// *************************************************************************** *
// *                                                                           *
// *                      Mentor Graphics Corporation                          *
// *                          All rights reserved                              *
// *                                                                           *
// *************************************************************************** *
// *                                                                           *
// * Description:         Partial CANDB File (for ADD Node)                    *
// * Generated at:        2024-09-06 15:47                                     *
// * Node                 ADD                                                  *
// *                                                                           *
// *************************************************************************** *
// *                                                                           *
// *             THIS CONFIGURATION MIGHT CONTAIN SOME ERRORS                  *
// *              IF THE INPUT MODEL WAS NOT PROPERLY FORMED!                  *
// *                    Do Not Use this File directly!                         *
// *                                                                           *
// *************************************************************************** *
VERSION "ADD"

NS_ :

BS_ :

BU_ : ADD

BO_ 1327 ADDAdasCanfdNMFrb : 8 ADD
 SG_ ADDCANActiveWakeup1 : 12|1@0+ (1,0) [0|1] "" Vector__XXX
 SG_ ADDCANNodeAddress1 : 7|8@0+ (1.0,0.0) [0.0|255.0] "" Vector__XXX
 SG_ ADDCANRepeatMsgReq1 : 8|1@0+ (1,0) [0|1] "" Vector__XXX
 SG_ ADDCANRepeatMsgSt1 : 16|1@0+ (1,0) [0|1] "" Vector__XXX
 SG_ NMKeepAwkRsnADD : 48|9@0+ (1.0,0.0) [0.0|511.0] "" Vector__XXX
 SG_ UDB17ADD : 17|1@0+ (1.0,0.0) [0.0|1.0] "" Vector__XXX
 SG_ UDB18ADD : 18|1@0+ (1,0) [0|1] "" Vector__XXX
 SG_ UDB19ADD : 19|1@0+ (1,0) [0|1] "" Vector__XXX
 SG_ UDB20ADD : 20|1@0+ (1,0) [0|1] "" Vector__XXX
 SG_ UDB21ADD : 21|1@0+ (1,0) [0|1] "" Vector__XXX
 SG_ UDB22ADD : 22|1@0+ (1,0) [0|1] "" Vector__XXX
 SG_ UDB23ADD : 23|1@0+ (1,0) [0|1] "" Vector__XXX
 SG_ UDB24ADD : 24|1@0+ (1,0) [0|1] "" Vector__XXX
 SG_ UDB25ADD : 25|1@0+ (1,0) [0|1] "" Vector__XXX
 SG_ UDB26ADD : 26|1@0+ (1,0) [0|1] "" Vector__XXX
 SG_ UDB27ADD : 27|1@0+ (1,0) [0|1] "" Vector__XXX
 SG_ UDB28ADD : 28|1@0+ (1,0) [0|1] "" Vector__XXX
 SG_ UDB29ADD : 29|1@0+ (1,0) [0|1] "" Vector__XXX
 SG_ UDB30ADD : 30|1@0+ (1,0) [0|1] "" Vector__XXX
 SG_ UDB31ADD : 31|1@0+ (1,0) [0|1] "" Vector__XXX
 SG_ UDB32ADD : 32|1@0+ (1,0) [0|1] "" Vector__XXX
 SG_ UDB33ADD : 33|1@0+ (1,0) [0|1] "" Vector__XXX
 SG_ UDB34ADD : 34|1@0+ (1,0) [0|1] "" Vector__XXX
 SG_ UDB35ADD : 35|1@0+ (1,0) [0|1] "" Vector__XXX
 SG_ UDB36ADD : 36|1@0+ (1.0,0.0) [0.0|1.0] "" Vector__XXX
 SG_ UDB37ADD : 37|1@0+ (1,0) [0|1] "" Vector__XXX
 SG_ UDB38ADD : 38|1@0+ (1,0) [0|1] "" Vector__XXX
 SG_ UDB39ADD : 39|1@0+ (1,0) [0|1] "" Vector__XXX
 SG_ UDB40ADD : 40|1@0+ (1,0) [0|1] "" Vector__XXX
 SG_ UDB41ADD : 41|1@0+ (1,0) [0|1] "" Vector__XXX
 SG_ UDB42ADD : 42|1@0+ (1.0,0.0) [0.0|1.0] "" Vector__XXX
 SG_ UDB43ADD : 43|1@0+ (1,0) [0|1] "" Vector__XXX
 SG_ UDB44ADD : 44|1@0+ (1,0) [0|1] "" Vector__XXX
 SG_ UDB45ADD : 45|1@0+ (1,0) [0|1] "" Vector__XXX
 SG_ UDB46ADD : 46|1@0+ (1,0) [0|1] "" Vector__XXX
 SG_ UDB47ADD : 47|1@0+ (1,0) [0|1] "" Vector__XXX

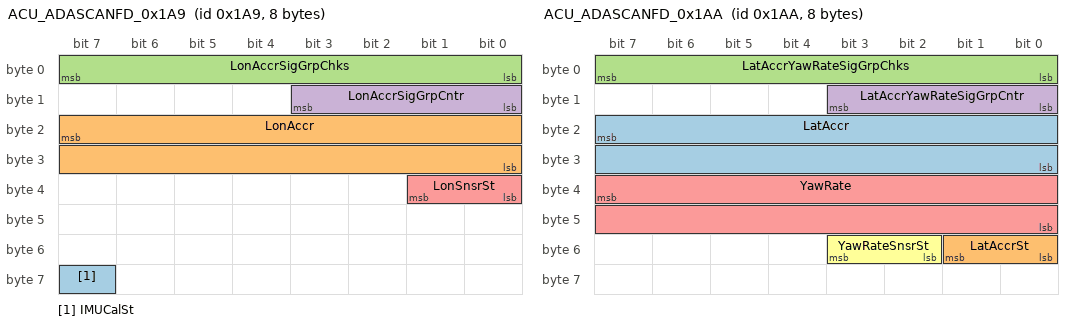
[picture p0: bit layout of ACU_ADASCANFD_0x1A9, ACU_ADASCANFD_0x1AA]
BO_ 425 ACU_ADASCANFD_0x1A9 : 8 Vector__XXX
 SG_ IMUCalSt : 63|1@0+ (1,0) [0|1] "" ADD
 SG_ LonAccr : 23|16@0+ (0.0002,-5.0) [-5.0|5.0] "g" ADD
 SG_ LonAccrSigGrpChks : 7|8@0+ (1,0) [0|255] "" ADD
 SG_ LonAccrSigGrpCntr : 11|4@0+ (1,0) [0|15] "" ADD
 SG_ LonSnsrSt : 33|2@0+ (1,0) [0|3] "" ADD

BO_ 426 ACU_ADASCANFD_0x1AA : 8 Vector__XXX
 SG_ LatAccr : 23|16@0+ (0.0002,-5.0) [-5.0|5.0] "g" ADD
 SG_ LatAccrSt : 49|2@0+ (1,0) [0|3] "" ADD
 SG_ LatAccrYawRateSigGrpChks : 7|8@0+ (1,0) [0|255] "" ADD
 SG_ LatAccrYawRateSigGrpCntr : 11|4@0+ (1,0) [0|15] "" ADD
 SG_ YawRate : 39|16@0+ (0.01,-300.0) [-300.0|300.0] "deg/s" ADD
 SG_ YawRateSnsrSt : 51|2@0+ (1,0) [0|3] "" ADD

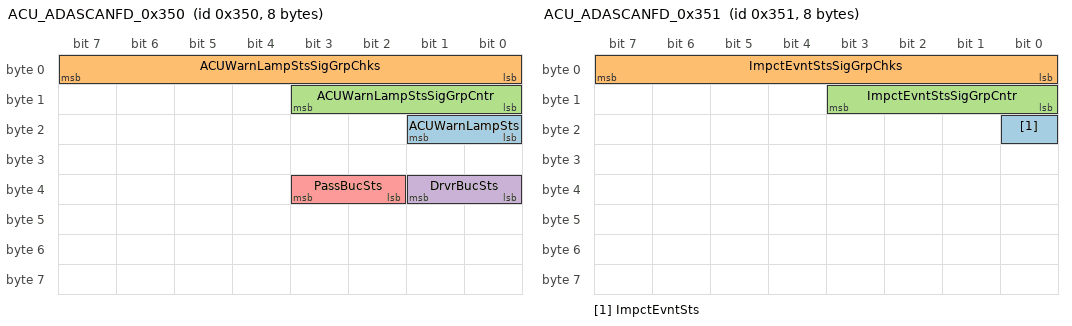
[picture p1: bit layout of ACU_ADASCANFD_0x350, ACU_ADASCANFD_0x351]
BO_ 848 ACU_ADASCANFD_0x350 : 8 Vector__XXX
 SG_ ACUWarnLampSts : 17|2@0+ (1,0) [0|3] "" ADD
 SG_ ACUWarnLampStsSigGrpChks : 7|8@0+ (1.0,0.0) [0.0|255.0] "" ADD
 SG_ ACUWarnLampStsSigGrpCntr : 11|4@0+ (1.0,0.0) [0.0|15.0] "" ADD
 SG_ DrvrBucSts : 33|2@0+ (1,0) [0|3] "" ADD
 SG_ PassBucSts : 35|2@0+ (1,0) [0|3] "" ADD

BO_ 849 ACU_ADASCANFD_0x351 : 8 Vector__XXX
 SG_ ImpctEvntSts : 16|1@0+ (1,0) [0|1] "" ADD
 SG_ ImpctEvntStsSigGrpChks : 7|8@0+ (1,0) [0|255] "" ADD
 SG_ ImpctEvntStsSigGrpCntr : 11|4@0+ (1,0) [0|15] "" ADD

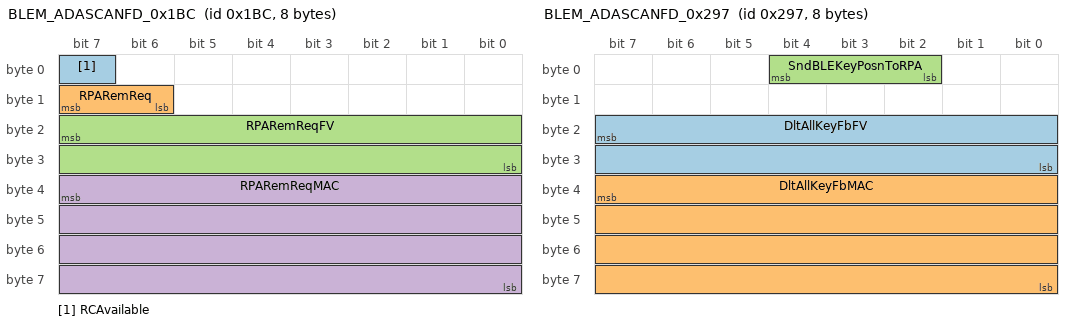
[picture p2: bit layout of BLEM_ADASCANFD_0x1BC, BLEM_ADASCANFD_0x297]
BO_ 444 BLEM_ADASCANFD_0x1BC : 8 Vector__XXX
 SG_ RCAvailable : 7|1@0+ (1,0) [0|1] "" ADD
 SG_ RPARemReq : 15|2@0+ (1,0) [0|3] "" ADD
 SG_ RPARemReqFV : 23|16@0+ (1.0,0.0) [0.0|65535.0] "" ADD
 SG_ RPARemReqMAC : 39|32@0+ (1.0,0.0) [0.0|0.0] "" ADD

BO_ 657 BLEM_ADASCANFD_0x291 : 64 Vector__XXX
 SG_ BLEM2VCCDForLocn10 : 7|32@0+ (1.0,0.0) [0.0|4294967295.0] "" ADD
 SG_ BLEM2VCCDForLocn11 : 39|32@0+ (1.0,0.0) [0.0|4294967295.0] "" ADD
 SG_ BLEM2VCCDForLocn12 : 71|32@0+ (1.0,0.0) [0.0|4294967295.0] "" ADD
 SG_ BLEM2VCCDForLocn13 : 103|32@0+ (1.0,0.0) [0.0|4294967295.0] "" ADD
 SG_ BLEM2VCCDForLocn14 : 135|32@0+ (1.0,0.0) [0.0|4294967295.0] "" ADD
 SG_ BLEM2VCCDForLocn15 : 167|32@0+ (1.0,0.0) [0.0|4294967295.0] "" ADD
 SG_ BLEM2VCCDForLocn16 : 199|32@0+ (1.0,0.0) [0.0|4294967295.0] "" ADD
 SG_ BLEM2VCCDForLocn17 : 231|32@0+ (1.0,0.0) [0.0|4294967295.0] "" ADD
 SG_ BLEM2VCCDForLocn18 : 263|32@0+ (1.0,0.0) [0.0|4294967295.0] "" ADD
 SG_ BLEM2VCCDForLocn19 : 295|32@0+ (1.0,0.0) [0.0|4294967295.0] "" ADD
 SG_ BLEM2VCCDForLocn1A : 327|32@0+ (1.0,0.0) [0.0|4294967295.0] "" ADD
 SG_ BLEM2VCCDForLocn1B : 359|32@0+ (1.0,0.0) [0.0|4294967295.0] "" ADD
 SG_ BLEM2VCCDForLocn1C : 391|32@0+ (1.0,0.0) [0.0|4294967295.0] "" ADD
 SG_ BLEM2VCCDForLocn1D : 423|32@0+ (1.0,0.0) [0.0|4294967295.0] "" ADD
 SG_ BLEM2VCCDForLocn1F : 455|16@0+ (1.0,0.0) [0.0|65535.0] "" ADD

BO_ 663 BLEM_ADASCANFD_0x297 : 8 Vector__XXX
 SG_ DltAllKeyFbFV : 23|16@0+ (1.0,0.0) [0.0|65535.0] "" ADD
 SG_ DltAllKeyFbMAC : 39|32@0+ (1.0,0.0) [0.0|0.0] "" ADD
 SG_ SndBLEKeyPosnToRPA : 4|3@0+ (1,0) [0|7] "" ADD

BO_ 665 BLEM_ADASCANFD_0x299 : 64 Vector__XXX
 SG_ BLEM2VCCDForLocn20 : 7|32@0+ (1.0,0.0) [0.0|4294967295.0] "" ADD
 SG_ BLEM2VCCDForLocn21 : 39|32@0+ (1.0,0.0) [0.0|4294967295.0] "" ADD
 SG_ BLEM2VCCDForLocn22 : 71|32@0+ (1.0,0.0) [0.0|4294967295.0] "" ADD
 SG_ BLEM2VCCDForLocn23 : 103|32@0+ (1.0,0.0) [0.0|4294967295.0] "" ADD
 SG_ BLEM2VCCDForLocn24 : 135|32@0+ (1.0,0.0) [0.0|4294967295.0] "" ADD
 SG_ BLEM2VCCDForLocn25 : 167|32@0+ (1.0,0.0) [0.0|4294967295.0] "" ADD
 SG_ BLEM2VCCDForLocn26 : 199|32@0+ (1.0,0.0) [0.0|4294967295.0] "" ADD
 SG_ BLEM2VCCDForLocn27 : 231|32@0+ (1.0,0.0) [0.0|4294967295.0] "" ADD
 SG_ BLEM2VCCDForLocn28 : 263|32@0+ (1.0,0.0) [0.0|4294967295.0] "" ADD
 SG_ BLEM2VCCDForLocn29 : 295|32@0+ (1.0,0.0) [0.0|4294967295.0] "" ADD
 SG_ BLEM2VCCDForLocn2A : 327|32@0+ (1.0,0.0) [0.0|4294967295.0] "" ADD
 SG_ BLEM2VCCDForLocn2B : 359|32@0+ (1.0,0.0) [0.0|4294967295.0] "" ADD
 SG_ BLEM2VCCDForLocn2C : 391|32@0+ (1.0,0.0) [0.0|4294967295.0] "" ADD
 SG_ BLEM2VCCDForLocn2D : 423|32@0+ (1.0,0.0) [0.0|4294967295.0] "" ADD
 SG_ BLEM2VCCDForLocn2F : 455|16@0+ (1.0,0.0) [0.0|65535.0] "" ADD

BO_ 817 BLEM_ADASCANFD_0x331 : 64 Vector__XXX
 SG_ BLEM2VCCDForLocn40 : 135|32@0+ (1.0,0.0) [0.0|4294967295.0] "" ADD
 SG_ BLEM2VCCDForLocn41 : 167|32@0+ (1.0,0.0) [0.0|4294967295.0] "" ADD
 SG_ BLEM2VCCDForLocn42 : 199|32@0+ (1.0,0.0) [0.0|4294967295.0] "" ADD
 SG_ BLEM2VCCDForLocn43 : 231|32@0+ (1.0,0.0) [0.0|4294967295.0] "" ADD
 SG_ BLEM2VCCDForLocn44 : 7|32@0+ (1.0,0.0) [0.0|4294967295.0] "" ADD
 SG_ BLEM2VCCDForLocn45 : 39|32@0+ (1.0,0.0) [0.0|4294967295.0] "" ADD
 SG_ BLEM2VCCDForLocn46 : 71|32@0+ (1.0,0.0) [0.0|4294967295.0] "" ADD
 SG_ BLEM2VCCDForLocn47 : 103|32@0+ (1.0,0.0) [0.0|4294967295.0] "" ADD
 SG_ BLEM2VCCDForLocn48 : 263|32@0+ (1.0,0.0) [0.0|4294967295.0] "" ADD
 SG_ BLEM2VCCDForLocn49 : 295|32@0+ (1.0,0.0) [0.0|4294967295.0] "" ADD
 SG_ BLEM2VCCDForLocn4A : 327|32@0+ (1.0,0.0) [0.0|4294967295.0] "" ADD
 SG_ BLEM2VCCDForLocn4B : 359|32@0+ (1.0,0.0) [0.0|4294967295.0] "" ADD
 SG_ BLEM2VCCDForLocn4C : 391|32@0+ (1.0,0.0) [0.0|4294967295.0] "" ADD
 SG_ BLEM2VCCDForLocn4D : 423|32@0+ (1.0,0.0) [0.0|4294967295.0] "" ADD
 SG_ BLEM2VCCDForLocn4F : 455|16@0+ (1.0,0.0) [0.0|65535.0] "" ADD

BO_ 825 BLEM_ADASCANFD_0x339 : 32 Vector__XXX
 SG_ BLEM2ADDForRPA00 : 7|64@0+ (1,0) [0|18446744073709551615] "" ADD
 SG_ BLEM2ADDForRPA00FV : 215|16@0+ (1.0,0.0) [0.0|65535.0] "" ADD
 SG_ BLEM2ADDForRPA00MAC : 231|32@0+ (1.0,0.0) [0.0|0.0] "" ADD
 SG_ BLEM2ADDForRPA01 : 71|64@0+ (1,0) [0|18446744073709551615] "" ADD
 SG_ BLEM2ADDForRPA02 : 135|64@0+ (1,0) [0|18446744073709551615] "" ADD
 SG_ BLEM2ADDForRPA03 : 199|16@0+ (1.0,0.0) [0.0|65535.0] "" ADD

BO_ 826 BLEM_ADASCANFD_0x33A : 64 Vector__XXX
 SG_ BLEM2VCCDForLocn30 : 7|32@0+ (1.0,0.0) [0.0|4294967295.0] "" ADD
 SG_ BLEM2VCCDForLocn31 : 39|32@0+ (1.0,0.0) [0.0|4294967295.0] "" ADD
 SG_ BLEM2VCCDForLocn32 : 71|32@0+ (1.0,0.0) [0.0|4294967295.0] "" ADD
 SG_ BLEM2VCCDForLocn33 : 103|32@0+ (1.0,0.0) [0.0|4294967295.0] "" ADD
 SG_ BLEM2VCCDForLocn34 : 135|32@0+ (1.0,0.0) [0.0|4294967295.0] "" ADD
 SG_ BLEM2VCCDForLocn35 : 167|32@0+ (1.0,0.0) [0.0|4294967295.0] "" ADD
 SG_ BLEM2VCCDForLocn36 : 199|32@0+ (1.0,0.0) [0.0|4294967295.0] "" ADD
 SG_ BLEM2VCCDForLocn37 : 231|32@0+ (1.0,0.0) [0.0|4294967295.0] "" ADD
 SG_ BLEM2VCCDForLocn38 : 263|32@0+ (1.0,0.0) [0.0|4294967295.0] "" ADD
 SG_ BLEM2VCCDForLocn39 : 295|32@0+ (1.0,0.0) [0.0|4294967295.0] "" ADD
 SG_ BLEM2VCCDForLocn3A : 327|32@0+ (1.0,0.0) [0.0|4294967295.0] "" ADD
 SG_ BLEM2VCCDForLocn3B : 359|32@0+ (1.0,0.0) [0.0|4294967295.0] "" ADD
 SG_ BLEM2VCCDForLocn3C : 391|32@0+ (1.0,0.0) [0.0|4294967295.0] "" ADD
 SG_ BLEM2VCCDForLocn3D : 423|32@0+ (1.0,0.0) [0.0|4294967295.0] "" ADD
 SG_ BLEM2VCCDForLocn3F : 455|16@0+ (1.0,0.0) [0.0|65535.0] "" ADD

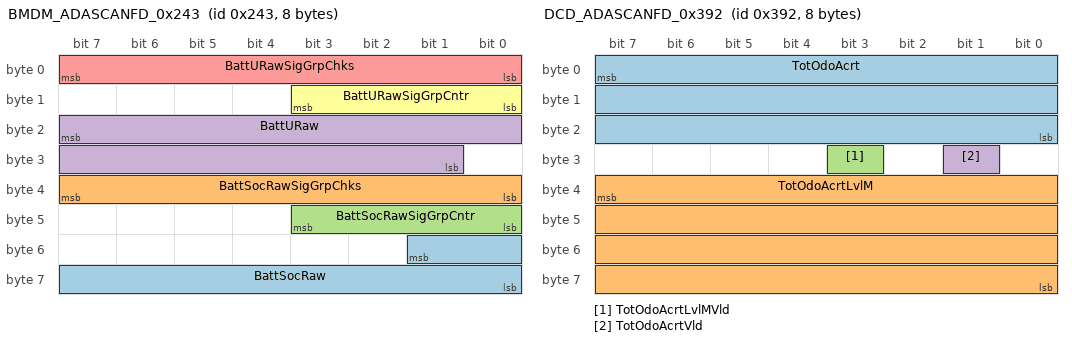
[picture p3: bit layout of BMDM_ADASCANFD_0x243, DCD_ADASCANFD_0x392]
BO_ 579 BMDM_ADASCANFD_0x243 : 8 Vector__XXX
 SG_ BattSocRaw : 49|10@0+ (0.1,0.0) [0.0|102.30000000000001] "%" ADD
 SG_ BattSocRawSigGrpChks : 39|8@0+ (1.0,0.0) [0.0|255.0] "" ADD
 SG_ BattSocRawSigGrpCntr : 43|4@0+ (1.0,0.0) [0.0|15.0] "" ADD
 SG_ BattURaw : 23|15@0+ (0.001,0.0) [0.0|18.0] "V" ADD
 SG_ BattURawSigGrpChks : 7|8@0+ (1,0) [0|255] "" ADD
 SG_ BattURawSigGrpCntr : 11|4@0+ (1,0) [0|15] "" ADD

BO_ 549 DCD_ADASCANFD_0x225 : 16 Vector__XXX
 SG_ ADSELKSwtSet : 46|2@0+ (1,0) [0|3] "" ADD
 SG_ ADSFltQuitReqFrmDCD : 44|2@0+ (1,0) [0|3] "" ADD
 SG_ DCDDisplayFailSts : 42|3@0+ (1,0) [0|7] "" ADD
 SG_ DCDDltAllKeyCmdFV : 87|16@0+ (1.0,0.0) [0.0|65535.0] "" ADD
 SG_ DCDDltAllKeyCmdMAC : 103|32@0+ (1.0,0.0) [0.0|0.0] "" ADD
 SG_ DCDSteerWhlExtrMirrHUDAdjFlg : 39|3@0+ (1,0) [0|7] "" ADD

BO_ 720 DCD_ADASCANFD_0x2D0 : 48 Vector__XXX
 SG_ DCDDMSCameraFltSts : 104|1@0+ (1,0) [0|1] "" ADD
 SG_ DCDDMSdstrctnDetnSts : 60|1@0+ (1,0) [0|1] "" ADD
 SG_ DCDDMSdstrctnSts : 106|2@0+ (1,0) [0|3] "" ADD
 SG_ DCDDMSFatgDetnSts : 61|1@0+ (1,0) [0|1] "" ADD
 SG_ DCDDMSfatgSts : 108|2@0+ (1,0) [0|3] "" ADD
 SG_ DCDDMSSigGrpChks : 95|8@0+ (1,0) [0|255] "" ADD
 SG_ DCDDMSSigGrpCntr : 99|4@0+ (1,0) [0|15] "" ADD
 SG_ DCDDMSSysFltSts : 109|1@0+ (1,0) [0|1] "" ADD
 SG_ DCDDVRSrvReq : 62|1@0+ (1,0) [0|1] "" ADD
 SG_ DCDGameModSts : 121|1@0+ (1,0) [0|1] "" ADD
 SG_ DCDPrivacyModeStatus : 57|2@0+ (1,0) [0|3] "" ADD
 SG_ DCDsentryModReq : 67|1@0+ (1,0) [0|1] "" ADD
 SG_ DCDsentryModSts : 71|3@0+ (1,0) [0|7] "" ADD
 SG_ DCDTSASLIFSwtSts : 135|2@0+ (1,0) [0|3] "" ADD
 SG_ SRMode : 116|2@0+ (1,0) [0|3] "" ADD

BO_ 833 DCD_ADASCANFD_0x341 : 32 Vector__XXX
 SG_ ALCLrnSts : 239|1@0+ (1,0) [0|1] "" ADD
 SG_ AVPLrnSts : 237|1@0+ (1,0) [0|1] "" ADD
 SG_ DCDAdCode : 147|20@0+ (1,0) [0|1048575] "" ADD
 SG_ DCDCameraSpdLim : 175|8@0+ (1,0) [0|255] "" ADD
 SG_ DCDNavSts : 177|2@0+ (1,0) [0|3] "" ADD
 SG_ DCDRoadClass : 181|4@0+ (1,0) [0|15] "" ADD
 SG_ DCDRoadFacSpdLim : 191|8@0+ (1,0) [0|255] "" ADD
 SG_ DCDRoadType : 197|6@0+ (1,0) [0|63] "" ADD
 SG_ DCDTrfcSts : 203|4@0+ (1,0) [0|15] "" ADD
 SG_ DCDTSASlifSpdDisp : 0|9@0+ (1,0) [0|511] "" ADD
 SG_ DstUnitDisp : 84|1@0+ (1,0) [0|1] "" ADD
 SG_ HPPLrnSts : 236|1@0+ (1,0) [0|1] "" ADD
 SG_ LrnStsSigGrpChks : 223|8@0+ (1.0,0.0) [0.0|255.0] "" ADD
 SG_ LrnStsSigGrpCntr : 227|4@0+ (1.0,0.0) [0.0|15.0] "" ADD
 SG_ NOACtyLrnSts : 235|1@0+ (1,0) [0|1] "" ADD
 SG_ NOAHWLrnSts : 234|1@0+ (1,0) [0|1] "" ADD
 SG_ PltLrnSts : 233|1@0+ (1,0) [0|1] "" ADD
 SG_ VehInsSpdDisp : 40|9@0+ (1.0,0.0) [0.0|504.0] "kph" ADD
 SG_ VehInsSpdDispIntnal : 63|16@0+ (0.05625,0.0) [0.0|504.0] "kph" ADD
 SG_ VehInsSpdDispVld : 4|1@0+ (1,0) [0|1] "" ADD

BO_ 837 DCD_ADASCANFD_0x345 : 32 Vector__XXX
 SG_ DCDAccountLogTyp : 55|4@0+ (1,0) [0|15] "" ADD
 SG_ DCDAcctMod : 48|1@0+ (1,0) [0|1] "" ADD
 SG_ DCDCloudSysnc : 51|1@0+ (1,0) [0|1] "" ADD
 SG_ DCDCurProID : 23|32@0+ (1.0,0.0) [0.0|4294967295.0] "" ADD
 SG_ DCDGstMod : 13|2@0+ (1,0) [0|3] "" ADD
 SG_ DCDICVehCustExperImprvProgSts : 11|2@0+ (1,0) [0|3] "" ADD
 SG_ DCDICVehSrvAuthntSts : 9|2@0+ (1,0) [0|3] "" ADD
 SG_ DCDUserIDBytePos0 : 183|8@0+ (1.0,0.0) [0.0|255.0] "" ADD
 SG_ DCDUserIDBytePos1 : 175|8@0+ (1.0,0.0) [0.0|255.0] "" ADD
 SG_ DCDUserIDBytePos10 : 103|8@0+ (1.0,0.0) [0.0|255.0] "" ADD
 SG_ DCDUserIDBytePos11 : 95|8@0+ (1.0,0.0) [0.0|255.0] "" ADD
 SG_ DCDUserIDBytePos12 : 87|8@0+ (1.0,0.0) [0.0|255.0] "" ADD
 SG_ DCDUserIDBytePos13 : 79|8@0+ (1.0,0.0) [0.0|255.0] "" ADD
 SG_ DCDUserIDBytePos14 : 71|8@0+ (1.0,0.0) [0.0|255.0] "" ADD
 SG_ DCDUserIDBytePos15 : 63|8@0+ (1.0,0.0) [0.0|255.0] "" ADD
 SG_ DCDUserIDBytePos2 : 167|8@0+ (1.0,0.0) [0.0|255.0] "" ADD
 SG_ DCDUserIDBytePos3 : 159|8@0+ (1.0,0.0) [0.0|255.0] "" ADD
 SG_ DCDUserIDBytePos4 : 151|8@0+ (1.0,0.0) [0.0|255.0] "" ADD
 SG_ DCDUserIDBytePos5 : 143|8@0+ (1.0,0.0) [0.0|255.0] "" ADD
 SG_ DCDUserIDBytePos6 : 135|8@0+ (1.0,0.0) [0.0|255.0] "" ADD
 SG_ DCDUserIDBytePos7 : 127|8@0+ (1.0,0.0) [0.0|255.0] "" ADD
 SG_ DCDUserIDBytePos8 : 119|8@0+ (1.0,0.0) [0.0|255.0] "" ADD
 SG_ DCDUserIDBytePos9 : 111|8@0+ (1.0,0.0) [0.0|255.0] "" ADD

BO_ 914 DCD_ADASCANFD_0x392 : 8 Vector__XXX
 SG_ TotOdoAcrt : 7|24@0+ (0.1,0.0) [0.0|1677721.5] "km" ADD
 SG_ TotOdoAcrtLvlM : 39|32@0+ (1.0,0.0) [0.0|4294967295.0] "m" ADD
 SG_ TotOdoAcrtLvlMVld : 27|1@0+ (1,0) [0|1] "" ADD
 SG_ TotOdoAcrtVld : 25|1@0+ (1,0) [0|1] "" ADD

BO_ 932 DCD_ADASCANFD_0x3A4 : 32 Vector__XXX
 SG_ ADSAEBFCWSwtSet : 114|3@0+ (1,0) [0|7] "" ADD
 SG_ ADSAESESSSwtSet : 33|2@0+ (1,0) [0|3] "" ADD
 SG_ ADSAPPOpenReq : 132|2@0+ (1,0) [0|3] "" ADD
 SG_ ADSBSDLCASwtSet : 39|3@0+ (1,0) [0|7] "" ADD
 SG_ ADSDOWSwtSet : 41|2@0+ (1,0) [0|3] "" ADD
 SG_ ADSPMAEBSwtSet : 35|2@0+ (1,0) [0|3] "" ADD
 SG_ ADSRCWSwtSet : 167|2@0+ (1,0) [0|3] "" ADD
 SG_ ADSTLASwtSet : 31|2@0+ (1,0) [0|3] "" ADD
 SG_ ADSVcCtrlSwtSet : 5|2@0+ (1,0) [0|3] "" ADD
 SG_ APASwtSet : 49|2@0+ (1,0) [0|3] "" ADD
 SG_ AVPSwtSet : 45|2@0+ (1,0) [0|3] "" ADD
 SG_ DCD2RDParkinChoseButton : 103|2@0+ (1,0) [0|3] "" ADD
 SG_ DCDACCInitSpdSwtSet : 51|2@0+ (1,0) [0|3] "" ADD
 SG_ DCDAdsAutoTurnLiSwtSet : 161|2@0+ (1.0,0.0) [0.0|3.0] "" ADD
 SG_ DCDAdsIntelgntSpdSwtSet : 165|2@0+ (1.0,0.0) [0.0|2.0] "" ADD
 SG_ DCDADSMAISwtSet : 57|2@0+ (1.0,0.0) [0.0|2.0] "" ADD
 SG_ DCDAdsModSwtSet : 159|2@0+ (1,0) [0|3] "" ADD
 SG_ DCDAdsNOAOddSwtSet : 157|2@0+ (1,0) [0|3] "" ADD
 SG_ DCDADSRCTABSwtSet : 15|2@0+ (1,0) [0|3] "" ADD
 SG_ DCDAdsTrfcLiCtrlSwtSet : 155|2@0+ (1,0) [0|3] "" ADD
 SG_ DCDADSVcCtrlDstSet : 77|2@0+ (1,0) [0|3] "" ADD
 SG_ DCDADSVcCtrlSpdSet : 75|2@0+ (1,0) [0|3] "" ADD
 SG_ DCDAdsVehDeturSwtSet : 153|2@0+ (1,0) [0|3] "" ADD
 SG_ DCDAPAButton : 101|2@0+ (1,0) [0|3] "" ADD
 SG_ DCDAPAParkOutButton : 163|2@0+ (1,0) [0|3] "" ADD
 SG_ DCDAPAParkOutDireSelect : 111|4@0+ (1,0) [0|15] "" ADD
 SG_ DCDAPAParkSlotSelect : 119|5@0+ (1,0) [0|31] "" ADD
 SG_ DCDAPAPIPOReq : 107|2@0+ (1,0) [0|3] "" ADD
 SG_ DCDAPAQuitReq : 105|1@0+ (1,0) [0|1] "" ADD
 SG_ DCDAPAVcCtl : 122|3@0+ (1,0) [0|7] "" ADD
 SG_ DCDAudModSwtSet : 55|3@0+ (1,0) [0|7] "" ADD
 SG_ DCDAutoVehCustExperImprvProgSwt : 23|2@0+ (1,0) [0|3] "" ADD
 SG_ DCDAutoVehSrvAuthntSwt : 21|2@0+ (1,0) [0|3] "" ADD
 SG_ DCDBackMapDfltParkSlotReq : 130|1@0+ (1,0) [0|1] "" ADD
 SG_ DCDFxdSpdModValSwtSet : 29|6@0+ (1,0) [0|63] "" ADD
 SG_ DCDHPPBckGrLearSwtSet : 59|2@0+ (1,0) [0|3] "" ADD
 SG_ DCDHPPBckGrPathAutDoLoSet : 61|2@0+ (1,0) [0|3] "" ADD
 SG_ DCDHPPChoseSaveRoute : 129|2@0+ (1,0) [0|3] "" ADD
 SG_ DCDHPPLnVcReq : 71|2@0+ (1,0) [0|3] "" ADD
 SG_ DCDHPPLrnReq : 135|3@0+ (1,0) [0|7] "" ADD
 SG_ DCDHPPParkAlTheWay : 140|2@0+ (1,0) [0|3] "" ADD
 SG_ DCDHPPParkingButton : 138|2@0+ (1,0) [0|3] "" ADD
 SG_ DCDHPPPrkReq : 143|3@0+ (1,0) [0|7] "" ADD
 SG_ DCDLdwLdpWarnTypSwtSet : 63|2@0+ (1,0) [0|3] "" ADD
 SG_ DCDLVPwrSwtSet : 65|2@0+ (1,0) [0|3] "" ADD
 SG_ DCDParkAudModSwtSet : 9|2@0+ (1,0) [0|3] "" ADD
 SG_ DCDParkSpdSwtSet : 83|3@0+ (1.0,0.0) [0.0|6.0] "" ADD
 SG_ DCDPcntgeSpdModValSwtSet : 127|5@0+ (1,0) [0|31] "" ADD
 SG_ DCDPntCldSwtSet : 85|2@0+ (1,0) [0|3] "" ADD
 SG_ DCDTouchdSpdTyp : 67|2@0+ (1,0) [0|3] "" ADD
 SG_ HPPSwtSet : 43|2@0+ (1,0) [0|3] "" ADD
 SG_ HwNOASwtSet : 13|2@0+ (1,0) [0|3] "" ADD
 SG_ LdwLdpSwtSet : 19|2@0+ (1,0) [0|3] "" ADD
 SG_ LidarCloudMode : 3|3@0+ (1,0) [0|7] "" ADD
 SG_ NoaLcSwtSet : 17|2@0+ (1.0,0.0) [0.0|2.0] "" ADD
 SG_ PltSwtALCSet : 11|2@0+ (1,0) [0|3] "" ADD
 SG_ PltSwtSet : 7|2@0+ (1,0) [0|3] "" ADD
 SG_ ScrnTouchdFuncChange : 95|2@0+ (1,0) [0|3] "" ADD
 SG_ ScrnTouchdLaneChange : 93|2@0+ (1,0) [0|3] "" ADD
 SG_ ScrnTouchdSpd : 136|9@0+ (1.0,0.0) [0.0|255.0] "kph" ADD
 SG_ ScrnTouchdSpdTyp : 91|2@0+ (1,0) [0|3] "" ADD
 SG_ VehSpdDvtionModSwtSet : 87|2@0+ (1,0) [0|3] "" ADD

BO_ 784 FZCU_ADASCANFD_0x310 : 24 Vector__XXX
 SG_ EdsCircCooltTSnsrU : 183|16@0+ (0.1,0.0) [0.0|5000.0] "mV" ADD
 SG_ FLRLLoPwrSplySts : 0|1@0+ (1,0) [0|1] "" ADD
 SG_ IMULoPwrSplySts : 1|1@0+ (1,0) [0|1] "" ADD
 SG_ LRRLoPwrSplySts : 4|1@0+ (1,0) [0|1] "" ADD
 SG_ LSLLoPwrSplySts : 3|1@0+ (1,0) [0|1] "" ADD
 SG_ RSLLoPwrSplySts : 2|1@0+ (1,0) [0|1] "" ADD

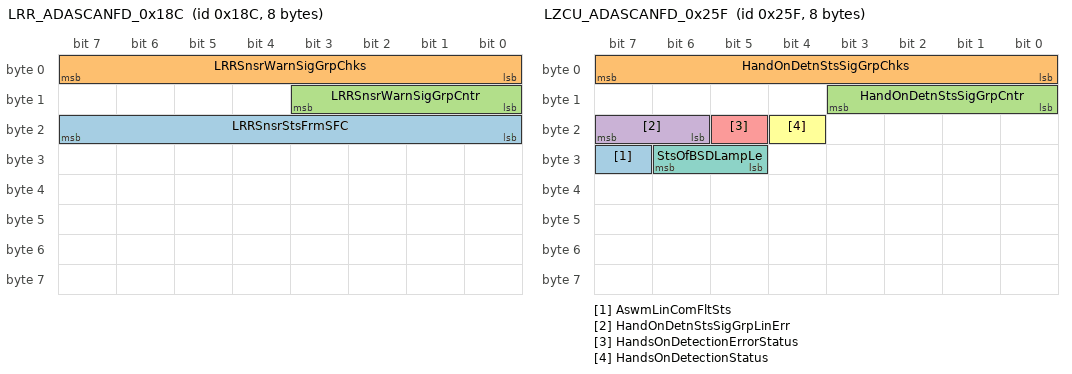
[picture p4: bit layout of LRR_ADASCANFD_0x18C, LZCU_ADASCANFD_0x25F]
BO_ 396 LRR_ADASCANFD_0x18C : 8 Vector__XXX
 SG_ LRRSnsrStsFrmSFC : 23|8@0+ (1.0,0.0) [0.0|255.0] "" ADD
 SG_ LRRSnsrWarnSigGrpChks : 7|8@0+ (1.0,0.0) [0.0|255.0] "" ADD
 SG_ LRRSnsrWarnSigGrpCntr : 11|4@0+ (1.0,0.0) [0.0|15.0] "" ADD

BO_ 434 LZCU_ADASCANFD_0x1B2 : 32 Vector__XXX
 SG_ DoorDrvrPwrRelsMotDrvSts : 255|3@0+ (1,0) [0|7] "" ADD
 SG_ PwrRelsMotDrvStsGrpChks : 247|8@0+ (1.0,0.0) [0.0|255.0] "" ADD
 SG_ PwrRelsMotDrvStsGrpCntr : 251|4@0+ (1.0,0.0) [0.0|15.0] "" ADD

BO_ 607 LZCU_ADASCANFD_0x25F : 8 Vector__XXX
 SG_ AswmLinComFltSts : 31|1@0+ (1,0) [0|1] "" ADD
 SG_ HandOnDetnStsSigGrpChks : 7|8@0+ (1.0,0.0) [0.0|255.0] "" ADD
 SG_ HandOnDetnStsSigGrpCntr : 11|4@0+ (1.0,0.0) [0.0|15.0] "" ADD
 SG_ HandOnDetnStsSigGrpLinErr : 23|2@0+ (1,0) [0|3] "" ADD
 SG_ HandsOnDetectionErrorStatus : 21|1@0+ (1,0) [0|1] "" ADD
 SG_ HandsOnDetectionStatus : 20|1@0+ (1,0) [0|1] "" ADD
 SG_ StsOfBSDLampLe : 30|2@0+ (1,0) [0|3] "" ADD

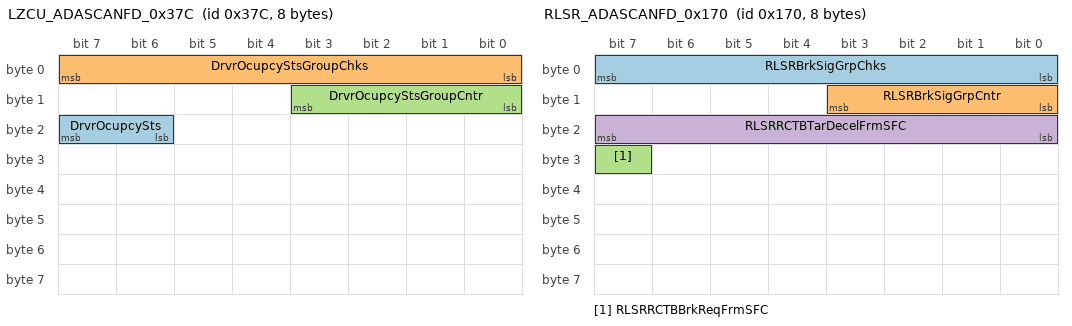
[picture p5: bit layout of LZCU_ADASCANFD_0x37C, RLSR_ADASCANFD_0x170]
BO_ 892 LZCU_ADASCANFD_0x37C : 8 Vector__XXX
 SG_ DrvrOcupcySts : 23|2@0+ (1,0) [0|3] "" ADD
 SG_ DrvrOcupcyStsGroupChks : 7|8@0+ (1,0) [0|255] "" ADD
 SG_ DrvrOcupcyStsGroupCntr : 11|4@0+ (1,0) [0|15] "" ADD

BO_ 368 RLSR_ADASCANFD_0x170 : 8 Vector__XXX
 SG_ RLSRBrkSigGrpChks : 7|8@0+ (1.0,0.0) [0.0|255.0] "" ADD
 SG_ RLSRBrkSigGrpCntr : 11|4@0+ (1.0,0.0) [0.0|15.0] "" ADD
 SG_ RLSRRCTBBrkReqFrmSFC : 31|1@0+ (1,0) [0|1] "" ADD
 SG_ RLSRRCTBTarDecelFrmSFC : 23|8@0+ (0.05,-10.0) [-10.0|2.75] "mps2" ADD

BO_ 391 RLSR_ADASCANFD_0x187 : 16 Vector__XXX
 SG_ RLSRBSDLCAStsFrmSFC : 21|2@0+ (1,0) [0|3] "" ADD
 SG_ RLSRBSDLCASwtFbFrmSFC : 34|3@0+ (1.0,0.0) [0.0|4.0] "" ADD
 SG_ RLSRBSDLCASwtUnavlRsnFrmSFC : 55|4@0+ (1.0,0.0) [0.0|11.0] "" ADD
 SG_ RLSRBSDLCAWarnReqFrmSFC : 23|2@0+ (1,0) [0|3] "" ADD
 SG_ RLSRDOWStsFrmSFC : 17|2@0+ (1,0) [0|3] "" ADD
 SG_ RLSRDOWSwtFbFrmSFC : 46|3@0+ (1.0,0.0) [0.0|4.0] "" ADD
 SG_ RLSRDOWSwtUnavlRsnFrmSFC : 51|4@0+ (1.0,0.0) [0.0|11.0] "" ADD
 SG_ RLSRDOWWarnReqFrFrmSFC : 19|2@0+ (1,0) [0|3] "" ADD
 SG_ RLSRDOWWarnReqReFrmSFC : 31|2@0+ (1,0) [0|3] "" ADD
 SG_ RLSRRCTABSwtFbFrmSFC : 37|3@0+ (1.0,0.0) [0.0|4.0] "" ADD
 SG_ RLSRRCTABSwtUnavlRsnFrmSFC : 63|4@0+ (1.0,0.0) [0.0|11.0] "" ADD
 SG_ RLSRRCTAStsFrmSFC : 13|2@0+ (1,0) [0|3] "" ADD
 SG_ RLSRRCTAWarnReqFrmSFC : 15|2@0+ (1,0) [0|3] "" ADD
 SG_ RLSRRCTBStsFrmSFC : 29|2@0+ (1,0) [0|3] "" ADD
 SG_ RLSRRCTBWarnReqFrmSFC : 43|2@0+ (1,0) [0|3] "" ADD
 SG_ RLSRRCWStsFrmSFC : 25|2@0+ (1,0) [0|3] "" ADD
 SG_ RLSRRCWSwtFbFrmSFC : 41|2@0+ (1,0) [0|3] "" ADD
 SG_ RLSRRCWSwtUnavlRsnFrmSFC : 59|4@0+ (1.0,0.0) [0.0|11.0] "" ADD
 SG_ RLSRRCWWarnReqFrmSFC : 27|2@0+ (1,0) [0|3] "" ADD
 SG_ RLSRWarnSigGrpChks : 7|8@0+ (1,0) [0|255] "" ADD
 SG_ RLSRWarnSigGrpCntr : 11|4@0+ (1,0) [0|15] "" ADD

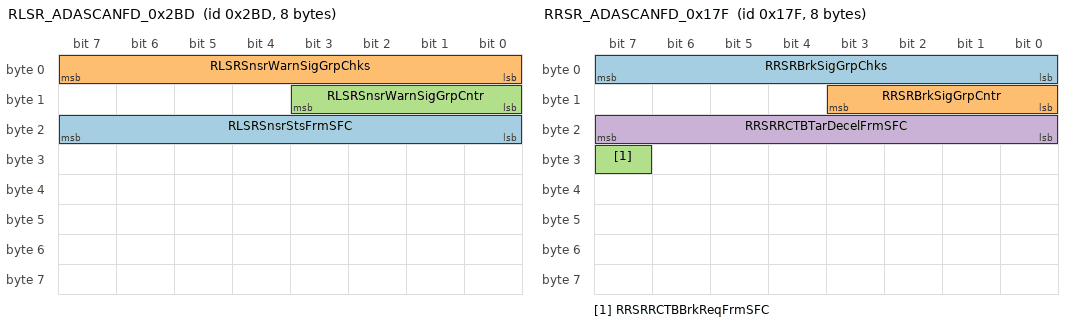
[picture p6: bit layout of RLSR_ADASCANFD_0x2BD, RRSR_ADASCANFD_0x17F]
BO_ 701 RLSR_ADASCANFD_0x2BD : 8 Vector__XXX
 SG_ RLSRSnsrStsFrmSFC : 23|8@0+ (1.0,0.0) [0.0|255.0] "" ADD
 SG_ RLSRSnsrWarnSigGrpChks : 7|8@0+ (1,0) [0|255] "" ADD
 SG_ RLSRSnsrWarnSigGrpCntr : 11|4@0+ (1,0) [0|15] "" ADD

BO_ 383 RRSR_ADASCANFD_0x17F : 8 Vector__XXX
 SG_ RRSRBrkSigGrpChks : 7|8@0+ (1.0,0.0) [0.0|255.0] "" ADD
 SG_ RRSRBrkSigGrpCntr : 11|4@0+ (1.0,0.0) [0.0|15.0] "" ADD
 SG_ RRSRRCTBBrkReqFrmSFC : 31|1@0+ (1,0) [0|1] "" ADD
 SG_ RRSRRCTBTarDecelFrmSFC : 23|8@0+ (0.05,-10.0) [-10.0|2.75] "mps2" ADD

BO_ 392 RRSR_ADASCANFD_0x188 : 16 Vector__XXX
 SG_ RRSRBSDLCAStsFrmSFC : 21|2@0+ (1,0) [0|3] "" ADD
 SG_ RRSRBSDLCASwtFbFrmSFC : 34|3@0+ (1.0,0.0) [0.0|4.0] "" ADD
 SG_ RRSRBSDLCASwtUnavlRsnFrmSFC : 55|4@0+ (1.0,0.0) [0.0|11.0] "" ADD
 SG_ RRSRBSDLCAWarnReqFrmSFC : 23|2@0+ (1,0) [0|3] "" ADD
 SG_ RRSRDOWStsFrmSFC : 17|2@0+ (1,0) [0|3] "" ADD
 SG_ RRSRDOWSwtFbFrmSFC : 46|3@0+ (1.0,0.0) [0.0|4.0] "" ADD
 SG_ RRSRDOWSwtUnavlRsnFrmSFC : 51|4@0+ (1.0,0.0) [0.0|11.0] "" ADD
 SG_ RRSRDOWWarnReqFrFrmSFC : 19|2@0+ (1,0) [0|3] "" ADD
 SG_ RRSRDOWWarnReqReFrmSFC : 31|2@0+ (1,0) [0|3] "" ADD
 SG_ RRSRRCTABSwtFbFrmSFC : 37|3@0+ (1.0,0.0) [0.0|4.0] "" ADD
 SG_ RRSRRCTABSwtUnavlRsnFrmSFC : 63|4@0+ (1.0,0.0) [0.0|11.0] "" ADD
 SG_ RRSRRCTAStsFrmSFC : 13|2@0+ (1,0) [0|3] "" ADD
 SG_ RRSRRCTAWarnReqFrmSFC : 15|2@0+ (1,0) [0|3] "" ADD
 SG_ RRSRRCTBStsFrmSFC : 29|2@0+ (1,0) [0|3] "" ADD
 SG_ RRSRRCTBWarnReqFrmSFC : 43|2@0+ (1,0) [0|3] "" ADD
 SG_ RRSRRCWStsFrmSFC : 25|2@0+ (1,0) [0|3] "" ADD
 SG_ RRSRRCWSwtFbFrmSFC : 41|2@0+ (1,0) [0|3] "" ADD
 SG_ RRSRRCWSwtUnavlRsnFrmSFC : 59|4@0+ (1.0,0.0) [0.0|11.0] "" ADD
 SG_ RRSRRCWWarnReqFrmSFC : 27|2@0+ (1,0) [0|3] "" ADD
 SG_ RRSRWarnSigGrpChks : 7|8@0+ (1,0) [0|255] "" ADD
 SG_ RRSRWarnSigGrpCntr : 11|4@0+ (1,0) [0|15] "" ADD

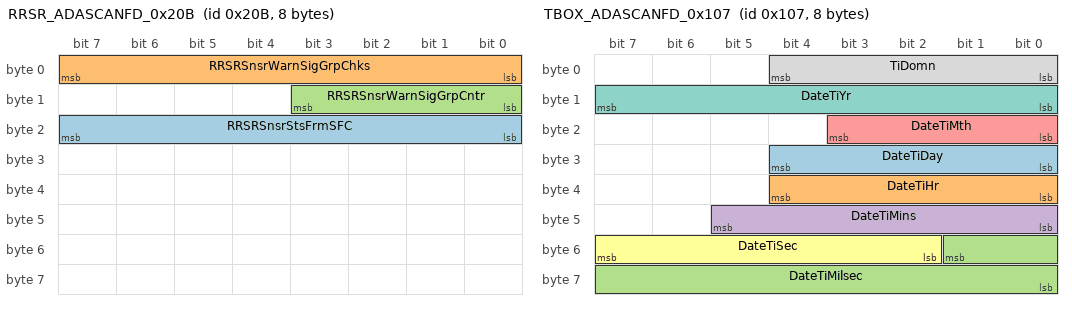
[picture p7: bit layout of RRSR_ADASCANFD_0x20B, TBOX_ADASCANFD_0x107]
BO_ 523 RRSR_ADASCANFD_0x20B : 8 Vector__XXX
 SG_ RRSRSnsrStsFrmSFC : 23|8@0+ (1.0,0.0) [0.0|255.0] "" ADD
 SG_ RRSRSnsrWarnSigGrpChks : 7|8@0+ (1,0) [0|255] "" ADD
 SG_ RRSRSnsrWarnSigGrpCntr : 11|4@0+ (1,0) [0|15] "" ADD

BO_ 602 RZCU_ADASCANFD_0x25A : 16 Vector__XXX
 SG_ RlsRainFallAmnt : 39|4@0+ (1,0) [0|15] "" ADD
 SG_ RlsRainFallSts : 35|4@0+ (1,0) [0|15] "" ADD
 SG_ RlsRainSnsrFlt : 11|1@0+ (1,0) [0|1] "" ADD

BO_ 616 RZCU_ADASCANFD_0x268 : 24 Vector__XXX
 SG_ RlsAutWinWipgSpdCmd : 23|3@0+ (1,0) [0|7] "" ADD
 SG_ RlsFwdLiSnsrVal : 47|15@0+ (6.0,0.0) [0.0|196602.0] "" ADD
 SG_ RlsFwdLiSnsrValUnit : 87|2@0+ (1,0) [0|3] "" ADD
 SG_ RlsHudSnsrVal : 63|15@0+ (6.0,0.0) [0.0|196602.0] "" ADD
 SG_ RlsHudSnsrValUnit : 85|2@0+ (1,0) [0|3] "" ADD
 SG_ RlsIRVal : 79|8@0+ (400.0,0.0) [0.0|101600.0] "" ADD
 SG_ RlsLiSig1GrpChks : 31|8@0+ (1.0,0.0) [0.0|255.0] "" ADD
 SG_ RlsLiSig1GrpCntr : 35|4@0+ (1.0,0.0) [0.0|15.0] "" ADD
 SG_ RlsLiSig2GrpChks : 95|8@0+ (1,0) [0|255] "" ADD
 SG_ RlsLiSig2GrpCntr : 99|4@0+ (1,0) [0|15] "" ADD
 SG_ RlsLiSigGrpLinErr : 111|2@0+ (1,0) [0|3] "" ADD
 SG_ RlsLiSnsrFwdFlt : 83|1@0+ (1,0) [0|1] "" ADD
 SG_ RlsLiSnsrIRFlt : 82|1@0+ (1,0) [0|1] "" ADD
 SG_ RlsLiSnsrTopFlt : 81|1@0+ (1,0) [0|1] "" ADD
 SG_ RlsLiSwtReq : 109|2@0+ (1,0) [0|3] "" ADD
 SG_ RlsOutdBriSts : 107|3@0+ (1,0) [0|7] "" ADD
 SG_ RlsSts : 135|3@0+ (1,0) [0|7] "" ADD
 SG_ RlsTopLiSnsrVal : 119|15@0+ (20.0,0.0) [0.0|655340.0] "" ADD
 SG_ RlsTopLiSnsrValUnit : 132|2@0+ (1,0) [0|3] "" ADD
 SG_ StsOfBSDLampRi : 149|2@0+ (1,0) [0|3] "" ADD

BO_ 768 RZCU_ADASCANFD_0x300 : 8 Vector__XXX
 SG_ RSRLoPwrSplySts : 6|1@0+ (1,0) [0|1] "" ADD

BO_ 893 RZCU_ADASCANFD_0x37D : 8 Vector__XXX
 SG_ PassOcupcySts : 1|2@0+ (1,0) [0|3] "" ADD

BO_ 342 SCU_ADASCANFD_0x156 : 32 Vector__XXX
 SG_ ASCFltSts : 207|2@0+ (1,0) [0|3] "" ADD
 SG_ CDCFltSts : 205|2@0+ (1,0) [0|3] "" ADD
 SG_ CurDampgCtrlMod : 124|2@0+ (1,0) [0|3] "" ADD
 SG_ ESPEnaReq : 203|1@0+ (1,0) [0|1] "" ADD
 SG_ JackModSts : 113|1@0+ (1,0) [0|1] "" ADD
 SG_ LvlAdjmtSts : 91|4@0+ (1,0) [0|15] "" ADD
 SG_ LvlModAct : 135|3@0+ (1,0) [0|7] "" ADD
 SG_ SCUExtmHeiSts : 202|2@0+ (1,0) [0|3] "" ADD
 SG_ SCULimSpdTqReq : 215|1@0+ (1,0) [0|1] "" ADD
 SG_ SCUWarnLampReq : 214|2@0+ (1,0) [0|3] "" ADD
 SG_ SCUWarnMsgASC : 212|3@0+ (1,0) [0|7] "" ADD
 SG_ SCUWarnMsgCDC : 209|2@0+ (1,0) [0|3] "" ADD
 SG_ SCUWarnSigGrpChks : 191|8@0+ (1.0,0.0) [0.0|255.0] "" ADD
 SG_ SCUWarnSigGrpCntr : 195|4@0+ (1.0,0.0) [0.0|15.0] "" ADD

BO_ 182 SCU_ADASCANFD_0xB6 : 32 Vector__XXX
 SG_ CurHeiSigGrpChks : 7|8@0+ (1,0) [0|255] "" ADD
 SG_ CurHeiSigGrpCntr : 11|4@0+ (1,0) [0|15] "" ADD
 SG_ FrntLeCurHei : 23|8@0+ (1.0,-127.0) [-127.0|128.0] "mm" ADD
 SG_ FrntLeCurHeiSts : 15|1@0+ (1,0) [0|1] "" ADD
 SG_ FrntRiCurHei : 39|8@0+ (1.0,-127.0) [-127.0|128.0] "mm" ADD
 SG_ FrntRiCurHeiSts : 13|1@0+ (1,0) [0|1] "" ADD
 SG_ ReLeCurHei : 31|8@0+ (1.0,-127.0) [-127.0|128.0] "mm" ADD
 SG_ ReLeCurHeiSts : 14|1@0+ (1,0) [0|1] "" ADD
 SG_ ReRiCurHei : 47|8@0+ (1.0,-127.0) [-127.0|128.0] "mm" ADD
 SG_ ReRiCurHeiSts : 12|1@0+ (1,0) [0|1] "" ADD

BO_ 419 SWM_ADASCANFD_0x1A3 : 16 Vector__XXX
 SG_ SwtIndcrRaw : 42|3@0+ (1,0) [0|7] "" ADD
 SG_ SwtIndcrRawSigGrpChks : 31|8@0+ (1,0) [0|255] "" ADD
 SG_ SwtIndcrRawSigGrpCntr : 35|4@0+ (1,0) [0|15] "" ADD

BO_ 263 TBOX_ADASCANFD_0x107 : 8 Vector__XXX
 SG_ DateTiDay : 28|5@0+ (1,0) [0|31] "" ADD
 SG_ DateTiHr : 36|5@0+ (1.0,0.0) [0.0|24.0] "hour" ADD
 SG_ DateTiMilsec : 49|10@0+ (1.0,0.0) [0.0|1000.0] "Msec" ADD
 SG_ DateTiMins : 45|6@0+ (1.0,0.0) [0.0|59.0] "minute" ADD
 SG_ DateTiMth : 19|4@0+ (1.0,0.0) [0.0|12.0] "" ADD
 SG_ DateTiSec : 55|6@0+ (1.0,0.0) [0.0|59.0] "second" ADD
 SG_ DateTiYr : 15|8@0+ (1.0,2000.0) [2000.0|2254.0] "year" ADD
 SG_ TiDomn : 4|5@0+ (1,0) [0|31] "" ADD

BO_ 742 TBOX_ADASCANFD_0x2E6 : 32 Vector__XXX
 SG_ FrntLeTyrePVal : 47|8@0+ (2.75,0.0) [0.0|698.5] "kpa" ADD
 SG_ FrntLeTyrePWarn : 135|2@0+ (1,0) [0|3] "" ADD
 SG_ FrntRiTyrePVal : 63|8@0+ (2.75,0.0) [0.0|698.5] "kpa" ADD
 SG_ FrntRiTyrePWarn : 121|2@0+ (1,0) [0|3] "" ADD
 SG_ ReLeTyrePVal : 79|8@0+ (2.75,0.0) [0.0|698.5] "kpa" ADD
 SG_ ReLeTyrePWarn : 27|2@0+ (1,0) [0|3] "" ADD
 SG_ ReRiTyrePVal : 95|8@0+ (2.75,0.0) [0.0|698.5] "kpa" ADD
 SG_ ReRiTyrePWarn : 125|2@0+ (1,0) [0|3] "" ADD
 SG_ TPMonitorSECOCFV : 215|16@0+ (1.0,0.0) [0.0|65535.0] "" ADD
 SG_ TPMonitorSECOCMAC : 231|32@0+ (1.0,0.0) [0.0|0.0] "" ADD

BO_ 388 VCCD_ADASCANFD_0x184 : 32 Vector__XXX
 SG_ DiagcExtActv : 5|1@0+ (1,0) [0|1] "" ADD
 SG_ DoorDrvrPwrRelsDlyActv : 23|2@0+ (1,0) [0|3] "" ADD
 SG_ DoorDrvrSts : 21|2@0+ (1,0) [0|3] "" ADD
 SG_ DoorLeRePwrRelsDlyActv : 19|2@0+ (1,0) [0|3] "" ADD
 SG_ DoorLeReSts : 17|2@0+ (1,0) [0|3] "" ADD
 SG_ DoorPassPwrRelsDlyActv : 31|2@0+ (1,0) [0|3] "" ADD
 SG_ DoorPassSts : 29|2@0+ (1,0) [0|3] "" ADD
 SG_ DoorRiRePwrRelsDlyActv : 39|2@0+ (1,0) [0|3] "" ADD
 SG_ DoorRiReSts : 47|2@0+ (1,0) [0|3] "" ADD
 SG_ ExtrMirrFoldEnaFailr : 45|4@0+ (1,0) [0|15] "" ADD
 SG_ ExtrMirrFoldSts : 26|3@0+ (1,0) [0|7] "" ADD
 SG_ HoodOpenClsSts : 33|2@0+ (1,0) [0|3] "" ADD
 SG_ LeMirrFoldCmd : 2|2@0+ (1,0) [0|3] "" ADD
 SG_ RiMirrFoldCmd : 4|2@0+ (1,0) [0|3] "" ADD
 SG_ SpclRoadSurfTypSigGrpChks : 175|8@0+ (1,0) [0|255] "" ADD
 SG_ SpclRoadSurfTypSigGrpCntr : 179|4@0+ (1,0) [0|15] "" ADD
 SG_ TrOpenClsSts : 36|2@0+ (1,0) [0|3] "" ADD
 SG_ VCUGearChgFailrSts : 0|1@0+ (1,0) [0|1] "" ADD
 SG_ VCULatSlopForDisp : 199|12@0+ (0.1,-45.0) [-45.0|45.0] "deg" ADD
 SG_ VCULgtSlopForDisp : 203|12@0+ (0.1,-45.0) [-45.0|45.0] "deg" ADD
 SG_ VCUSpclRoadSurfTypForDisp : 191|4@0+ (1,0) [0|15] "" ADD

BO_ 514 VCCD_ADASCANFD_0x202 : 32 Vector__XXX
 SG_ ExtrLtgStsHiBeam : 7|2@0+ (1,0) [0|3] "" ADD
 SG_ ExtrLtgStsLoBeam : 5|2@0+ (1,0) [0|3] "" ADD
 SG_ ExtrLtgStsStop : 3|2@0+ (1,0) [0|3] "" ADD
 SG_ ExtrLtgStsTurnIndrLe : 1|2@0+ (1,0) [0|3] "" ADD
 SG_ ExtrLtgStsTurnIndrRi : 15|2@0+ (1,0) [0|3] "" ADD
 SG_ LVPwrSplyBattErrSts : 151|1@0+ (1,0) [0|1] "" ADD
 SG_ LVPwrSplyBattErrStsSigGrpChks : 135|8@0+ (1.0,0.0) [0.0|255.0] "" ADD
 SG_ LVPwrSplyBattErrStsSigGrpCntr : 139|4@0+ (1.0,0.0) [0.0|15.0] "" ADD
 SG_ LVPwrSplyDCDCErrSts : 174|1@0+ (1,0) [0|1] "" ADD
 SG_ LVPwrSplyHiErrSts : 175|1@0+ (1,0) [0|1] "" ADD
 SG_ LVPwrSplyHiErrStsSigGrpChks : 159|8@0+ (1.0,0.0) [0.0|255.0] "" ADD
 SG_ LVPwrSplyHiErrStsSigGrpCntr : 163|4@0+ (1.0,0.0) [0.0|15.0] "" ADD
 SG_ LVPwrSplyLoErrSts : 199|1@0+ (1,0) [0|1] "" ADD
 SG_ LVPwrSplyLoErrStsSigGrpChks : 183|8@0+ (1.0,0.0) [0.0|255.0] "" ADD
 SG_ LVPwrSplyLoErrStsSigGrpCntr : 187|4@0+ (1.0,0.0) [0.0|15.0] "" ADD
 SG_ OTALowEgy : 37|1@0+ (1,0) [0|1] "" ADD
 SG_ OTAMode : 19|1@0+ (1,0) [0|1] "" ADD
 SG_ SBLDmValSetLe : 231|7@0+ (1.0,0.0) [0.0|127.0] "%" ADD
 SG_ SBLDmValSetRi : 239|7@0+ (1.0,0.0) [0.0|127.0] "%" ADD
 SG_ StsOfIndcr : 34|3@0+ (1,0) [0|7] "" ADD
 SG_ SwtIndcr : 13|3@0+ (1,0) [0|7] "" ADD
 SG_ SwtIndcrSts : 31|3@0+ (1.0,0.0) [0.0|7.0] "" ADD
 SG_ VCUAccrPrmSetAllwd : 40|1@0+ (1,0) [0|1] "" ADD
 SG_ VCUActDrvMod : 23|4@0+ (1,0) [0|15] "" ADD
 SG_ VCUBatModAllwd : 55|1@0+ (1,0) [0|1] "" ADD
 SG_ VCUBrkPedlFeelStAllwd : 54|1@0+ (1,0) [0|1] "" ADD
 SG_ VCUDriftModSetSts : 18|1@0+ (1,0) [0|1] "" ADD
 SG_ VCUDrvModRgnPrmSts : 47|7@0+ (1.0,1.0) [1.0|100.0] "" ADD
 SG_ VCUDrvModStSts : 38|1@0+ (1,0) [0|1] "" ADD
 SG_ VCUExtmECOModStReq : 52|1@0+ (1,0) [0|1] "" ADD
 SG_ VCUExtmPfmncMod : 17|1@0+ (1,0) [0|1] "" ADD
 SG_ VCULnchPlusSts : 9|2@0+ (1.0,0.0) [0.0|2.0] "" ADD
 SG_ VCUOnePedlModAllwd : 51|1@0+ (1,0) [0|1] "" ADD
 SG_ VCURgnPrmSetAllwd : 50|1@0+ (1,0) [0|1] "" ADD
 SG_ VCUSpdLimrSts : 222|1@0+ (1,0) [0|1] "" ADD
 SG_ VCUSpdLimrValSts : 215|9@0+ (1.0,0.0) [0.0|510.0] "km/h" ADD
 SG_ VCUSteerAsstPrmSetAllwd : 49|1@0+ (1,0) [0|1] "" ADD
 SG_ VCUSuspDampgPrmSetAllwd : 48|1@0+ (1,0) [0|1] "" ADD
 SG_ VCUSuspLvlgPrm1Allwd : 63|1@0+ (1,0) [0|1] "" ADD
 SG_ VCUSuspLvlgPrm2Allwd : 62|1@0+ (1,0) [0|1] "" ADD
 SG_ VCUSuspLvlgPrm3Allwd : 61|1@0+ (1,0) [0|1] "" ADD
 SG_ VCUSuspLvlgPrm4Allwd : 60|1@0+ (1,0) [0|1] "" ADD
 SG_ VCUSuspLvlgPrm5Allwd : 59|1@0+ (1,0) [0|1] "" ADD
 SG_ VCUTrlrModStSts : 67|1@0+ (1,0) [0|1] "" ADD
 SG_ VCUWashModEntryAllwd : 58|1@0+ (1,0) [0|1] "" ADD
 SG_ VCUWashModExtAllwd : 57|1@0+ (1,0) [0|1] "" ADD
 SG_ VCUWashModStSts : 16|1@0+ (1,0) [0|1] "" ADD

BO_ 529 VCCD_ADASCANFD_0x211 : 16 Vector__XXX
 SG_ SecOCMAC1 : 47|32@0+ (1.0,0.0) [0.0|4294967295.0] "" ADD
 SG_ SecOCMAC2 : 79|32@0+ (1.0,0.0) [0.0|4294967295.0] "" ADD
 SG_ SecOCMAC3 : 111|24@0+ (1.0,0.0) [0.0|16777215.0] "" ADD
 SG_ SecOCResetCnt : 31|16@0+ (1.0,0.0) [0.0|65535.0] "" ADD
 SG_ SecOCTripCnt : 7|24@0+ (1.0,0.0) [0.0|16777215.0] "" ADD

BO_ 689 VCCD_ADASCANFD_0x2B1 : 24 Vector__XXX
 SG_ ADDCooltCircFlowEstimd : 31|10@0+ (0.05,0.0) [0.0|51.150000000000006] "L/min" ADD
 SG_ AmbTEstimd : 7|16@0+ (0.01,-80.0) [-80.0|175.0] "degC" ADD
 SG_ AmbTEstimdVld : 23|1@0+ (1,0) [0|1] "" ADD
 SG_ EdsCircCooltT : 135|16@0+ (0.01,-80.0) [-80.0|175.0] "degC" ADD
 SG_ EdsCircCooltTVld : 151|1@0+ (1,0) [0|1] "" ADD
 SG_ InsEgyCnsSigGrpChks : 47|8@0+ (1,0) [0|255] "" ADD
 SG_ InsEgyCnsSigGrpCntr : 51|4@0+ (1,0) [0|15] "" ADD
 SG_ LockgCenLockSts : 33|2@0+ (1,0) [0|3] "" ADD
 SG_ OTALinkMgr : 37|1@0+ (1,0) [0|1] "" ADD
 SG_ SetMgrDrvrSeldDstLvl : 36|3@0+ (1,0) [0|7] "" ADD
 SG_ VCUEgyCnsInCurDrvCyc : 63|18@0+ (0.01,-200.0) [-200.0|200.0] "kwh" ADD
 SG_ VCUEstimdCrsRng : 111|11@0+ (1.0,0.0) [0.0|2046.0] "" ADD
 SG_ VCUEstimdCrsRngForCltc : 114|11@0+ (1.0,0.0) [0.0|2047.0] "" ADD
 SG_ VCUEstimdCrsRngVld : 116|1@0+ (1,0) [0|1] "" ADD
 SG_ VCUInsEgyCnsDurgDrvg : 95|11@0+ (0.1,-100.0) [-100.0|100.0] "" ADD
 SG_ VCUInsEgyCnsDurgStsl : 72|9@0+ (0.1,0.0) [0.0|50.0] "" ADD
 SG_ VCUInsEgyCnsFlg : 100|1@0+ (1,0) [0|1] "" ADD
 SG_ VCUPwrFlowForDisp : 99|2@0+ (1,0) [0|3] "" ADD

BO_ 868 VCCD_ADASCANFD_0x364 : 24 Vector__XXX
 SG_ SetMgrAdsACCInitSpdSwt : 127|3@0+ (1,0) [0|7] "" ADD
 SG_ SetMgrAdsAEBFCWSwt : 124|3@0+ (1,0) [0|7] "" ADD
 SG_ SetMgrAdsALCSwtSts : 135|3@0+ (1,0) [0|7] "" ADD
 SG_ SetMgrAdsAPA2SwtSts : 183|3@0+ (1,0) [0|7] "" ADD
 SG_ SetMgrAdsAudModSwt : 55|3@0+ (1,0) [0|7] "" ADD
 SG_ SetMgrAdsAutoTurnLiSwt : 175|3@0+ (1.0,0.0) [0.0|7.0] "" ADD
 SG_ SetMgrAdsAVPSwtSts : 52|3@0+ (1,0) [0|7] "" ADD
 SG_ SetMgrAdsBSDLCASwt : 63|3@0+ (1,0) [0|7] "" ADD
 SG_ SetMgrAdsCfgLoadReq : 132|3@0+ (1,0) [0|7] "" ADD
 SG_ SetMgrAdsDOWSwt : 60|3@0+ (1,0) [0|7] "" ADD
 SG_ SetMgrAdsELKSwSts : 140|3@0+ (1,0) [0|7] "" ADD
 SG_ SetMgrAdsFxdSpdModValSwt : 71|7@0+ (1.0,0.0) [0.0|64.0] "" ADD
 SG_ SetMgrAdsHPPBckGrLear : 79|3@0+ (1,0) [0|7] "" ADD
 SG_ SetMgrAdsHPPSwtSts : 76|3@0+ (1,0) [0|7] "" ADD
 SG_ SetMgrAdsIntelgntSpdSwt : 180|3@0+ (1.0,0.0) [0.0|7.0] "" ADD
 SG_ SetMgrAdsLaneChgCnfmSwt : 87|3@0+ (1,0) [0|7] "" ADD
 SG_ SetMgrAdsLDWPSwt : 84|3@0+ (1,0) [0|7] "" ADD
 SG_ SetMgrAdsLDWPWarnTypSwt : 95|3@0+ (1,0) [0|7] "" ADD
 SG_ SetMgrAdsMAISwtSts : 191|3@0+ (1.0,0.0) [0.0|7.0] "" ADD
 SG_ SetMgrAdsModSwt : 159|3@0+ (1,0) [0|7] "" ADD
 SG_ SetMgrAdsNOAHWSwtSts : 92|3@0+ (1,0) [0|7] "" ADD
 SG_ SetMgrAdsNOAOddSwt : 156|3@0+ (1,0) [0|7] "" ADD
 SG_ SetMgrAdsParkAudModSwt : 47|3@0+ (1,0) [0|7] "" ADD
 SG_ SetMgrAdsParkSpdSwtSts : 172|3@0+ (1.0,0.0) [0.0|7.0] "" ADD
 SG_ SetMgrAdsPcntgeSpdlvlSwt : 103|6@0+ (1.0,0.0) [0.0|34.0] "" ADD
 SG_ SetMgrAdsPltSwtSts : 111|3@0+ (1,0) [0|7] "" ADD
 SG_ SetMgrAdsPntCldSwt : 108|3@0+ (1,0) [0|7] "" ADD
 SG_ SetMgrAdsRCTABSwt : 119|3@0+ (1.0,0.0) [0.0|7.0] "" ADD
 SG_ SetMgrAdsRCWSwt : 116|3@0+ (1,0) [0|7] "" ADD
 SG_ SetMgrAdsTLASwt : 44|3@0+ (1,0) [0|7] "" ADD
 SG_ SetMgrAdsTrfcLiCtrlSwt : 167|3@0+ (1,0) [0|7] "" ADD
 SG_ SetMgrAdsVehDetourSwt : 164|3@0+ (1,0) [0|7] "" ADD
 SG_ SetMgrAdsVehSpdDvtnModSwt : 143|3@0+ (1,0) [0|7] "" ADD
 SG_ VCUBattOverHeatWarn : 15|1@0+ (1,0) [0|1] "" ADD
 SG_ VCUChrgnModSts : 151|4@0+ (1,0) [0|15] "" ADD
 SG_ VCUDrvMotFltWarn : 13|1@0+ (1,0) [0|1] "" ADD
 SG_ VCUDrvMotOverHeatWarn : 12|1@0+ (1,0) [0|1] "" ADD
 SG_ VCUDrvSysLimdWarn : 18|1@0+ (1,0) [0|1] "" ADD
 SG_ VCUGearChgFailInde : 23|4@0+ (1,0) [0|15] "" ADD
 SG_ VCUHvBattSysFltIndcr : 19|1@0+ (1,0) [0|1] "" ADD
 SG_ VCUHvBattSysFltWarn : 17|1@0+ (1,0) [0|1] "" ADD
 SG_ VCUHVExtPortConnectnTypInfo : 147|4@0+ (1,0) [0|15] "" ADD
 SG_ VCUHvPwrSysCutOff : 39|1@0+ (1,0) [0|1] "" ADD
 SG_ VCUHVSysFltWarnSts : 31|4@0+ (1,0) [0|15] "" ADD
 SG_ VCULoSocWarngMsg : 26|2@0+ (1.0,0.0) [0.0|2.0] "" ADD
 SG_ VCUPrpsnPwrDrt : 38|1@0+ (1,0) [0|1] "" ADD
 SG_ VCUThermRunawayErrAlrm : 37|1@0+ (1,0) [0|1] "" ADD
 SG_ VCUVehSysFltWarn : 36|1@0+ (1,0) [0|1] "" ADD
 SG_ VehSysFltWarnSigGrpChks : 7|8@0+ (1,0) [0|255] "" ADD
 SG_ VehSysFltWarnSigGrpCntr : 11|4@0+ (1,0) [0|15] "" ADD

BO_ 1023 VCCD_ADASCANFD_0x3FF : 16 Vector__XXX
 SG_ VidBlkId : 71|8@0+ (1,0) [0|255] "" ADD
 SG_ VidSignalPos1 : 79|8@0+ (1.0,0.0) [0.0|255.0] "" ADD
 SG_ VidSignalPos2 : 87|8@0+ (1.0,0.0) [0.0|255.0] "" ADD
 SG_ VidSignalPos3 : 95|8@0+ (1.0,0.0) [0.0|255.0] "" ADD
 SG_ VidSignalPos4 : 103|8@0+ (1.0,0.0) [0.0|255.0] "" ADD
 SG_ VidSignalPos5 : 111|8@0+ (1.0,0.0) [0.0|255.0] "" ADD
 SG_ VidSignalPos6 : 119|8@0+ (1.0,0.0) [0.0|255.0] "" ADD
 SG_ VidSignalPos7 : 127|8@0+ (1.0,0.0) [0.0|255.0] "" ADD
 SG_ VinVINBlkID : 7|8@0+ (1,0) [0|255] "" ADD
 SG_ VinVINSignalPos1 : 15|8@0+ (1.0,0.0) [0.0|255.0] "" ADD
 SG_ VinVINSignalPos2 : 23|8@0+ (1.0,0.0) [0.0|255.0] "" ADD
 SG_ VinVINSignalPos3 : 31|8@0+ (1.0,0.0) [0.0|255.0] "" ADD
 SG_ VinVINSignalPos4 : 39|8@0+ (1.0,0.0) [0.0|255.0] "" ADD
 SG_ VinVINSignalPos5 : 47|8@0+ (1.0,0.0) [0.0|255.0] "" ADD
 SG_ VinVINSignalPos6 : 55|8@0+ (1.0,0.0) [0.0|255.0] "" ADD
 SG_ VinVINSignalPos7 : 63|8@0+ (1.0,0.0) [0.0|255.0] "" ADD

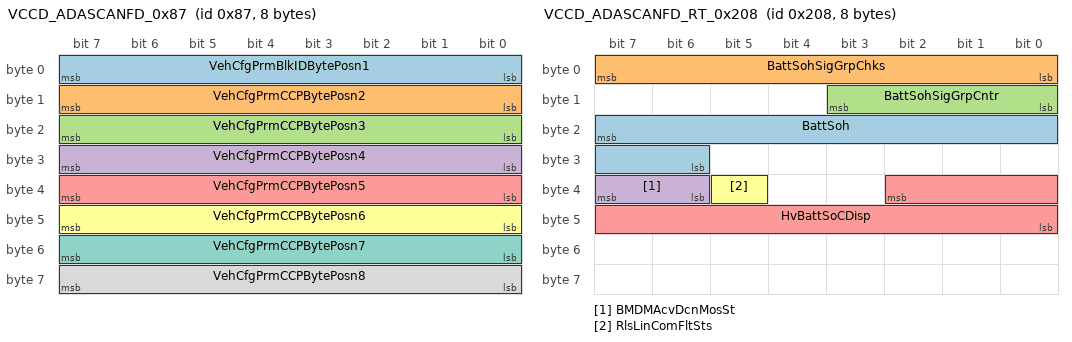
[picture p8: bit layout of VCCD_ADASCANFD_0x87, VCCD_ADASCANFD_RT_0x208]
BO_ 135 VCCD_ADASCANFD_0x87 : 8 Vector__XXX
 SG_ VehCfgPrmBlkIDBytePosn1 : 7|8@0+ (1.0,0.0) [0.0|150.0] "" ADD
 SG_ VehCfgPrmCCPBytePosn2 : 15|8@0+ (1.0,0.0) [0.0|255.0] "" ADD
 SG_ VehCfgPrmCCPBytePosn3 : 23|8@0+ (1.0,0.0) [0.0|255.0] "" ADD
 SG_ VehCfgPrmCCPBytePosn4 : 31|8@0+ (1.0,0.0) [0.0|255.0] "" ADD
 SG_ VehCfgPrmCCPBytePosn5 : 39|8@0+ (1.0,0.0) [0.0|255.0] "" ADD
 SG_ VehCfgPrmCCPBytePosn6 : 47|8@0+ (1.0,0.0) [0.0|255.0] "" ADD
 SG_ VehCfgPrmCCPBytePosn7 : 55|8@0+ (1.0,0.0) [0.0|255.0] "" ADD
 SG_ VehCfgPrmCCPBytePosn8 : 63|8@0+ (1.0,0.0) [0.0|255.0] "" ADD

BO_ 212 VCCD_ADASCANFD_0xD4 : 64 Vector__XXX
 SG_ CarModSts : 351|3@0+ (1,0) [0|7] "" ADD
 SG_ DrvActvSts : 344|1@0+ (1,0) [0|1] "" ADD
 SG_ FrntMotCtrlSigGrpChks : 7|8@0+ (1,0) [0|255] "" ADD
 SG_ FrntMotCtrlSigGrpCntr : 11|4@0+ (1,0) [0|15] "" ADD
 SG_ LockgCenLockTrigSrc : 484|5@0+ (1,0) [0|31] "" ADD
 SG_ LockgDrvrDoorLockCmd : 495|2@0+ (1,0) [0|3] "" ADD
 SG_ PwrModSigGrpChks : 327|8@0+ (1,0) [0|255] "" ADD
 SG_ PwrModSigGrpCntr : 331|4@0+ (1,0) [0|15] "" ADD
 SG_ PwrModSts : 335|3@0+ (1,0) [0|7] "" ADD
 SG_ PwrModVld : 332|1@0+ (1,0) [0|1] "" ADD
 SG_ ReMotCtrlSigGrpChks : 127|8@0+ (1,0) [0|255] "" ADD
 SG_ ReMotCtrlSigGrpCntr : 131|4@0+ (1,0) [0|15] "" ADD
 SG_ VCUAccrPedlFlg : 359|1@0+ (1,0) [0|1] "" ADD
 SG_ VCUAccrPedlRat : 455|15@0+ (0.004,0.0) [0.0|100.0] "pct" ADD
 SG_ VCUAccrPedlRatGrdt : 358|15@0- (0.0625,0.0) [-1000.0|1000.0] "" ADD
 SG_ VCUAccrPedlRatVld : 441|1@0+ (1,0) [0|1] "" ADD
 SG_ VCUActGearLvr : 407|3@0+ (1,0) [0|7] "" ADD
 SG_ VCUActGearLvrVld : 404|1@0+ (1,0) [0|1] "" ADD
 SG_ VCUActGearSigGrpChks : 399|8@0+ (1,0) [0|255] "" ADD
 SG_ VCUActGearSigGrpCntr : 403|4@0+ (1,0) [0|15] "" ADD
 SG_ VCUAlwParkRels : 337|1@0+ (1.0,0.0) [0.0|1.0] "" ADD
 SG_ VCUDrvOffFcnLim : 471|1@0+ (1,0) [0|1] "" ADD
 SG_ VCUFrntDesTqWoIntv : 23|15@0+ (1.0,-16383.0) [-16383.0|16384.0] "Nm" ADD
 SG_ VCUFrntDesTqWoIntvVld : 24|1@0+ (1,0) [0|1] "" ADD
 SG_ VCUFrntEmTqRdy : 440|1@0+ (1,0) [0|1] "" ADD
 SG_ VCUFrntMotActSpd : 39|16@0+ (1.0,-32767.0) [-32767.0|32768.0] "rpm" ADD
 SG_ VCUFrntMotActSpdVld : 56|1@0+ (1,0) [0|1] "" ADD
 SG_ VCUFrntMotActTq : 55|15@0+ (1.0,-16383.0) [-16383.0|16384.0] "Nm" ADD
 SG_ VCUFrntMotActTqVld : 72|1@0+ (1,0) [0|1] "" ADD
 SG_ VCUFrntMotWhlTqReq : 71|15@0+ (1.0,-16383.0) [-16383.0|16383.0] "Nm" ADD
 SG_ VCUFrntMotWhlTqReqVld : 88|1@0+ (1,0) [0|1] "" ADD
 SG_ VCUFrntWhlTqMaxAvl : 87|14@0+ (1.0,0.0) [0.0|16383.0] "Nm" ADD
 SG_ VCUFrntWhlTqMaxAvlVld : 89|1@0+ (1,0) [0|1] "" ADD
 SG_ VCUFrntWhlTqMinAvl : 103|14@0+ (1.0,-16383.0) [-16383.0|0.0] "Nm" ADD
 SG_ VCUFrntWhlTqMinAvlVld : 105|1@0+ (1,0) [0|1] "" ADD
 SG_ VCUGearLvrAvail : 336|1@0+ (1,0) [0|1] "" ADD
 SG_ VCUHVSt : 487|3@0+ (1,0) [0|7] "" ADD
 SG_ VcuInpSigGrpChks : 415|8@0+ (1,0) [0|255] "" ADD
 SG_ VcuInpSigGrpCntr : 419|4@0+ (1,0) [0|15] "" ADD
 SG_ VCULoSocLampReq : 347|1@0+ (1,0) [0|1] "" ADD
 SG_ VCUPedlTqOvrdAdsFlg : 346|1@0+ (1,0) [0|1] "" ADD
 SG_ VCUPrkgBtnPsd : 443|1@0+ (1,0) [0|1] "" ADD
 SG_ VCUPrkgBtnPsdVld : 345|1@0+ (1,0) [0|1] "" ADD
 SG_ VCUPtRdyFlg : 348|1@0+ (1,0) [0|1] "" ADD
 SG_ VCUReDesTqWoIntv : 143|15@0+ (1.0,-16383.0) [-16383.0|16384.0] "Nm" ADD
 SG_ VCUReDesTqWoIntvVld : 144|1@0+ (1,0) [0|1] "" ADD
 SG_ VCUReEmTqRdy : 442|1@0+ (1,0) [0|1] "" ADD
 SG_ VCUReMotActSpd : 159|16@0+ (1.0,-32767.0) [-32767.0|32768.0] "rpm" ADD
 SG_ VCUReMotActSpdVld : 176|1@0+ (1,0) [0|1] "" ADD
 SG_ VCUReMotActTq : 175|15@0+ (1.0,-16383.0) [-16383.0|16384.0] "Nm" ADD
 SG_ VCUReMotActTqVld : 208|1@0+ (1,0) [0|1] "" ADD
 SG_ VCUReMotWhlTqReq : 191|15@0+ (1.0,-16383.0) [-16383.0|16383.0] "Nm" ADD
 SG_ VCUReMotWhlTqReqVld : 192|1@0+ (1,0) [0|1] "" ADD
 SG_ VCUReWhlTqMaxAvl : 207|14@0+ (1.0,0.0) [0.0|16383.0] "Nm" ADD
 SG_ VCUReWhlTqMaxAvlVld : 209|1@0+ (1,0) [0|1] "" ADD
 SG_ VCUReWhlTqMinAvl : 223|14@0+ (1.0,-16383.0) [-16383.0|0.0] "Nm" ADD
 SG_ VCUReWhlTqMinAvlVld : 225|1@0+ (1,0) [0|1] "" ADD
 SG_ VCURgnTqCorrnFac : 423|4@0+ (0.1,0.0) [0.0|1.0] "" ADD
 SG_ VCURLMotActTq : 239|15@0+ (1.0,-16383.0) [-16383.0|16384.0] "Nm" ADD
 SG_ VCURLMotActTqVld : 240|1@0+ (1,0) [0|1] "" ADD
 SG_ VCURLMotWhlTqReq : 255|15@0+ (1.0,-16383.0) [-16383.0|16384.0] "Nm" ADD
 SG_ VCURLMotWhlTqReqVld : 256|1@0+ (1,0) [0|1] "" ADD
 SG_ VCURRMotActTq : 271|15@0+ (1.0,-16383.0) [-16383.0|16384.0] "Nm" ADD
 SG_ VCURRMotActTqVld : 272|1@0+ (1,0) [0|1] "" ADD
 SG_ VCURRMotWhlTqReq : 287|15@0+ (1.0,-16383.0) [-16383.0|16384.0] "Nm" ADD
 SG_ VCURRMotWhlTqReqVld : 288|1@0+ (1,0) [0|1] "" ADD
 SG_ VCUShifterMoveFlg : 456|1@0+ (1.0,0.0) [0.0|1.0] "" ADD
 SG_ VCUStsModCst : 431|8@0+ (1,0) [0|255] "" ADD
 SG_ VCUTarGearLvr : 447|3@0+ (1,0) [0|7] "" ADD
 SG_ VCUTarGearLvrVld : 444|1@0+ (1,0) [0|1] "" ADD
 SG_ VCUVehMaxFltLvl : 343|3@0+ (1,0) [0|7] "" ADD
 SG_ VCUVirtAccrPedl : 439|7@0+ (1.0,0.0) [0.0|100.0] "%" ADD
 SG_ VCUVirtAccrPedlVld : 432|1@0+ (1,0) [0|1] "" ADD
 SG_ VCUWhlTqMaxAvl : 303|15@0+ (1.0,0.0) [0.0|32767.0] "N.m" ADD
 SG_ VCUWhlTqMaxAvlVld : 304|1@0+ (1,0) [0|1] "" ADD
 SG_ WiprSpdModSts : 391|6@0+ (1,0) [0|63] "" ADD
 SG_ WipSpdReqHi : 383|1@0+ (1,0) [0|1] "" ADD
 SG_ WipSpdReqLo : 382|1@0+ (1,0) [0|1] "" ADD
 SG_ WipSpdReqSigGrpChks : 375|8@0+ (1.0,0.0) [0.0|255.0] "" ADD
 SG_ WipSpdReqSigGrpCntr : 379|4@0+ (1.0,0.0) [0.0|15.0] "" ADD

BO_ 228 VCCD_ADASCANFD_0xE4 : 16 Vector__XXX
 SG_ VDMLgtWhlSpdFL : 23|10@0+ (0.1,0.0) [0.0|100.0] "mps" ADD
 SG_ VDMLgtWhlSpdFR : 25|10@0+ (0.1,0.0) [0.0|100.0] "mps" ADD
 SG_ VDMLgtWhlSpdRL : 47|10@0+ (0.1,0.0) [0.0|100.0] "mps" ADD
 SG_ VDMLgtWhlSpdRR : 49|10@0+ (0.1,0.0) [0.0|100.0] "mps" ADD
 SG_ VDMVehSpdEstmGrpChks : 7|8@0+ (1.0,0.0) [0.0|255.0] "" ADD
 SG_ VDMVehSpdEstmGrpCntr : 11|4@0+ (1.0,0.0) [0.0|15.0] "" ADD
 SG_ VehBodySideSlipAng : 71|12@0+ (0.01,-6.0) [-6.0|6.0] "deg" ADD
 SG_ VehLatSpdEstd : 73|10@0+ (0.1,0.0) [0.0|100.0] "m/s" ADD
 SG_ VehLatSpdEstdVld : 101|1@0+ (1,0) [0|1] "" ADD
 SG_ VehLgtSpdEstd : 95|10@0+ (0.1,0.0) [0.0|100.0] "m/s" ADD
 SG_ VehLgtSpdEstdVld : 100|1@0+ (1,0) [0|1] "" ADD

BO_ 389 VCCD_ADASCANFD_RT_0x185 : 16 Vector__XXX
 SG_ AdasSwt : 23|2@0+ (1,0) [0|3] "" ADD
 SG_ AdasSwtSigGrpChks : 7|8@0+ (1,0) [0|255] "" ADD
 SG_ AdasSwtSigGrpCntr : 11|4@0+ (1,0) [0|15] "" ADD
 SG_ AdasSwtSigGrpLinErr : 21|2@0+ (1,0) [0|3] "" ADD
 SG_ LeKnobCounter : 39|8@0+ (1.0,0.0) [0.0|254.0] "" ADD
 SG_ LeKnobRotDir : 47|2@0+ (1.0,0.0) [0.0|3.0] "" ADD
 SG_ LeMFctActSgCe : 45|2@0+ (1,0) [0|3] "" ADD
 SG_ LeMFctActSgLe : 43|2@0+ (1,0) [0|3] "" ADD
 SG_ LeMFctActSgRi : 41|2@0+ (1,0) [0|3] "" ADD
 SG_ SwsLinComFltSts : 31|1@0+ (1,0) [0|1] "" ADD

BO_ 520 VCCD_ADASCANFD_RT_0x208 : 8 Vector__XXX
 SG_ BattSoh : 23|10@0+ (0.1,0.0) [0.0|102.30000000000001] "%" ADD
 SG_ BattSohSigGrpChks : 7|8@0+ (1.0,0.0) [0.0|255.0] "" ADD
 SG_ BattSohSigGrpCntr : 11|4@0+ (1.0,0.0) [0.0|15.0] "" ADD
 SG_ BMDMAcvDcnMosSt : 39|2@0+ (1,0) [0|3] "" ADD
 SG_ HvBattSoCDisp : 34|11@0+ (0.05,0.0) [0.0|100.0] "%" ADD
 SG_ RlsLinComFltSts : 37|1@0+ (1,0) [0|1] "" ADD

BO_ 1400 VCCDAdasCanfdNMFr : 8 Vector__XXX
 SG_ NMKeepAwkRsnVCCD : 48|9@0+ (1.0,0.0) [0.0|511.0] "" ADD
 SG_ UDB17VCCD : 17|1@0+ (1.0,0.0) [0.0|1.0] "" ADD
 SG_ UDB18VCCD : 18|1@0+ (1.0,0.0) [0.0|1.0] "" ADD
 SG_ UDB19VCCD : 19|1@0+ (1.0,0.0) [0.0|1.0] "" ADD
 SG_ UDB20VCCD : 20|1@0+ (1.0,0.0) [0.0|1.0] "" ADD
 SG_ UDB21VCCD : 21|1@0+ (1.0,0.0) [0.0|1.0] "" ADD
 SG_ UDB22VCCD : 22|1@0+ (1.0,0.0) [0.0|1.0] "" ADD
 SG_ UDB23VCCD : 23|1@0+ (1.0,0.0) [0.0|1.0] "" ADD
 SG_ UDB24VCCD : 24|1@0+ (1.0,0.0) [0.0|1.0] "" ADD
 SG_ UDB25VCCD : 25|1@0+ (1.0,0.0) [0.0|1.0] "" ADD
 SG_ UDB26VCCD : 26|1@0+ (1.0,0.0) [0.0|1.0] "" ADD
 SG_ UDB27VCCD : 27|1@0+ (1.0,0.0) [0.0|1.0] "" ADD
 SG_ UDB28VCCD : 28|1@0+ (1.0,0.0) [0.0|1.0] "" ADD
 SG_ UDB29VCCD : 29|1@0+ (1.0,0.0) [0.0|1.0] "" ADD
 SG_ UDB30VCCD : 30|1@0+ (1.0,0.0) [0.0|1.0] "" ADD
 SG_ UDB31VCCD : 31|1@0+ (1.0,0.0) [0.0|1.0] "" ADD
 SG_ UDB32VCCD : 32|1@0+ (1.0,0.0) [0.0|1.0] "" ADD
 SG_ UDB33VCCD : 33|1@0+ (1.0,0.0) [0.0|1.0] "" ADD
 SG_ UDB34VCCD : 34|1@0+ (1.0,0.0) [0.0|1.0] "" ADD
 SG_ UDB35VCCD : 35|1@0+ (1.0,0.0) [0.0|1.0] "" ADD
 SG_ UDB36VCCD : 36|1@0+ (1.0,0.0) [0.0|1.0] "" ADD
 SG_ UDB37VCCD : 37|1@0+ (1.0,0.0) [0.0|1.0] "" ADD
 SG_ UDB38VCCD : 38|1@0+ (1.0,0.0) [0.0|1.0] "" ADD
 SG_ UDB39VCCD : 39|1@0+ (1.0,0.0) [0.0|1.0] "" ADD
 SG_ UDB40VCCD : 40|1@0+ (1.0,0.0) [0.0|1.0] "" ADD
 SG_ UDB41VCCD : 41|1@0+ (1.0,0.0) [0.0|1.0] "" ADD
 SG_ UDB42VCCD : 42|1@0+ (1.0,0.0) [0.0|1.0] "" ADD
 SG_ UDB43VCCD : 43|1@0+ (1.0,0.0) [0.0|1.0] "" ADD
 SG_ UDB44VCCD : 44|1@0+ (1.0,0.0) [0.0|1.0] "" ADD
 SG_ UDB45VCCD : 45|1@0+ (1.0,0.0) [0.0|1.0] "" ADD
 SG_ UDB46VCCD : 46|1@0+ (1.0,0.0) [0.0|1.0] "" ADD
 SG_ UDB47VCCD : 47|1@0+ (1.0,0.0) [0.0|1.0] "" ADD
 SG_ UDB49VCCD : 49|1@0+ (1.0,0.0) [0.0|1.0] "" ADD
 SG_ UDB50VCCD : 50|1@0+ (1.0,0.0) [0.0|1.0] "" ADD
 SG_ UDB51VCCD : 51|1@0+ (1.0,0.0) [0.0|1.0] "" ADD
 SG_ UDB52VCCD : 52|1@0+ (1.0,0.0) [0.0|1.0] "" ADD
 SG_ UDB53VCCD : 53|1@0+ (1.0,0.0) [0.0|1.0] "" ADD
 SG_ VCCDADDCANActiveWakeup : 12|1@0+ (1,0) [0|1] "" ADD
 SG_ VCCDADDCANNodeAddress : 7|8@0+ (1.0,0.0) [0.0|255.0] "" ADD
 SG_ VCCDADDCANRepeatMsgReq : 8|1@0+ (1,0) [0|1] "" ADD
 SG_ VCCDADDCANRepeatMsgSt : 16|1@0+ (1,0) [0|1] "" ADD

CM_ SG_ 1327 ADDCANActiveWakeup1 "Active Wakeup Bit";
CM_ SG_ 1327 ADDCANNodeAddress1 "Node source address";
CM_ SG_ 1327 ADDCANRepeatMsgReq1 "Repeat Message Request Bit";
CM_ SG_ 1327 ADDCANRepeatMsgSt1 "Repeat Message State indication";
CM_ SG_ 425 IMUCalSt "IMUCalibrationSt
IMU标定状态";
CM_ SG_ 425 LonAccr "Longititude Acceleration
纵向加速度";
CM_ SG_ 425 LonSnsrSt "Longititude Sensor State
纵向加速度有效性";
CM_ SG_ 426 LatAccr "Lateral Acceleration
横向加速度";
CM_ SG_ 426 LatAccrSt "Lateral Sensor State
横向加速度有效性";
CM_ SG_ 426 YawRate "Yaw Rate
横摆角速度";
CM_ SG_ 426 YawRateSnsrSt "Yaw Rate Sensor State
横摆角速度有效性";
CM_ SG_ 848 ACUWarnLampSts "Airbag Warning Lamp Status 
ACU故障灯信号";
CM_ SG_ 848 DrvrBucSts "Driver Buckle Status 
主驾驶安全带扣状态";
CM_ SG_ 848 PassBucSts "Passenger Buckle Status
副驾安全带状态";
CM_ SG_ 849 ImpctEvntSts "Impact Event Status
 碰撞事件状态";
CM_ SG_ 444 RCAvailable "远控设备可用";
CM_ SG_ 444 RPARemReq "遥控泊车APP开关";
CM_ SG_ 657 BLEM2VCCDForLocn10 "BLEM to VCCD For Phone1 location";
CM_ SG_ 657 BLEM2VCCDForLocn11 "BLEM to VCCD For Phone1 location";
CM_ SG_ 657 BLEM2VCCDForLocn12 "BLEM to VCCD For Phone1 location";
CM_ SG_ 657 BLEM2VCCDForLocn13 "BLEM to VCCD For Phone1 location";
CM_ SG_ 657 BLEM2VCCDForLocn14 "BLEM to VCCD For Phone1 location";
CM_ SG_ 657 BLEM2VCCDForLocn15 "BLEM to VCCD For Phone1 location";
CM_ SG_ 657 BLEM2VCCDForLocn16 "BLEM to VCCD For Phone1 location";
CM_ SG_ 657 BLEM2VCCDForLocn17 "BLEM to VCCD For Phone1 location";
CM_ SG_ 657 BLEM2VCCDForLocn18 "BLEM to VCCD For Phone1 location";
CM_ SG_ 657 BLEM2VCCDForLocn19 "BLEM to VCCD For Phone1 location";
CM_ SG_ 657 BLEM2VCCDForLocn1A "BLEM to VCCD For Phone1 location";
CM_ SG_ 657 BLEM2VCCDForLocn1B "BLEM to VCCD For Phone1 location";
CM_ SG_ 657 BLEM2VCCDForLocn1C "BLEM to VCCD For Phone1 location";
CM_ SG_ 657 BLEM2VCCDForLocn1D "BLEM to VCCD For Phone1 location";
CM_ SG_ 657 BLEM2VCCDForLocn1F "BLEM to VCCD For Phone1 location";
CM_ SG_ 663 SndBLEKeyPosnToRPA "Send BLE key message to RPA module";
CM_ SG_ 665 BLEM2VCCDForLocn20 "BLEM to VCCD For Phone2 location";
CM_ SG_ 665 BLEM2VCCDForLocn21 "BLEM to VCCD For Phone2 location";
CM_ SG_ 665 BLEM2VCCDForLocn22 "BLEM to VCCD For Phone2 location";
CM_ SG_ 665 BLEM2VCCDForLocn23 "BLEM to VCCD For Phone2  location";
CM_ SG_ 665 BLEM2VCCDForLocn24 "BLEM to VCCD For Phone2 location";
CM_ SG_ 665 BLEM2VCCDForLocn25 "BLEM to VCCD For Phone2 location";
CM_ SG_ 665 BLEM2VCCDForLocn26 "BLEM to VCCD For Phone2 location";
CM_ SG_ 665 BLEM2VCCDForLocn27 "BLEM to VCCD For Phone2 location";
CM_ SG_ 665 BLEM2VCCDForLocn28 "BLEM to VCCD For Phone2 location";
CM_ SG_ 665 BLEM2VCCDForLocn29 "BLEM to VCCD For Phone2 location";
CM_ SG_ 665 BLEM2VCCDForLocn2A "BLEM to VCCD For Phone2 location";
CM_ SG_ 665 BLEM2VCCDForLocn2B "BLEM to VCCD For Phone2 location";
CM_ SG_ 665 BLEM2VCCDForLocn2C "BLEM to VCCD For Phone2 location";
CM_ SG_ 665 BLEM2VCCDForLocn2D "BLEM to VCCD For Phone2 location";
CM_ SG_ 665 BLEM2VCCDForLocn2F "BLEM to VCCD For Phone2 location";
CM_ SG_ 817 BLEM2VCCDForLocn40 "BLEM to VCCD For Phone4 location";
CM_ SG_ 817 BLEM2VCCDForLocn41 "BLEM to VCCD For Phone4 location";
CM_ SG_ 817 BLEM2VCCDForLocn42 "BLEM to VCCD For Phone4 location";
CM_ SG_ 817 BLEM2VCCDForLocn43 "BLEM to VCCD For Phone4 location";
CM_ SG_ 817 BLEM2VCCDForLocn44 "BLEM to VCCD For Phone4 location";
CM_ SG_ 817 BLEM2VCCDForLocn45 "BLEM to VCCD For Phone4 location";
CM_ SG_ 817 BLEM2VCCDForLocn46 "BLEM to VCCD For Phone4 location";
CM_ SG_ 817 BLEM2VCCDForLocn47 "BLEM to VCCD For Phone4 location";
CM_ SG_ 817 BLEM2VCCDForLocn48 "BLEM to VCCD For Phone4 location";
CM_ SG_ 817 BLEM2VCCDForLocn49 "BLEM to VCCD For Phone4 location";
CM_ SG_ 817 BLEM2VCCDForLocn4A "BLEM to VCCD For Phone4 location";
CM_ SG_ 817 BLEM2VCCDForLocn4B "BLEM to VCCD For Phone4 location";
CM_ SG_ 817 BLEM2VCCDForLocn4C "BLEM to VCCD For Phone4 location";
CM_ SG_ 817 BLEM2VCCDForLocn4D "BLEM to VCCD For Phone4 location";
CM_ SG_ 817 BLEM2VCCDForLocn4F "BLEM to VCCD For Phone4 location";
CM_ SG_ 825 BLEM2ADDForRPA00 "RPA路由功能";
CM_ SG_ 825 BLEM2ADDForRPA01 "RPA路由功能";
CM_ SG_ 825 BLEM2ADDForRPA02 "RPA路由功能";
CM_ SG_ 825 BLEM2ADDForRPA03 "RPA路由功能";
CM_ SG_ 826 BLEM2VCCDForLocn30 "BLEM to VCCD For Phone3 location";
CM_ SG_ 826 BLEM2VCCDForLocn31 "BLEM to VCCD For Phone3 location";
CM_ SG_ 826 BLEM2VCCDForLocn32 "BLEM to VCCD For Phone3 location";
CM_ SG_ 826 BLEM2VCCDForLocn33 "BLEM to VCCD For Phone3 location";
CM_ SG_ 826 BLEM2VCCDForLocn34 "BLEM to VCCD For Phone3 location";
CM_ SG_ 826 BLEM2VCCDForLocn35 "BLEM to VCCD For Phone3 location";
CM_ SG_ 826 BLEM2VCCDForLocn36 "BLEM to VCCD For Phone3 location";
CM_ SG_ 826 BLEM2VCCDForLocn37 "BLEM to VCCD For Phone3 location";
CM_ SG_ 826 BLEM2VCCDForLocn38 "BLEM to VCCD For Phone3 location";
CM_ SG_ 826 BLEM2VCCDForLocn39 "BLEM to VCCD For Phone3 location";
CM_ SG_ 826 BLEM2VCCDForLocn3A "BLEM to VCCD For Phone3 location";
CM_ SG_ 826 BLEM2VCCDForLocn3B "BLEM to VCCD For Phone3 location";
CM_ SG_ 826 BLEM2VCCDForLocn3C "BLEM to VCCD For Phone3 location";
CM_ SG_ 826 BLEM2VCCDForLocn3D "BLEM to VCCD For Phone3 location";
CM_ SG_ 826 BLEM2VCCDForLocn3F "BLEM to VCCD For Phone3 location";
CM_ SG_ 579 BattSocRaw "Battery State of charge raw
电池SOC";
CM_ SG_ 579 BattURaw "Battery Voltage raw
电池电压";
CM_ SG_ 549 ADSELKSwtSet "紧急车道保持开关
ADS ELK switch set";
CM_ SG_ 549 ADSFltQuitReqFrmDCD "路面感知系统 SR 监控上游模块失活 请求智驾功能降级";
CM_ SG_ 549 DCDDisplayFailSts "Center Display Fail Status
座舱中控显示失效状态";
CM_ SG_ 549 DCDSteerWhlExtrMirrHUDAdjFlg "DCD steering wheel and externel mirror and HUD adjust flag";
CM_ SG_ 720 DCDDMSCameraFltSts "DMS camera fault Status
DMS摄像头故障信息";
CM_ SG_ 720 DCDDMSdstrctnDetnSts "DCD DMS distraction  Detection status
分心检测开启状态";
CM_ SG_ 720 DCDDMSdstrctnSts "DCD DMS distraction status
分心程度";
CM_ SG_ 720 DCDDMSFatgDetnSts "DCD DMS fatigue Detection status
疲劳检测开启状态";
CM_ SG_ 720 DCDDMSfatgSts "DCD DMS fatigue status
疲劳程度";
CM_ SG_ 720 DCDDMSSysFltSts "DMS system fault Status
DMS系统故障信息";
CM_ SG_ 720 DCDDVRSrvReq "DCD DVR Service Request";
CM_ SG_ 720 DCDGameModSts "DCD Game Mode Status";
CM_ SG_ 720 DCDPrivacyModeStatus "一键隐私模式状态";
CM_ SG_ 720 DCDsentryModReq "DCD sentry mode request";
CM_ SG_ 720 DCDsentryModSts "DCD sentry mode status";
CM_ SG_ 720 DCDTSASLIFSwtSts "TSA-SLIF speed warning type status";
CM_ SG_ 720 SRMode "SRMode
SR状态";
CM_ SG_ 833 ALCLrnSts "ALC  learn status";
CM_ SG_ 833 AVPLrnSts "AVP learn status";
CM_ SG_ 833 DCDAdCode "Address Code of current city.";
CM_ SG_ 833 DCDCameraSpdLim "Camera speed limit within 200m.";
CM_ SG_ 833 DCDNavSts "Navigation status.";
CM_ SG_ 833 DCDRoadClass "Current road class.";
CM_ SG_ 833 DCDRoadFacSpdLim "Road facility speed limit.";
CM_ SG_ 833 DCDRoadType "Type of current road. For detailed definition of signal value  please refer to Navigation SC.";
CM_ SG_ 833 DCDTrfcSts "Traffice status of current road segment.";
CM_ SG_ 833 DCDTSASlifSpdDisp "TSA SLIF speed display";
CM_ SG_ 833 DstUnitDisp "Unit of distance from DCD";
CM_ SG_ 833 HPPLrnSts "HPP  learn status";
CM_ SG_ 833 NOACtyLrnSts "NOA-City  learn status";
CM_ SG_ 833 NOAHWLrnSts "NOA-Highway learn status";
CM_ SG_ 833 PltLrnSts "Pilot  learn status";
CM_ SG_ 833 VehInsSpdDisp "Vehicle instantaneous speed display";
CM_ SG_ 833 VehInsSpdDispIntnal "Vehicle instantaneous speed display for internal";
CM_ SG_ 833 VehInsSpdDispVld "Vehicle instantaneous speed display Valid";
CM_ SG_ 837 DCDAccountLogTyp "DCD Account log type ,DCD 账号切换方式";
CM_ SG_ 837 DCDAcctMod "DCD Account Mode
账号模式";
CM_ SG_ 837 DCDCloudSysnc "DCD Cloud Sysnc switch云同步开关状态";
CM_ SG_ 837 DCDCurProID "DCD Current ProfileID
用户当前使用习惯ID";
CM_ SG_ 837 DCDGstMod "DCD Guest Mode";
CM_ SG_ 837 DCDICVehCustExperImprvProgSts "网联车系统服务用户改进计划开关状态
DCDICVehCustExperImprvProgSts Intelligent Connected Vehicle Customer Experience Improvement Program Status";
CM_ SG_ 837 DCDICVehSrvAuthntSts "网联车系统服务授权状态
Intelligent Connected Vehicle  Service Authorization status";
CM_ SG_ 837 DCDUserIDBytePos0 "DCD UserID Position Byte 0";
CM_ SG_ 837 DCDUserIDBytePos1 "DCD UserID Position Byte 1";
CM_ SG_ 837 DCDUserIDBytePos10 "DCD UserID Position Byte 10";
CM_ SG_ 837 DCDUserIDBytePos11 "DCD UserID Position Byte 11";
CM_ SG_ 837 DCDUserIDBytePos12 "DCD UserID Position Byte 12";
CM_ SG_ 837 DCDUserIDBytePos13 "DCD UserID Position Byte 13";
CM_ SG_ 837 DCDUserIDBytePos14 "DCD UserID Position Byte 14";
CM_ SG_ 837 DCDUserIDBytePos15 "DCD UserID Position Byte 15";
CM_ SG_ 837 DCDUserIDBytePos2 "DCD UserID Position Byte 2";
CM_ SG_ 837 DCDUserIDBytePos3 "DCD UserID Position Byte 3";
CM_ SG_ 837 DCDUserIDBytePos4 "DCD UserID Position Byte 4";
CM_ SG_ 837 DCDUserIDBytePos5 "DCD UserID Position Byte 5";
CM_ SG_ 837 DCDUserIDBytePos6 "DCD UserID Position Byte 6";
CM_ SG_ 837 DCDUserIDBytePos7 "DCD UserID Position Byte 7";
CM_ SG_ 837 DCDUserIDBytePos8 "DCD UserID Position Byte 8";
CM_ SG_ 837 DCDUserIDBytePos9 "DCD UserID Position Byte 9";
CM_ SG_ 914 TotOdoAcrt "ODO";
CM_ SG_ 914 TotOdoAcrtLvlM "Total odometer accurate for meter level
米级精确总里程
其中，有效范围：0x0~0x?3B9AC9FF?，表示0~999,999,999";
CM_ SG_ 914 TotOdoAcrtLvlMVld "Total odometer accurate for meter level valid
米级精确总里程有效性";
CM_ SG_ 914 TotOdoAcrtVld "The valid signal of TotOdoAcrt";
CM_ SG_ 932 ADSAEBFCWSwtSet "自动紧急制动开关
AEB switch set";
CM_ SG_ 932 ADSAESESSSwtSet "自动紧急转向避障开关
AES_ESS switch set";
CM_ SG_ 932 ADSAPPOpenReq "智驾中心点击请求";
CM_ SG_ 932 ADSBSDLCASwtSet "盲区监测与换道辅助开关
ADS BSD LCA Switch Set";
CM_ SG_ 932 ADSDOWSwtSet "开门预警开关
DOW Switch set";
CM_ SG_ 932 ADSPMAEBSwtSet "近距离防撞辅助开关设置
Parking And Maneuvering Automatic Emergency Brake switch Set";
CM_ SG_ 932 ADSRCWSwtSet "后方防撞辅助开关
RCW Switch set";
CM_ SG_ 932 ADSTLASwtSet "ADS TLA Switch Set
智驾红绿灯提醒开关";
CM_ SG_ 932 ADSVcCtrlSwtSet "语音控制功能开关
ADS voice control switch set";
CM_ SG_ 932 APASwtSet "辅助泊车开关
APA Switch set";
CM_ SG_ 932 AVPSwtSet "无人代客泊车开关
AVP Switch set";
CM_ SG_ 932 DCD2RDParkinChoseButton "Driver Choose 2RD Parkin
二次泊入请求";
CM_ SG_ 932 DCDACCInitSpdSwtSet "intelligent speed limit control  switch";
CM_ SG_ 932 DCDAdsAutoTurnLiSwtSet "DCD Adas Auto Turn Light switch set";
CM_ SG_ 932 DCDAdsIntelgntSpdSwtSet "DCD Adas Intelligent Speed switch set
智能车速开关设置";
CM_ SG_ 932 DCDADSMAISwtSet "Miss Acceleration Inhibition
误踩油门抑制";
CM_ SG_ 932 DCDAdsModSwtSet "DCD Adas Mode Switch Set";
CM_ SG_ 932 DCDAdsNOAOddSwtSet "DCD Adas NOA ODD Switch Set";
CM_ SG_ 932 DCDADSRCTABSwtSet "RCTA and RCTB switch";
CM_ SG_ 932 DCDAdsTrfcLiCtrlSwtSet "DCD Adas Traffic Light Control Switch Set";
CM_ SG_ 932 DCDADSVcCtrlDstSet "Voice Control Distance Set";
CM_ SG_ 932 DCDADSVcCtrlSpdSet "Voice Control Speed Set";
CM_ SG_ 932 DCDAdsVehDeturSwtSet "DCD Adas Vehicle Detour Switch Set";
CM_ SG_ 932 DCDAPAButton "Driver Choose Start or Stop APA
用户选择开始泊车或暂停泊车";
CM_ SG_ 932 DCDAPAParkOutButton "Driver Choose to Start Parking Out
用户选择开始泊出";
CM_ SG_ 932 DCDAPAParkOutDireSelect "Driver Choose ParkOut Direction
用户选择泊出方向";
CM_ SG_ 932 DCDAPAParkSlotSelect "Driver Choose Target Park Slot
用户选择目标车位";
CM_ SG_ 932 DCDAPAPIPOReq "Driver Choose APA Parkin Parkout
用户选择泊车类型";
CM_ SG_ 932 DCDAPAQuitReq "Driver Choose Quit APA
用户请求退出泊车";
CM_ SG_ 932 DCDAPAVcCtl "APA  Voice Control";
CM_ SG_ 932 DCDAudModSwtSet "ADS Audio Switch set";
CM_ SG_ 932 DCDAutoVehCustExperImprvProgSwt "智能驾驶用户体验改进计划开关 
Autonomous Vehicle Customer Experience Improvement Program Switch";
CM_ SG_ 932 DCDAutoVehSrvAuthntSwt "智能驾驶服务授权  Autonomous Vehicle Service Authorization";
CM_ SG_ 932 DCDBackMapDfltParkSlotReq "后台静默图使用默认车位泊车请求";
CM_ SG_ 932 DCDFxdSpdModValSwtSet "固定车速偏差数值设置
Fixed speed mode value switch";
CM_ SG_ 932 DCDHPPBckGrLearSwtSet "HPP background learn switch";
CM_ SG_ 932 DCDHPPBckGrPathAutDoLoSet "HPP path background auto download switch";
CM_ SG_ 932 DCDHPPChoseSaveRoute "路线保存 用户选择保存与否";
CM_ SG_ 932 DCDHPPLnVcReq "HPP Learn Voice Control Request";
CM_ SG_ 932 DCDHPPLrnReq "HPP Learn Request
HPP 学习请求";
CM_ SG_ 932 DCDHPPParkAlTheWay "沿途泊车请求";
CM_ SG_ 932 DCDHPPParkingButton "沿途泊入请求开始泊车";
CM_ SG_ 932 DCDHPPPrkReq "HPP Parking Request
HPP 开启请求";
CM_ SG_ 932 DCDLdwLdpWarnTypSwtSet "LDW And LDP warning type switch set
车道辅助系统报警类型设置";
CM_ SG_ 932 DCDLVPwrSwtSet "Low power mode switch";
CM_ SG_ 932 DCDParkAudModSwtSet "DCD Parking Audio Mode Switch Set";
CM_ SG_ 932 DCDParkSpdSwtSet "DCD Park Speed Switch Setting
DCD泊车速度选项设置";
CM_ SG_ 932 DCDPcntgeSpdModValSwtSet "百分比车速偏差数值设置
Percentage speed mode value switch";
CM_ SG_ 932 DCDPntCldSwtSet "Point cloud control  switch";
CM_ SG_ 932 DCDTouchdSpdTyp "DCD touched Speed Type";
CM_ SG_ 932 HPPSwtSet "记忆泊车开关
HPP Switch set";
CM_ SG_ 932 HwNOASwtSet "高速NOA功能开关
Highway NOA Switch set";
CM_ SG_ 932 LdwLdpSwtSet "车道偏离报警 车道偏离纠偏开关
LDW And LDP Switch set";
CM_ SG_ 932 LidarCloudMode "Lidar cloud mode feedback from SR";
CM_ SG_ 932 NoaLcSwtSet "变道确认功能开关
NOA Lane Change Switch set";
CM_ SG_ 932 PltSwtALCSet "转向灯变道功能开关
Pilot Switch ALC set";
CM_ SG_ 932 PltSwtSet "PILOT功能开关
Pilot Switch set";
CM_ SG_ 932 ScrnTouchdFuncChange "Screen Touched driving function change";
CM_ SG_ 932 ScrnTouchdLaneChange "Screen Touched lane change";
CM_ SG_ 932 ScrnTouchdSpd "用户点击中控限速值或中控车速值调节的车速大小";
CM_ SG_ 932 ScrnTouchdSpdTyp "Screen Touched Speed Type";
CM_ SG_ 932 VehSpdDvtionModSwtSet "Vehicle speed divation mode switch";
CM_ SG_ 784 EdsCircCooltTSnsrU "Coolant temperature sensor voltage at EDS coolant circuit";
CM_ SG_ 784 FLRLLoPwrSplySts "FLRL Low Power Supply Status
长距激光雷达配电状态";
CM_ SG_ 784 IMULoPwrSplySts "IMU Low Power Supply Status
IMU低压配电状态";
CM_ SG_ 784 LRRLoPwrSplySts "LRR low Power Supply Status
前向毫米波雷达配电状态";
CM_ SG_ 784 LSLLoPwrSplySts "LSL Low Power Supply Status
左前侧短距激光雷达低压输出状态";
CM_ SG_ 784 RSLLoPwrSplySts "RSL Low Power Supply Status
右前激光雷达低压配电状态";
CM_ SG_ 396 LRRSnsrStsFrmSFC "front center radar working status, bitfield
bit0=Misalignment
bit1=Blindness
bit2=HW failure
bit3=Emission off w/o failure
bit4=Not calibrated
bit5=Temp out of range
bit6=Reserved
bit7=Reserved
bit8=Reserved";
CM_ SG_ 434 DoorDrvrPwrRelsMotDrvSts "主驾电释放电机驱动状态";
CM_ SG_ 607 AswmLinComFltSts "ASWM LIN node communication fault status.";
CM_ SG_ 607 HandOnDetnStsSigGrpLinErr "HandOnDetnStsSigGrp LIN communication Error";
CM_ SG_ 607 HandsOnDetectionErrorStatus "方向盘离手检测故障状态";
CM_ SG_ 607 HandsOnDetectionStatus "方向盘离手检测状态";
CM_ SG_ 607 StsOfBSDLampLe "Status Of Left BSD Lamp
左BSD 灯状态";
CM_ SG_ 892 DrvrOcupcySts "Driver Occupancy Sensor Status
主驾座椅占位传感器检测状态";
CM_ SG_ 368 RLSRRCTBBrkReqFrmSFC "RCTB Brake request - rear left radar";
CM_ SG_ 368 RLSRRCTBTarDecelFrmSFC "target deceleration value from RCTB - rear left radar";
CM_ SG_ 391 RLSRBSDLCAStsFrmSFC "BSD_LCA Function status - rear left radar";
CM_ SG_ 391 RLSRBSDLCASwtFbFrmSFC "左雷达BSD开关反馈信息";
CM_ SG_ 391 RLSRBSDLCASwtUnavlRsnFrmSFC "左雷达BSDLCA 开关不可用原因";
CM_ SG_ 391 RLSRBSDLCAWarnReqFrmSFC "BSD_LCA warning request - rear left radar";
CM_ SG_ 391 RLSRDOWStsFrmSFC "DOW Function status - rear left radar";
CM_ SG_ 391 RLSRDOWSwtFbFrmSFC "左雷达DOW开关反馈信息";
CM_ SG_ 391 RLSRDOWSwtUnavlRsnFrmSFC "左雷达DOW 开关不可用原因";
CM_ SG_ 391 RLSRDOWWarnReqFrFrmSFC "DOW warning request - front left";
CM_ SG_ 391 RLSRDOWWarnReqReFrmSFC "DOW warning request - rear left";
CM_ SG_ 391 RLSRRCTABSwtFbFrmSFC "左雷达RCTB开关反馈信息";
CM_ SG_ 391 RLSRRCTABSwtUnavlRsnFrmSFC "左雷达RCTA_RCTB 开关不可用原因";
CM_ SG_ 391 RLSRRCTAStsFrmSFC "RCTA Function status - rear left radar";
CM_ SG_ 391 RLSRRCTAWarnReqFrmSFC "RCTA warning request - rear left radar";
CM_ SG_ 391 RLSRRCTBStsFrmSFC "RCTB Function status - rear left radar";
CM_ SG_ 391 RLSRRCTBWarnReqFrmSFC "RCTB warning request  - rear left radar";
CM_ SG_ 391 RLSRRCWStsFrmSFC "RCW Function status - rear left radar";
CM_ SG_ 391 RLSRRCWSwtFbFrmSFC "RCW switch feedback - rear left radar";
CM_ SG_ 391 RLSRRCWSwtUnavlRsnFrmSFC "左雷达RCW 开关不可用原因";
CM_ SG_ 391 RLSRRCWWarnReqFrmSFC "RCW warning request - rear left radar";
CM_ SG_ 701 RLSRSnsrStsFrmSFC "rear left radar working status, bitfield
bit0=Misalignment
bit1=Blindness
bit2=HW failure
bit3=Emission off w/o failure
bit4=Not calibrated
bit5=Temp out of range
bit6=Reserved
bit7=Reserved
bit8=Reserved";
CM_ SG_ 383 RRSRRCTBBrkReqFrmSFC "RCTB Brake request - rear right radar";
CM_ SG_ 383 RRSRRCTBTarDecelFrmSFC "target deceleration value from RCTB - rear right radar";
CM_ SG_ 392 RRSRBSDLCAStsFrmSFC "BSD_LCA Function status - rear right radar";
CM_ SG_ 392 RRSRBSDLCASwtFbFrmSFC "右雷达BSD开关反馈信息";
CM_ SG_ 392 RRSRBSDLCASwtUnavlRsnFrmSFC "右雷达BSDLCA 开关不可用原因";
CM_ SG_ 392 RRSRBSDLCAWarnReqFrmSFC "BSD_LCA warning request - rear right radar";
CM_ SG_ 392 RRSRDOWStsFrmSFC "DOW Function status - rear right radar";
CM_ SG_ 392 RRSRDOWSwtFbFrmSFC "右雷达DOW开关反馈信息";
CM_ SG_ 392 RRSRDOWSwtUnavlRsnFrmSFC "右雷达DOW 开关不可用原因";
CM_ SG_ 392 RRSRDOWWarnReqFrFrmSFC "DOW warning request - front right";
CM_ SG_ 392 RRSRDOWWarnReqReFrmSFC "DOW warning request - rear right";
CM_ SG_ 392 RRSRRCTABSwtFbFrmSFC "右雷达RCTB开关反馈信息";
CM_ SG_ 392 RRSRRCTABSwtUnavlRsnFrmSFC "右雷达RCTA_RCTB 开关不可用原因";
CM_ SG_ 392 RRSRRCTAStsFrmSFC "RCTA Function status - rear right radar";
CM_ SG_ 392 RRSRRCTAWarnReqFrmSFC "RCTA warning request - rear right radar";
CM_ SG_ 392 RRSRRCTBStsFrmSFC "RCTB Function status - rear right radar";
CM_ SG_ 392 RRSRRCTBWarnReqFrmSFC "RCTB warning request  - rear right radar";
CM_ SG_ 392 RRSRRCWStsFrmSFC "RCW Function status - rear right radar";
CM_ SG_ 392 RRSRRCWSwtFbFrmSFC "RCW switch feedback - rear right radar";
CM_ SG_ 392 RRSRRCWSwtUnavlRsnFrmSFC "右雷达RCW 开关不可用原因";
CM_ SG_ 392 RRSRRCWWarnReqFrmSFC "RCW warning request - rear right radar";
CM_ SG_ 523 RRSRSnsrStsFrmSFC "rear right radar working status, bitfield
bit0=Misalignment
bit1=Blindness
bit2=HW failure
bit3=Emission off w/o failure
bit4=Not calibrated
bit5=Temp out of range
bit6=Reserved
bit7=Reserved
bit8=Reserved";
CM_ SG_ 602 RlsRainFallAmnt "雨量";
CM_ SG_ 602 RlsRainFallSts "下雨状态";
CM_ SG_ 602 RlsRainSnsrFlt "雨量传感器故障";
CM_ SG_ 616 RlsAutWinWipgSpdCmd "雨刮速度请求";
CM_ SG_ 616 RlsFwdLiSnsrVal "前向光线亮度";
CM_ SG_ 616 RlsFwdLiSnsrValUnit "前向光线亮度单位";
CM_ SG_ 616 RlsHudSnsrVal "Hud亮度";
CM_ SG_ 616 RlsHudSnsrValUnit "Hud亮度单位";
CM_ SG_ 616 RlsIRVal "红外光值输出";
CM_ SG_ 616 RlsLiSigGrpLinErr "RlsLiSigGrp LIN communication Error";
CM_ SG_ 616 RlsLiSnsrFwdFlt "RLS光线传感器 前向 故障";
CM_ SG_ 616 RlsLiSnsrIRFlt "RLS光线传感器 IR红外 故障";
CM_ SG_ 616 RlsLiSnsrTopFlt "RLS光线传感器 顶向 故障";
CM_ SG_ 616 RlsOutdBriSts "白天 黑夜 隧道检测";
CM_ SG_ 616 RlsSts "雨量阳光传感器状态";
CM_ SG_ 616 RlsTopLiSnsrVal "Top Light Value
顶向光线亮度";
CM_ SG_ 616 RlsTopLiSnsrValUnit "顶部光线亮度单位";
CM_ SG_ 616 StsOfBSDLampRi "Status Of Right BSD Lamp
右BSD灯状态";
CM_ SG_ 768 RSRLoPwrSplySts "RSR Low Power Supply Status
后毫米波雷达配电状态";
CM_ SG_ 893 PassOcupcySts "Passenger Occupancy Sensor  Status
副驾座椅占位传感器检测状态";
CM_ SG_ 342 ASCFltSts "Air spring control fault status";
CM_ SG_ 342 CDCFltSts "Continuous Daming control fault status";
CM_ SG_ 342 CurDampgCtrlMod "Current active damping control mode";
CM_ SG_ 342 ESPEnaReq "ESC OFF NOT ALLOWED";
CM_ SG_ 342 JackModSts "Level Control deactivation request status  Jack Mode";
CM_ SG_ 342 LvlAdjmtSts "level control mode adjustment status  ie. Lowering from Normal to Low";
CM_ SG_ 342 LvlModAct "Height Level Mode Actual";
CM_ SG_ 342 SCUExtmHeiSts "SCU Extreme Height Status
SCU 悬架极高极低状态";
CM_ SG_ 342 SCULimSpdTqReq "SCU 限速限扭请求
SCU Limit Speed Torque Request";
CM_ SG_ 342 SCUWarnLampReq "SCU Warning Lamp Request
SCU 故障灯请求";
CM_ SG_ 342 SCUWarnMsgASC "SCU Warning Message ASC
空气悬架故障警示信号";
CM_ SG_ 342 SCUWarnMsgCDC "SCU Warning Message CDC
电控减震器故障警示信号";
CM_ SG_ 182 FrntLeCurHei "Front Left Current Height";
CM_ SG_ 182 FrntLeCurHeiSts "Front Left Current Height status";
CM_ SG_ 182 FrntRiCurHei "Front Right Current Height";
CM_ SG_ 182 FrntRiCurHeiSts "Front Right Current Height status";
CM_ SG_ 182 ReLeCurHei "Rear Left Current Height";
CM_ SG_ 182 ReLeCurHeiSts "Rear Left Current Height status";
CM_ SG_ 182 ReRiCurHei "Rear Right Current Height";
CM_ SG_ 182 ReRiCurHeiSts "Rear Right Current Height status";
CM_ SG_ 419 SwtIndcrRaw "组合开关转向灯请求命令";
CM_ SG_ 263 DateTiDay "date time day";
CM_ SG_ 263 DateTiHr "date time hour";
CM_ SG_ 263 DateTiMilsec "date time millisecond";
CM_ SG_ 263 DateTiMins "date time minute";
CM_ SG_ 263 DateTiMth "date time month";
CM_ SG_ 263 DateTiSec "date time second";
CM_ SG_ 263 DateTiYr "date time year";
CM_ SG_ 263 TiDomn "time domain";
CM_ SG_ 742 FrntLeTyrePVal "FrontLeftTyrePressureValue";
CM_ SG_ 742 FrntLeTyrePWarn "FrontLeftTyrePressureWarning";
CM_ SG_ 742 FrntRiTyrePVal "FrontRightTyrePressureValue";
CM_ SG_ 742 FrntRiTyrePWarn "FrontRightTyrePressureWarning";
CM_ SG_ 742 ReLeTyrePVal "RearLeftTyrePressureValue";
CM_ SG_ 742 ReLeTyrePWarn "RearLeftTyrePressureWarning";
CM_ SG_ 742 ReRiTyrePVal "RearRightTyrePressureValue";
CM_ SG_ 742 ReRiTyrePWarn "RearRightTyrePressureWarning";
CM_ SG_ 388 DiagcExtActv "diagnostic external connection activation";
CM_ SG_ 388 DoorDrvrPwrRelsDlyActv "主驾电释放延迟激活反馈";
CM_ SG_ 388 DoorDrvrSts "驾驶侧门状态";
CM_ SG_ 388 DoorLeRePwrRelsDlyActv "左后电释放延迟激活反馈";
CM_ SG_ 388 DoorLeReSts "左后侧门状态";
CM_ SG_ 388 DoorPassPwrRelsDlyActv "副驾电释放延迟激活反馈";
CM_ SG_ 388 DoorPassSts "副驾侧门状态";
CM_ SG_ 388 DoorRiRePwrRelsDlyActv "右后电释放延迟激活反馈";
CM_ SG_ 388 DoorRiReSts "右后侧门状态";
CM_ SG_ 388 ExtrMirrFoldEnaFailr "外后视镜折叠故障";
CM_ SG_ 388 ExtrMirrFoldSts "后视镜折叠状态";
CM_ SG_ 388 HoodOpenClsSts "Hood Open Close Status
前舱盖开启关闭状态";
CM_ SG_ 388 LeMirrFoldCmd "左侧外后视镜折叠请求";
CM_ SG_ 388 RiMirrFoldCmd "右侧外后视镜折叠请求";
CM_ SG_ 388 TrOpenClsSts "Trunk Open Close Status";
CM_ SG_ 388 VCUGearChgFailrSts "Gear change failure status";
CM_ SG_ 388 VCULatSlopForDisp "侧向坡度";
CM_ SG_ 388 VCULgtSlopForDisp "纵向坡度";
CM_ SG_ 388 VCUSpclRoadSurfTypForDisp "路面特征";
CM_ SG_ 514 ExtrLtgStsHiBeam "远光灯总状态";
CM_ SG_ 514 ExtrLtgStsLoBeam "近光总状态";
CM_ SG_ 514 ExtrLtgStsStop "刹车灯状态总反馈";
CM_ SG_ 514 ExtrLtgStsTurnIndrLe "左转向灯状态汇总";
CM_ SG_ 514 ExtrLtgStsTurnIndrRi "右转向灯状态汇总";
CM_ SG_ 514 LVPwrSplyBattErrSts "Low power supply battery error status
低压供电电池故障状态";
CM_ SG_ 514 LVPwrSplyDCDCErrSts "Low voltage Power Supply DCDC Error Statue
DCDC故障导致的低压供电问题";
CM_ SG_ 514 LVPwrSplyHiErrSts "Low power supply high error status
低压供电高风险故障状态";
CM_ SG_ 514 LVPwrSplyLoErrSts "Low power supply low error status
低压供电低风险故障状态";
CM_ SG_ 514 OTALowEgy "OTA request to enter low engergy mode
OTA请求ECU进入低功耗模式";
CM_ SG_ 514 OTAMode "OTA模式";
CM_ SG_ 514 SBLDmValSetLe "Left Static bending Light Dimming Value setting";
CM_ SG_ 514 SBLDmValSetRi "Left Static bending Light Dimming Value setting";
CM_ SG_ 514 StsOfIndcr "转向状态指示";
CM_ SG_ 514 SwtIndcr "转向拨杆信号";
CM_ SG_ 514 SwtIndcrSts "Switch Indicator Status";
CM_ SG_ 514 VCUAccrPrmSetAllwd "VCU accelerate parameter Setting allowed
驾驶模式加速特性参数设置允许";
CM_ SG_ 514 VCUActDrvMod "VCU actual drive mode 
VCU实际驾驶模式";
CM_ SG_ 514 VCUBatModAllwd "VCU Battle Mode Allowed
VCU赛道模式允许使用";
CM_ SG_ 514 VCUBrkPedlFeelStAllwd "VCU brake feeling parameter Setting allowed
驾驶模式制动踏板感特性参数设置允许";
CM_ SG_ 514 VCUDriftModSetSts "VCU Drift Mode Setting Status
VCU一键漂移功能设置状态";
CM_ SG_ 514 VCUDrvModRgnPrmSts "VCU Drive mode regeneration parameter Status
驾驶模式能量回收特性参数设置";
CM_ SG_ 514 VCUDrvModStSts "VCU Drive mode setting status
驾驶模式设定状态";
CM_ SG_ 514 VCUExtmECOModStReq "VCU Extremely ECO mode Request
极致经济模式请求";
CM_ SG_ 514 VCUExtmPfmncMod "VCU extreme performance mode
VCU狂暴模式";
CM_ SG_ 514 VCULnchPlusSts "VCU Launch plus status
VCU弹射模式状态";
CM_ SG_ 514 VCUOnePedlModAllwd "VCU One Pedal Mode Allowed
VCU单踏板模式允许";
CM_ SG_ 514 VCURgnPrmSetAllwd "VCU regeneration parameter  Setting allowed
驾驶模式能量回收特性参数设置允许";
CM_ SG_ 514 VCUSpdLimrSts "VCU Speed Limiter Status
VCU可调限速功能状态";
CM_ SG_ 514 VCUSpdLimrValSts "VCU Speed Limiter Value Status
VCU可调限速车速值";
CM_ SG_ 514 VCUSteerAsstPrmSetAllwd "VCU steering assistance parameter Setting allowed
驾驶模式转向助力参数设置允许";
CM_ SG_ 514 VCUSuspDampgPrmSetAllwd "VCU steering assistance parameter Setting allowed
驾驶模式悬架阻尼特性参数设置允许";
CM_ SG_ 514 VCUSuspLvlgPrm1Allwd "VCU suspension level parameter1 Setting allowed
驾驶模式悬架高度最高设置允许";
CM_ SG_ 514 VCUSuspLvlgPrm2Allwd "VCU suspension level parameter2 Setting allowed
驾驶模式悬架高度次高设置允许";
CM_ SG_ 514 VCUSuspLvlgPrm3Allwd "VCU suspension level parameter3 Setting allowed
驾驶模式悬架高度中设置允许";
CM_ SG_ 514 VCUSuspLvlgPrm4Allwd "VCU suspension level parameter4 Setting allowed
驾驶模式悬架高度次低设置允许";
CM_ SG_ 514 VCUSuspLvlgPrm5Allwd "VCU suspension level parameter5 Setting allowed
驾驶模式悬架高度最低设置允许";
CM_ SG_ 514 VCUTrlrModStSts "VCU Trailer Mode Setting Status
VCU反馈拖车模式设置状态";
CM_ SG_ 514 VCUWashModEntryAllwd "VCU Wash Mode Entry allowed
洗车模式允许进入";
CM_ SG_ 514 VCUWashModExtAllwd "VCU Wash Mode Exit allowed
洗车模式允许退出";
CM_ SG_ 514 VCUWashModStSts "VCU wash mode setting status 
VCU洗车模式设定状态";
CM_ SG_ 529 SecOCMAC1 "消息认证码1";
CM_ SG_ 529 SecOCMAC2 "消息认证码2";
CM_ SG_ 529 SecOCMAC3 "消息认证码3";
CM_ SG_ 529 SecOCResetCnt "重置计数器";
CM_ SG_ 529 SecOCTripCnt "同步计数器";
CM_ SG_ 689 ADDCooltCircFlowEstimd "Estimated coolant flowrate for ADD coolant circuit.";
CM_ SG_ 689 AmbTEstimd "Estimated ambient temperature.";
CM_ SG_ 689 AmbTEstimdVld "Estimated ambient temperature valid value.";
CM_ SG_ 689 EdsCircCooltT "Coolant temperature at EDS coolant circuit";
CM_ SG_ 689 EdsCircCooltTVld "Coolant temperature at EDS coolant circuit valid value";
CM_ SG_ 689 LockgCenLockSts "中控锁状态";
CM_ SG_ 689 OTALinkMgr "OTA服务唤醒与保持";
CM_ SG_ 689 SetMgrDrvrSeldDstLvl "Setmgr driver select distance level";
CM_ SG_ 689 VCUEgyCnsInCurDrvCyc "显示本次行程的电耗量";
CM_ SG_ 689 VCUEstimdCrsRng "Estimated range
续航里程值显示";
CM_ SG_ 689 VCUEstimdCrsRngForCltc "Cltc公告续航预测值";
CM_ SG_ 689 VCUEstimdCrsRngVld "Estimated range Validty
续航里程有效性";
CM_ SG_ 689 VCUInsEgyCnsDurgDrvg "瞬时电耗 行车状态";
CM_ SG_ 689 VCUInsEgyCnsDurgStsl "瞬时电耗 停车状态";
CM_ SG_ 689 VCUInsEgyCnsFlg "瞬时电耗标志位";
CM_ SG_ 689 VCUPwrFlowForDisp "驱动能量流指示";
CM_ SG_ 868 SetMgrAdsACCInitSpdSwt "SetMgr adas  ACC initial speed switch set";
CM_ SG_ 868 SetMgrAdsAEBFCWSwt "SetMgr adas AEB&FCW switch set";
CM_ SG_ 868 SetMgrAdsALCSwtSts "SetMgr adas  ALC switch set";
CM_ SG_ 868 SetMgrAdsAPA2SwtSts "SetMgr adas APA switch set2";
CM_ SG_ 868 SetMgrAdsAudModSwt "SetMgr adas audio mode  switch set";
CM_ SG_ 868 SetMgrAdsAutoTurnLiSwt "SetMgr Adas Auto Turn Light switch set";
CM_ SG_ 868 SetMgrAdsAVPSwtSts "SetMgr adas AVP  switch set";
CM_ SG_ 868 SetMgrAdsBSDLCASwt "SetMgr adas BSDLCA  switch set";
CM_ SG_ 868 SetMgrAdsCfgLoadReq "SetMgr Adas Configure Load Request";
CM_ SG_ 868 SetMgrAdsDOWSwt "SetMgr adas  DOW switch set";
CM_ SG_ 868 SetMgrAdsELKSwSts "ELK function Switch status of personalize system memory";
CM_ SG_ 868 SetMgrAdsFxdSpdModValSwt "SetMgr adas  speed diviation level switch set";
CM_ SG_ 868 SetMgrAdsHPPBckGrLear "SetMgr adas  HPP back gear switch set";
CM_ SG_ 868 SetMgrAdsHPPSwtSts "SetMgr adas  HPP switch set";
CM_ SG_ 868 SetMgrAdsIntelgntSpdSwt "SetMgr Adas Intelligent Speed switch set";
CM_ SG_ 868 SetMgrAdsLaneChgCnfmSwt "SetMgr adas LaneChg confirm  switch set";
CM_ SG_ 868 SetMgrAdsLDWPSwt "SetMgr adas LDWP switch set";
CM_ SG_ 868 SetMgrAdsLDWPWarnTypSwt "SetMgr adas LDWP Warnning type switch set";
CM_ SG_ 868 SetMgrAdsMAISwtSts "SetMgr MAI switch";
CM_ SG_ 868 SetMgrAdsModSwt "SetMgr ADAS mode switch Status";
CM_ SG_ 868 SetMgrAdsNOAHWSwtSts "SetMgr adas  NOAHW switch set";
CM_ SG_ 868 SetMgrAdsNOAOddSwt "SetMgr ADAS - NOA odd switch Status";
CM_ SG_ 868 SetMgrAdsParkAudModSwt "SetMgr Adas park audio mode switch";
CM_ SG_ 868 SetMgrAdsParkSpdSwtSts "SetMgr adas parking speed switch set2";
CM_ SG_ 868 SetMgrAdsPcntgeSpdlvlSwt "SetMgr adas  Pcntge speed level switch set";
CM_ SG_ 868 SetMgrAdsPltSwtSts "SetMgr adas Plt  switch set";
CM_ SG_ 868 SetMgrAdsPntCldSwt "SetMgr adas Pnt cloud  switch set";
CM_ SG_ 868 SetMgrAdsRCTABSwt "SetMgr adas  RCTAB switch set";
CM_ SG_ 868 SetMgrAdsRCWSwt "SetMgr adas RCW switch set";
CM_ SG_ 868 SetMgrAdsTLASwt "The TLA  function switch status signal that Personalize setting system stored and transmitted  
个性化设置系统存储并外发的TLA的功能开关状态信号";
CM_ SG_ 868 SetMgrAdsTrfcLiCtrlSwt "SetMgr ADAS Triffic Light Control Switch Status";
CM_ SG_ 868 SetMgrAdsVehDetourSwt "SetMgr ADAS Vehicle Detour Switch Status";
CM_ SG_ 868 SetMgrAdsVehSpdDvtnModSwt "SetMgr adas  vehicle speed diviation mode switch set";
CM_ SG_ 868 VCUBattOverHeatWarn "电池过温时 仪表点亮电池过温报警灯";
CM_ SG_ 868 VCUChrgnModSts "Charging Mode Status";
CM_ SG_ 868 VCUDrvMotFltWarn "当驱动电机发生故障时 仪表点亮驱动电机故障灯";
CM_ SG_ 868 VCUDrvMotOverHeatWarn "驱动电机过热报警";
CM_ SG_ 868 VCUDrvSysLimdWarn "VCU发送点亮跛行故障灯信号 仪表点灯";
CM_ SG_ 868 VCUGearChgFailInde "换挡失败提醒";
CM_ SG_ 868 VCUHvBattSysFltIndcr "动力电池故障报警灯 低级";
CM_ SG_ 868 VCUHvBattSysFltWarn "动力电池故障报警灯 严重";
CM_ SG_ 868 VCUHVExtPortConnectnTypInfo "HV External Port Connection Type Information 重新定义 原来叫chrgnPortConnectnStsInfo 重新map";
CM_ SG_ 868 VCUHvPwrSysCutOff "VCU发送动力系统切断故障telltale";
CM_ SG_ 868 VCUHVSysFltWarnSts "高压系统故障 分等级";
CM_ SG_ 868 VCULoSocWarngMsg "高压电池低电量报警
HV Battery low SOC warnning";
CM_ SG_ 868 VCUPrpsnPwrDrt "VCU发送动力性能降级故障 仪表进行文字显示和声音提醒";
CM_ SG_ 868 VCUThermRunawayErrAlrm "热失控报警";
CM_ SG_ 868 VCUVehSysFltWarn "VCU发送点亮整车系统故障灯信号 仪表点灯";
CM_ SG_ 1023 VidBlkId "Block ID for VID Signal sequence";
CM_ SG_ 1023 VidSignalPos1 "1st position in VID Signal - Block ID dependant";
CM_ SG_ 1023 VidSignalPos2 "2st position in VID Signal - Block ID dependant";
CM_ SG_ 1023 VidSignalPos3 "3st position in VID Signal - Block ID dependant";
CM_ SG_ 1023 VidSignalPos4 "4st position in VID Signal - Block ID dependant";
CM_ SG_ 1023 VidSignalPos5 "5st position in VID Signal - Block ID dependant";
CM_ SG_ 1023 VidSignalPos6 "6st position in VID Signal - Block ID dependant";
CM_ SG_ 1023 VidSignalPos7 "7st position in VID Signal - Block ID dependant";
CM_ SG_ 1023 VinVINBlkID "Block ID for VIN Signal sequence";
CM_ SG_ 1023 VinVINSignalPos1 "1st position in VIN Signal    Block ID dependant";
CM_ SG_ 1023 VinVINSignalPos2 "2nd position in VIN Signal   Block ID dependant";
CM_ SG_ 1023 VinVINSignalPos3 "3rd position in VIN Signal   Block ID dependant";
CM_ SG_ 1023 VinVINSignalPos4 "4th position in VIN Signal   Block ID dependant";
CM_ SG_ 1023 VinVINSignalPos5 "5th position in VIN Signal   Block ID dependant";
CM_ SG_ 1023 VinVINSignalPos6 "6th position in VIN Signal   Block ID dependant";
CM_ SG_ 1023 VinVINSignalPos7 "7th position in VIN Signal   Block ID dependant";
CM_ SG_ 135 VehCfgPrmBlkIDBytePosn1 "Block ID for specific Car Configuration parameter sequence";
CM_ SG_ 135 VehCfgPrmCCPBytePosn2 "1st position in specific CCP number sequence   Block ID dependant";
CM_ SG_ 135 VehCfgPrmCCPBytePosn3 "2nd position in specific CCP number sequence   Block ID dependant";
CM_ SG_ 135 VehCfgPrmCCPBytePosn4 "3rd position in specific CCP number sequence   Block ID dependant";
CM_ SG_ 135 VehCfgPrmCCPBytePosn5 "4th position in specific CCP number sequence   Block ID dependant";
CM_ SG_ 135 VehCfgPrmCCPBytePosn6 "5th position in specific CCP number sequence   Block ID dependant";
CM_ SG_ 135 VehCfgPrmCCPBytePosn7 "6th position in specific CCP number sequence   Block ID dependant";
CM_ SG_ 135 VehCfgPrmCCPBytePosn8 "7th position in specific CCP number sequence   Block ID dependant";
CM_ SG_ 212 CarModSts "CarMode状态信号";
CM_ SG_ 212 DrvActvSts "用户通过仪式感按键的驾驶启动状态";
CM_ SG_ 212 LockgCenLockTrigSrc "中控锁触发源";
CM_ SG_ 212 LockgDrvrDoorLockCmd "主驾门锁命令";
CM_ SG_ 212 PwrModSts "PowerMode Status";
CM_ SG_ 212 PwrModVld "PowerMode Validty";
CM_ SG_ 212 VCUAccrPedlFlg "油门踏板踩下标志位";
CM_ SG_ 212 VCUAccrPedlRat "加速油门踏板开度";
CM_ SG_ 212 VCUAccrPedlRatGrdt "加速油门踏板开度变化率";
CM_ SG_ 212 VCUAccrPedlRatVld "加速踏板有效性";
CM_ SG_ 212 VCUActGearLvr "Actual gear level 车辆实际档位
P R N D挡位";
CM_ SG_ 212 VCUActGearLvrVld "车辆实际档位有效位";
CM_ SG_ 212 VCUAlwParkRels "是否允许整车出P挡";
CM_ SG_ 212 VCUDrvOffFcnLim "VCU send to BCS to identify whether vehcile can drive off or not as powertrain has fault and power limited.
VCU发送给BCS系统,用于判断整车动力系统是否存在故障动力受限不能起步的判断";
CM_ SG_ 212 VCUFrntDesTqWoIntv "前轴未干预需求扭矩";
CM_ SG_ 212 VCUFrntDesTqWoIntvVld "前轴未干预需求扭矩有效性";
CM_ SG_ 212 VCUFrntEmTqRdy "The Front Motor  can be ready to response chassis torque request.
前电机可以响应扭矩请求.";
CM_ SG_ 212 VCUFrntMotActSpd "前电机实际转速";
CM_ SG_ 212 VCUFrntMotActSpdVld "前电机实际转速有效位";
CM_ SG_ 212 VCUFrntMotActTq "前电机实际扭矩 明确为轴端扭矩 非电机端扭矩";
CM_ SG_ 212 VCUFrntMotActTqVld "前电机实际扭矩有效位";
CM_ SG_ 212 VCUFrntMotWhlTqReq "Front motor torque request";
CM_ SG_ 212 VCUFrntMotWhlTqReqVld "Front motor torque request Valid";
CM_ SG_ 212 VCUFrntWhlTqMaxAvl "前轮最大可用扭矩";
CM_ SG_ 212 VCUFrntWhlTqMaxAvlVld "前轮最大可用扭矩有效位";
CM_ SG_ 212 VCUFrntWhlTqMinAvl "前轮最小可用扭矩";
CM_ SG_ 212 VCUFrntWhlTqMinAvlVld "前轮最小可用扭矩有效位";
CM_ SG_ 212 VCUGearLvrAvail "Vehicle Gear Response is available for ADAS
给智驾反馈的挡位可用标志位";
CM_ SG_ 212 VCUHVSt "High voltage state
高压状态";
CM_ SG_ 212 VCULoSocLampReq "动力电池电量低";
CM_ SG_ 212 VCUPedlTqOvrdAdsFlg "纵向控制Override标志位";
CM_ SG_ 212 VCUPrkgBtnPsd "驾驶员按下P档";
CM_ SG_ 212 VCUPrkgBtnPsdVld "驾驶员长按P挡有效性";
CM_ SG_ 212 VCUPtRdyFlg "驾驶使能";
CM_ SG_ 212 VCUReDesTqWoIntv "后轴未干预需求扭矩";
CM_ SG_ 212 VCUReDesTqWoIntvVld "后轴未干预需求扭矩有效性";
CM_ SG_ 212 VCUReEmTqRdy "Rear EM is ready to response chassis Torque Request
后电机是否处于Ready状态";
CM_ SG_ 212 VCUReMotActSpd "后电机实际转速";
CM_ SG_ 212 VCUReMotActSpdVld "后电机实际转速有效位";
CM_ SG_ 212 VCUReMotActTq "后电机实际扭矩 明确为轴端扭矩 非电机端扭矩";
CM_ SG_ 212 VCUReMotActTqVld "后电机实际扭矩有效位";
CM_ SG_ 212 VCUReMotWhlTqReq "Rear motor torque request";
CM_ SG_ 212 VCUReMotWhlTqReqVld "Rear motor torque request Valid";
CM_ SG_ 212 VCUReWhlTqMaxAvl "后轮最大可用扭矩";
CM_ SG_ 212 VCUReWhlTqMaxAvlVld "后轮最大可用扭矩有效位";
CM_ SG_ 212 VCUReWhlTqMinAvl "后轮最小可用扭矩";
CM_ SG_ 212 VCUReWhlTqMinAvlVld "后轮最小可用扭矩有效位";
CM_ SG_ 212 VCURgnTqCorrnFac "Regeneration Torque Correction Factor";
CM_ SG_ 212 VCURLMotActTq "Rear Left Motor Actual Torque on wheelShaft
后左电机在轮端的实际输出扭矩";
CM_ SG_ 212 VCURLMotActTqVld "Rear Left Motor Actual Torque Valid
后左电机的实际扭矩有效位";
CM_ SG_ 212 VCURLMotWhlTqReq "Rear Left Motor Request Torque on WheelShaft;后左电机的轮端请求扭矩";
CM_ SG_ 212 VCURLMotWhlTqReqVld "Rear Left Motor Request Torque Valid;后左电机的请求扭矩有效位";
CM_ SG_ 212 VCURRMotActTq "Rear Right Motor Actual Torque on wheelShaft
后右电机在轮端上输出的实际扭矩";
CM_ SG_ 212 VCURRMotActTqVld "Rear right Motor Actual Torque Valid
后右电机实际扭矩的有效位";
CM_ SG_ 212 VCURRMotWhlTqReq "Rear right Motor request Torque on wheelshaft
后右电机的轮端请求扭矩";
CM_ SG_ 212 VCURRMotWhlTqReqVld "Rear Right Motor Reqeust Torque Valid;
后右电机的请求扭矩有效位";
CM_ SG_ 212 VCUShifterMoveFlg "驾驶员拨动了换挡杆的标志位";
CM_ SG_ 212 VCUStsModCst "energy recuperation end mode.
能量回收状态模式";
CM_ SG_ 212 VCUTarGearLvr "目标档位  P R N D挡位";
CM_ SG_ 212 VCUTarGearLvrVld "目标档位有效位";
CM_ SG_ 212 VCUVehMaxFltLvl "VCU Max Fault  Level
VCU最大故障等级";
CM_ SG_ 212 VCUVirtAccrPedl "虚拟油门开度 当前模式的pedal map反算";
CM_ SG_ 212 VCUVirtAccrPedlVld "虚拟油门开度有效位";
CM_ SG_ 212 VCUWhlTqMaxAvl "Vehicle Total Axle Max ability of Wheel Torque.
整车前后轴总的最大可用扭矩";
CM_ SG_ 212 VCUWhlTqMaxAvlVld "The validation of Vehicle total axle max ability of Wheel Torque.
整车前后轴总的可用回收扭矩的有效位";
CM_ SG_ 212 WiprSpdModSts "雨刮速度状态反馈";
CM_ SG_ 212 WipSpdReqHi "雨刮速度为高速档位
High speed wiping request";
CM_ SG_ 212 WipSpdReqLo "雨刮速度为低速档位
Low speed wiping request";
CM_ SG_ 228 VDMLgtWhlSpdFL "VDM longitudinal wheel speed front left
左前轮纵向速度";
CM_ SG_ 228 VDMLgtWhlSpdFR "VDM longitudinal wheel speed front right
右前轮纵向速度";
CM_ SG_ 228 VDMLgtWhlSpdRL "VDM longitudinal wheel speed real left
左后轮纵向速度";
CM_ SG_ 228 VDMLgtWhlSpdRR "VDM longitudinal wheel speed rear right
右后轮纵向速度";
CM_ SG_ 228 VehBodySideSlipAng "vehicle body side slip angle";
CM_ SG_ 228 VehLatSpdEstd "lateral vehicle speed estemsted
横向车速";
CM_ SG_ 228 VehLatSpdEstdVld "vehicle lateral speed estimated valid
横向车速有效性";
CM_ SG_ 228 VehLgtSpdEstd "longitudinal vehicle speed estemsted
纵向车速";
CM_ SG_ 228 VehLgtSpdEstdVld "Vehicle longitudinal speed estimated valid
纵向车速有效性";
CM_ SG_ 389 AdasSwt "一键智驾开关";
CM_ SG_ 389 AdasSwtSigGrpLinErr "AdasSwtSigGrp LIN communication Error";
CM_ SG_ 389 LeKnobCounter "方向盘左滚轮滚动Counter值";
CM_ SG_ 389 LeKnobRotDir "方向盘左侧滚轮滚动方向
0x0 Idle
0x1 Up
0x2 Down";
CM_ SG_ 389 LeMFctActSgCe "方向盘面板左侧开关滚轮松压状态";
CM_ SG_ 389 LeMFctActSgLe "方向盘面板左侧开关区左侧按键状态";
CM_ SG_ 389 LeMFctActSgRi "方向盘面板左侧开关区右侧按键状态";
CM_ SG_ 389 SwsLinComFltSts "SWS LIN node communication fault status.";
CM_ SG_ 520 BattSoh "Battery State of health
电池SOH";
CM_ SG_ 520 BMDMAcvDcnMosSt "BMDM active disconnect Mosfet State
BMDM主动断电Mos状态";
CM_ SG_ 520 HvBattSoCDisp "HV battery State Of Energy for HMI Display / 高压电池剩余可用能量百分比状态信息用于HMI人机交互显示";
CM_ SG_ 520 RlsLinComFltSts "Rls LIN node communication fault status.";
CM_ SG_ 1400 VCCDADDCANActiveWakeup "Active Wakeup Bit";
CM_ SG_ 1400 VCCDADDCANNodeAddress "Node source address";
CM_ SG_ 1400 VCCDADDCANRepeatMsgReq "Repeat Message Request Bit";
CM_ SG_ 1400 VCCDADDCANRepeatMsgSt "Repeat Message State indication";
BA_DEF_ BO_ "CANFD_BRS" ENUM "0","1";
BA_DEF_ BO_ "GenMsgCycleTime" INT 0 30000; //
BA_DEF_ BO_ "GenMsgCycleTimeFast" INT 0 30000; //
BA_DEF_ BO_ "GenMsgDelayTime" INT 0 100000; //
BA_DEF_ BO_ "GenMsgNrOfRepetition" INT 0 100000;
BA_DEF_ BO_ "GenMsgSendType" ENUM "cyclic","spontaneous","cyclicIfActive","spontaneousWithDelay","cyclicAndSpontaneous","cyclicAndSpontaneousWithDelay","IfActive","NoMsgSendType"; // [us]
BA_DEF_ BO_ "GenMsgStartDelayTime" INT 0 100000; //
BA_DEF_ BO_ "NmAsrBaseAddress" HEX 0 536870911; //
BA_DEF_ BO_ "VFrameFormat" ENUM "StandardCAN","ExtendedCAN","reserved","J1939PG","reserved","reserved","reserved","reserved","reserved","reserved","reserved","reserved","reserved","reserved","StandardCAN_FD","ExtendedCAN_FD";
BA_DEF_ SG_ "GenSigSendType" ENUM "Cyclic","OnWrite","OnWriteWithRepetition","OnChange","OnChangeWithRepetition","IfActive","IfActiveWithRepetition","NoSigSendType";
BA_DEF_ SG_ "GenSigStartValue" FLOAT -1.7976931348623157E308 18446744073709551615;
BA_DEF_DEF_ "CANFD_BRS" "1";
BA_DEF_DEF_ "GenMsgCycleTime" 0;
BA_DEF_DEF_ "GenMsgCycleTimeFast" 0;
BA_DEF_DEF_ "GenMsgDelayTime" 0;
BA_DEF_DEF_ "GenMsgNrOfRepetition" 0;
BA_DEF_DEF_ "GenSigStartValue" 0;
BA_DEF_DEF_ "GenMsgStartDelayTime" 0;
BA_DEF_DEF_ "NmAsrBaseAddress" 1280;
BA_DEF_DEF_ "VFrameFormat" "J1939PG";
BA_DEF_DEF_ "GenSigSendType" "Cyclic";
// ECU: ADD
// Frame: ACU_ADASCANFD_0x1A9
BA_ "GenMsgCycleTime" BO_ 425 20.000;
BA_ "GenMsgSendType" BO_ 425 0;
BA_ "VFrameFormat" BO_ 425 14;
// Frame: ACU_ADASCANFD_0x1AA
BA_ "GenMsgCycleTime" BO_ 426 20.000;
BA_ "GenMsgSendType" BO_ 426 0;
BA_ "VFrameFormat" BO_ 426 14;
// Frame: ACU_ADASCANFD_0x350
BA_ "GenMsgCycleTime" BO_ 848 200.000;
BA_ "GenMsgSendType" BO_ 848 0;
BA_ "VFrameFormat" BO_ 848 14;
// Frame: ACU_ADASCANFD_0x351
BA_ "GenMsgCycleTime" BO_ 849 200.000;
BA_ "GenMsgCycleTimeFast" BO_ 849 20.000;
BA_ "GenMsgNrOfRepetition" BO_ 849 20;
BA_ "GenMsgSendType" BO_ 849 4;
BA_ "VFrameFormat" BO_ 849 14;
// Frame: ADDAdasCanfdNMFrb
BA_ "GenMsgDelayTime" BO_ 1327 20.000;
BA_ "GenMsgSendType" BO_ 1327 1;
BA_ "VFrameFormat" BO_ 1327 0;
// Frame: BLEM_ADASCANFD_0x1BC
BA_ "GenMsgCycleTime" BO_ 444 20.000;
BA_ "GenMsgSendType" BO_ 444 0;
BA_ "VFrameFormat" BO_ 444 14;
// Frame: BLEM_ADASCANFD_0x291
BA_ "GenMsgCycleTime" BO_ 657 50.000;
BA_ "GenMsgSendType" BO_ 657 0;
BA_ "VFrameFormat" BO_ 657 14;
// Frame: BLEM_ADASCANFD_0x297
BA_ "GenMsgDelayTime" BO_ 663 5.000;
BA_ "GenMsgSendType" BO_ 663 1;
BA_ "VFrameFormat" BO_ 663 14;
// Frame: BLEM_ADASCANFD_0x299
BA_ "GenMsgCycleTime" BO_ 665 50.000;
BA_ "GenMsgSendType" BO_ 665 0;
BA_ "VFrameFormat" BO_ 665 14;
// Frame: BLEM_ADASCANFD_0x331
BA_ "GenMsgCycleTime" BO_ 817 50.000;
BA_ "GenMsgSendType" BO_ 817 0;
BA_ "VFrameFormat" BO_ 817 14;
// Frame: BLEM_ADASCANFD_0x339
BA_ "GenMsgDelayTime" BO_ 825 5.000;
BA_ "GenMsgSendType" BO_ 825 1;
BA_ "VFrameFormat" BO_ 825 14;
// Frame: BLEM_ADASCANFD_0x33A
BA_ "GenMsgCycleTime" BO_ 826 50.000;
BA_ "GenMsgSendType" BO_ 826 0;
BA_ "VFrameFormat" BO_ 826 14;
// Frame: BMDM_ADASCANFD_0x243
BA_ "GenMsgCycleTime" BO_ 579 50.000;
BA_ "GenMsgSendType" BO_ 579 0;
BA_ "VFrameFormat" BO_ 579 14;
// Frame: DCD_ADASCANFD_0x225
BA_ "GenMsgCycleTime" BO_ 549 50.000;
BA_ "GenMsgSendType" BO_ 549 0;
BA_ "VFrameFormat" BO_ 549 14;
// Frame: DCD_ADASCANFD_0x2D0
BA_ "GenMsgCycleTime" BO_ 720 100.000;
BA_ "GenMsgSendType" BO_ 720 0;
BA_ "VFrameFormat" BO_ 720 14;
// Frame: DCD_ADASCANFD_0x341
BA_ "GenMsgCycleTime" BO_ 833 200.000;
BA_ "GenMsgSendType" BO_ 833 0;
BA_ "VFrameFormat" BO_ 833 14;
// Frame: DCD_ADASCANFD_0x345
BA_ "GenMsgCycleTime" BO_ 837 200.000;
BA_ "GenMsgSendType" BO_ 837 0;
BA_ "VFrameFormat" BO_ 837 14;
// Frame: DCD_ADASCANFD_0x392
BA_ "GenMsgCycleTime" BO_ 914 500.000;
BA_ "GenMsgSendType" BO_ 914 0;
BA_ "VFrameFormat" BO_ 914 14;
// Frame: DCD_ADASCANFD_0x3A4
BA_ "GenMsgCycleTime" BO_ 932 1000.000;
BA_ "GenMsgCycleTimeFast" BO_ 932 40.000;
BA_ "GenMsgNrOfRepetition" BO_ 932 3;
BA_ "GenMsgSendType" BO_ 932 4;
BA_ "VFrameFormat" BO_ 932 14;
// Frame: FZCU_ADASCANFD_0x310
BA_ "GenMsgCycleTime" BO_ 784 100.000;
BA_ "GenMsgSendType" BO_ 784 0;
BA_ "VFrameFormat" BO_ 784 14;
// Frame: LRR_ADASCANFD_0x18C
BA_ "GenMsgCycleTime" BO_ 396 50.000;
BA_ "GenMsgSendType" BO_ 396 0;
BA_ "VFrameFormat" BO_ 396 14;
// Frame: LZCU_ADASCANFD_0x1B2
BA_ "GenMsgCycleTime" BO_ 434 20.000;
BA_ "GenMsgSendType" BO_ 434 0;
BA_ "VFrameFormat" BO_ 434 14;
// Frame: LZCU_ADASCANFD_0x25F
BA_ "GenMsgCycleTime" BO_ 607 50.000;
BA_ "GenMsgSendType" BO_ 607 0;
BA_ "VFrameFormat" BO_ 607 14;
// Frame: LZCU_ADASCANFD_0x37C
BA_ "GenMsgCycleTime" BO_ 892 200.000;
BA_ "GenMsgSendType" BO_ 892 0;
BA_ "VFrameFormat" BO_ 892 14;
// Frame: RLSR_ADASCANFD_0x170
BA_ "GenMsgCycleTime" BO_ 368 20.000;
BA_ "GenMsgSendType" BO_ 368 0;
BA_ "VFrameFormat" BO_ 368 14;
// Frame: RLSR_ADASCANFD_0x187
BA_ "GenMsgCycleTime" BO_ 391 100.000;
BA_ "GenMsgSendType" BO_ 391 0;
BA_ "VFrameFormat" BO_ 391 14;
// Frame: RLSR_ADASCANFD_0x2BD
BA_ "GenMsgCycleTime" BO_ 701 50.000;
BA_ "GenMsgSendType" BO_ 701 0;
BA_ "VFrameFormat" BO_ 701 14;
// Frame: RRSR_ADASCANFD_0x17F
BA_ "GenMsgCycleTime" BO_ 383 20.000;
BA_ "GenMsgSendType" BO_ 383 0;
BA_ "VFrameFormat" BO_ 383 14;
// Frame: RRSR_ADASCANFD_0x188
BA_ "GenMsgCycleTime" BO_ 392 100.000;
BA_ "GenMsgSendType" BO_ 392 0;
BA_ "VFrameFormat" BO_ 392 14;
// Frame: RRSR_ADASCANFD_0x20B
BA_ "GenMsgCycleTime" BO_ 523 50.000;
BA_ "GenMsgSendType" BO_ 523 0;
BA_ "VFrameFormat" BO_ 523 14;
// Frame: RZCU_ADASCANFD_0x25A
BA_ "GenMsgCycleTime" BO_ 602 50.000;
BA_ "GenMsgSendType" BO_ 602 0;
BA_ "VFrameFormat" BO_ 602 14;
// Frame: RZCU_ADASCANFD_0x268
BA_ "GenMsgCycleTime" BO_ 616 50.000;
BA_ "GenMsgSendType" BO_ 616 0;
BA_ "VFrameFormat" BO_ 616 14;
// Frame: RZCU_ADASCANFD_0x300
BA_ "GenMsgCycleTime" BO_ 768 100.000;
BA_ "GenMsgSendType" BO_ 768 0;
BA_ "VFrameFormat" BO_ 768 14;
// Frame: RZCU_ADASCANFD_0x37D
BA_ "GenMsgCycleTime" BO_ 893 200.000;
BA_ "GenMsgSendType" BO_ 893 0;
BA_ "VFrameFormat" BO_ 893 14;
// Frame: SCU_ADASCANFD_0x156
BA_ "GenMsgCycleTime" BO_ 342 20.000;
BA_ "GenMsgSendType" BO_ 342 0;
BA_ "VFrameFormat" BO_ 342 14;
// Frame: SCU_ADASCANFD_0xB6
BA_ "GenMsgCycleTime" BO_ 182 10.000;
BA_ "GenMsgSendType" BO_ 182 0;
BA_ "VFrameFormat" BO_ 182 14;
// Frame: SWM_ADASCANFD_0x1A3
BA_ "GenMsgCycleTime" BO_ 419 20.000;
BA_ "GenMsgSendType" BO_ 419 0;
BA_ "VFrameFormat" BO_ 419 14;
// Frame: TBOX_ADASCANFD_0x107
BA_ "GenMsgCycleTime" BO_ 263 100.000;
BA_ "GenMsgSendType" BO_ 263 0;
BA_ "VFrameFormat" BO_ 263 14;
// Frame: TBOX_ADASCANFD_0x2E6
BA_ "GenMsgCycleTime" BO_ 742 100.000;
BA_ "GenMsgSendType" BO_ 742 0;
BA_ "VFrameFormat" BO_ 742 14;
// Frame: VCCDAdasCanfdNMFr
BA_ "GenMsgDelayTime" BO_ 1400 20.000;
BA_ "GenMsgSendType" BO_ 1400 1;
BA_ "VFrameFormat" BO_ 1400 0;
// Frame: VCCD_ADASCANFD_0x184
BA_ "GenMsgCycleTime" BO_ 388 20.000;
BA_ "GenMsgSendType" BO_ 388 0;
BA_ "VFrameFormat" BO_ 388 14;
// Frame: VCCD_ADASCANFD_0x202
BA_ "GenMsgCycleTime" BO_ 514 50.000;
BA_ "GenMsgSendType" BO_ 514 0;
BA_ "VFrameFormat" BO_ 514 14;
// Frame: VCCD_ADASCANFD_0x211
BA_ "GenMsgDelayTime" BO_ 529 2.000;
BA_ "GenMsgSendType" BO_ 529 1;
BA_ "VFrameFormat" BO_ 529 14;
// Frame: VCCD_ADASCANFD_0x2B1
BA_ "GenMsgCycleTime" BO_ 689 100.000;
BA_ "GenMsgSendType" BO_ 689 0;
BA_ "VFrameFormat" BO_ 689 14;
// Frame: VCCD_ADASCANFD_0x364
BA_ "GenMsgCycleTime" BO_ 868 100.000;
BA_ "GenMsgSendType" BO_ 868 0;
BA_ "VFrameFormat" BO_ 868 14;
// Frame: VCCD_ADASCANFD_0x3FF
BA_ "GenMsgCycleTime" BO_ 1023 1000.000;
BA_ "GenMsgSendType" BO_ 1023 0;
BA_ "VFrameFormat" BO_ 1023 14;
// Frame: VCCD_ADASCANFD_0x87
BA_ "GenMsgDelayTime" BO_ 135 2.000;
BA_ "GenMsgSendType" BO_ 135 1;
BA_ "VFrameFormat" BO_ 135 14;
// Frame: VCCD_ADASCANFD_0xD4
BA_ "GenMsgCycleTime" BO_ 212 10.000;
BA_ "GenMsgSendType" BO_ 212 0;
BA_ "VFrameFormat" BO_ 212 14;
// Frame: VCCD_ADASCANFD_0xE4
BA_ "GenMsgCycleTime" BO_ 228 10.000;
BA_ "GenMsgSendType" BO_ 228 0;
BA_ "VFrameFormat" BO_ 228 14;
// Frame: VCCD_ADASCANFD_RT_0x185
BA_ "GenMsgCycleTime" BO_ 389 20.000;
BA_ "GenMsgSendType" BO_ 389 0;
BA_ "VFrameFormat" BO_ 389 14;
// Frame: VCCD_ADASCANFD_RT_0x208
BA_ "GenMsgCycleTime" BO_ 520 50.000;
BA_ "GenMsgSendType" BO_ 520 0;
BA_ "VFrameFormat" BO_ 520 14;
BA_ "GenSigSendType" SG_ 1327 ADDCANActiveWakeup1 1;
BA_ "GenSigSendType" SG_ 1327 ADDCANNodeAddress1 1;
BA_ "GenSigSendType" SG_ 1327 ADDCANRepeatMsgReq1 1;
BA_ "GenSigSendType" SG_ 1327 ADDCANRepeatMsgSt1 1;
BA_ "GenSigSendType" SG_ 932 ADSAEBFCWSwtSet 1;
BA_ "GenSigSendType" SG_ 932 ADSAESESSSwtSet 1;
BA_ "GenSigSendType" SG_ 932 ADSAPPOpenReq 1;
BA_ "GenSigSendType" SG_ 932 ADSBSDLCASwtSet 1;
BA_ "GenSigSendType" SG_ 932 ADSDOWSwtSet 1;
BA_ "GenSigSendType" SG_ 932 ADSPMAEBSwtSet 1;
BA_ "GenSigSendType" SG_ 932 ADSRCWSwtSet 1;
BA_ "GenSigSendType" SG_ 932 ADSTLASwtSet 1;
BA_ "GenSigSendType" SG_ 932 ADSVcCtrlSwtSet 1;
BA_ "GenSigSendType" SG_ 932 APASwtSet 1;
BA_ "GenSigSendType" SG_ 932 AVPSwtSet 1;
BA_ "GenSigSendType" SG_ 825 BLEM2ADDForRPA00 1;
BA_ "GenSigSendType" SG_ 825 BLEM2ADDForRPA00FV 1;
BA_ "GenSigSendType" SG_ 825 BLEM2ADDForRPA00MAC 1;
BA_ "GenSigSendType" SG_ 825 BLEM2ADDForRPA01 1;
BA_ "GenSigSendType" SG_ 825 BLEM2ADDForRPA02 1;
BA_ "GenSigSendType" SG_ 825 BLEM2ADDForRPA03 1;
BA_ "GenSigStartValue" SG_ 579 BattSocRaw 800;
BA_ "GenSigStartValue" SG_ 520 BattSoh 900;
BA_ "GenSigStartValue" SG_ 579 BattURaw 13200;
BA_ "GenSigStartValue" SG_ 342 CurDampgCtrlMod 1;
BA_ "GenSigSendType" SG_ 932 DCD2RDParkinChoseButton 1;
BA_ "GenSigSendType" SG_ 932 DCDACCInitSpdSwtSet 1;
BA_ "GenSigSendType" SG_ 932 DCDADSMAISwtSet 1;
BA_ "GenSigSendType" SG_ 932 DCDADSRCTABSwtSet 1;
BA_ "GenSigSendType" SG_ 932 DCDADSVcCtrlDstSet 1;
BA_ "GenSigSendType" SG_ 932 DCDADSVcCtrlSpdSet 1;
BA_ "GenSigSendType" SG_ 932 DCDAPAButton 1;
BA_ "GenSigSendType" SG_ 932 DCDAPAPIPOReq 1;
BA_ "GenSigSendType" SG_ 932 DCDAPAParkOutButton 1;
BA_ "GenSigSendType" SG_ 932 DCDAPAParkOutDireSelect 1;
BA_ "GenSigSendType" SG_ 932 DCDAPAParkSlotSelect 1;
BA_ "GenSigSendType" SG_ 932 DCDAPAQuitReq 1;
BA_ "GenSigSendType" SG_ 932 DCDAPAVcCtl 1;
BA_ "GenSigSendType" SG_ 932 DCDAdsAutoTurnLiSwtSet 1;
BA_ "GenSigSendType" SG_ 932 DCDAdsIntelgntSpdSwtSet 1;
BA_ "GenSigSendType" SG_ 932 DCDAdsModSwtSet 1;
BA_ "GenSigSendType" SG_ 932 DCDAdsNOAOddSwtSet 1;
BA_ "GenSigSendType" SG_ 932 DCDAdsTrfcLiCtrlSwtSet 1;
BA_ "GenSigSendType" SG_ 932 DCDAdsVehDeturSwtSet 1;
BA_ "GenSigSendType" SG_ 932 DCDAudModSwtSet 1;
BA_ "GenSigSendType" SG_ 932 DCDAutoVehCustExperImprvProgSwt 1;
BA_ "GenSigSendType" SG_ 932 DCDAutoVehSrvAuthntSwt 1;
BA_ "GenSigSendType" SG_ 932 DCDBackMapDfltParkSlotReq 1;
BA_ "GenSigSendType" SG_ 932 DCDFxdSpdModValSwtSet 1;
BA_ "GenSigSendType" SG_ 932 DCDHPPBckGrLearSwtSet 1;
BA_ "GenSigSendType" SG_ 932 DCDHPPBckGrPathAutDoLoSet 1;
BA_ "GenSigSendType" SG_ 932 DCDHPPChoseSaveRoute 1;
BA_ "GenSigSendType" SG_ 932 DCDHPPLnVcReq 1;
BA_ "GenSigSendType" SG_ 932 DCDHPPLrnReq 1;
BA_ "GenSigSendType" SG_ 932 DCDHPPParkAlTheWay 1;
BA_ "GenSigSendType" SG_ 932 DCDHPPParkingButton 1;
BA_ "GenSigSendType" SG_ 932 DCDHPPPrkReq 1;
BA_ "GenSigSendType" SG_ 932 DCDLVPwrSwtSet 1;
BA_ "GenSigSendType" SG_ 932 DCDLdwLdpWarnTypSwtSet 1;
BA_ "GenSigSendType" SG_ 932 DCDParkAudModSwtSet 1;
BA_ "GenSigSendType" SG_ 932 DCDParkSpdSwtSet 1;
BA_ "GenSigSendType" SG_ 932 DCDPcntgeSpdModValSwtSet 1;
BA_ "GenSigSendType" SG_ 932 DCDPntCldSwtSet 1;
BA_ "GenSigStartValue" SG_ 833 DCDRoadFacSpdLim 255;
BA_ "GenSigSendType" SG_ 932 DCDTouchdSpdTyp 1;
BA_ "GenSigStartValue" SG_ 263 DateTiHr 24;
BA_ "GenSigStartValue" SG_ 263 DateTiMilsec 1000;
BA_ "GenSigStartValue" SG_ 263 DateTiMins 60;
BA_ "GenSigStartValue" SG_ 263 DateTiSec 60;
BA_ "GenSigSendType" SG_ 663 DltAllKeyFbFV 1;
BA_ "GenSigSendType" SG_ 663 DltAllKeyFbMAC 1;
BA_ "GenSigStartValue" SG_ 182 FrntLeCurHei 127;
BA_ "GenSigStartValue" SG_ 742 FrntLeTyrePVal 254;
BA_ "GenSigStartValue" SG_ 182 FrntRiCurHei 127;
BA_ "GenSigStartValue" SG_ 742 FrntRiTyrePVal 254;
BA_ "GenSigSendType" SG_ 932 HPPSwtSet 1;
BA_ "GenSigSendType" SG_ 932 HwNOASwtSet 1;
BA_ "GenSigSendType" SG_ 849 ImpctEvntSts 1;
BA_ "GenSigSendType" SG_ 849 ImpctEvntStsSigGrpChks 1;
BA_ "GenSigSendType" SG_ 849 ImpctEvntStsSigGrpCntr 1;
BA_ "GenSigStartValue" SG_ 426 LatAccr 25000;
BA_ "GenSigStartValue" SG_ 426 LatAccrSt 1;
BA_ "GenSigSendType" SG_ 932 LdwLdpSwtSet 1;
BA_ "GenSigSendType" SG_ 932 LidarCloudMode 1;
BA_ "GenSigStartValue" SG_ 425 LonAccr 25000;
BA_ "GenSigStartValue" SG_ 425 LonSnsrSt 1;
BA_ "GenSigStartValue" SG_ 342 LvlModAct 3;
BA_ "GenSigSendType" SG_ 1327 NMKeepAwkRsnADD 1;
BA_ "GenSigSendType" SG_ 1400 NMKeepAwkRsnVCCD 1;
BA_ "GenSigSendType" SG_ 932 NoaLcSwtSet 1;
BA_ "GenSigSendType" SG_ 932 PltSwtALCSet 1;
BA_ "GenSigSendType" SG_ 932 PltSwtSet 1;
BA_ "GenSigStartValue" SG_ 212 PwrModSts 1;
BA_ "GenSigStartValue" SG_ 368 RLSRRCTBTarDecelFrmSFC 200;
BA_ "GenSigStartValue" SG_ 383 RRSRRCTBTarDecelFrmSFC 200;
BA_ "GenSigStartValue" SG_ 182 ReLeCurHei 127;
BA_ "GenSigStartValue" SG_ 742 ReLeTyrePVal 254;
BA_ "GenSigStartValue" SG_ 182 ReRiCurHei 127;
BA_ "GenSigStartValue" SG_ 742 ReRiTyrePVal 254;
BA_ "GenSigSendType" SG_ 932 ScrnTouchdFuncChange 1;
BA_ "GenSigSendType" SG_ 932 ScrnTouchdLaneChange 1;
BA_ "GenSigSendType" SG_ 932 ScrnTouchdSpd 1;
BA_ "GenSigSendType" SG_ 932 ScrnTouchdSpdTyp 1;
BA_ "GenSigSendType" SG_ 529 SecOCMAC1 1;
BA_ "GenSigSendType" SG_ 529 SecOCMAC2 1;
BA_ "GenSigSendType" SG_ 529 SecOCMAC3 1;
BA_ "GenSigSendType" SG_ 529 SecOCResetCnt 1;
BA_ "GenSigSendType" SG_ 529 SecOCTripCnt 1;
BA_ "GenSigSendType" SG_ 663 SndBLEKeyPosnToRPA 1;
BA_ "GenSigSendType" SG_ 1327 UDB17ADD 1;
BA_ "GenSigSendType" SG_ 1400 UDB17VCCD 1;
BA_ "GenSigSendType" SG_ 1327 UDB18ADD 1;
BA_ "GenSigSendType" SG_ 1400 UDB18VCCD 1;
BA_ "GenSigSendType" SG_ 1327 UDB19ADD 1;
BA_ "GenSigSendType" SG_ 1400 UDB19VCCD 1;
BA_ "GenSigSendType" SG_ 1327 UDB20ADD 1;
BA_ "GenSigSendType" SG_ 1400 UDB20VCCD 1;
BA_ "GenSigSendType" SG_ 1327 UDB21ADD 1;
BA_ "GenSigSendType" SG_ 1400 UDB21VCCD 1;
BA_ "GenSigSendType" SG_ 1327 UDB22ADD 1;
BA_ "GenSigSendType" SG_ 1400 UDB22VCCD 1;
BA_ "GenSigSendType" SG_ 1327 UDB23ADD 1;
BA_ "GenSigSendType" SG_ 1400 UDB23VCCD 1;
BA_ "GenSigSendType" SG_ 1327 UDB24ADD 1;
BA_ "GenSigSendType" SG_ 1400 UDB24VCCD 1;
BA_ "GenSigSendType" SG_ 1327 UDB25ADD 1;
BA_ "GenSigSendType" SG_ 1400 UDB25VCCD 1;
BA_ "GenSigSendType" SG_ 1327 UDB26ADD 1;
BA_ "GenSigSendType" SG_ 1400 UDB26VCCD 1;
BA_ "GenSigSendType" SG_ 1327 UDB27ADD 1;
BA_ "GenSigSendType" SG_ 1400 UDB27VCCD 1;
BA_ "GenSigSendType" SG_ 1327 UDB28ADD 1;
BA_ "GenSigSendType" SG_ 1400 UDB28VCCD 1;
BA_ "GenSigSendType" SG_ 1327 UDB29ADD 1;
BA_ "GenSigSendType" SG_ 1400 UDB29VCCD 1;
BA_ "GenSigSendType" SG_ 1327 UDB30ADD 1;
BA_ "GenSigSendType" SG_ 1400 UDB30VCCD 1;
BA_ "GenSigSendType" SG_ 1327 UDB31ADD 1;
BA_ "GenSigSendType" SG_ 1400 UDB31VCCD 1;
BA_ "GenSigSendType" SG_ 1327 UDB32ADD 1;
BA_ "GenSigSendType" SG_ 1400 UDB32VCCD 1;
BA_ "GenSigSendType" SG_ 1327 UDB33ADD 1;
BA_ "GenSigSendType" SG_ 1400 UDB33VCCD 1;
BA_ "GenSigSendType" SG_ 1327 UDB34ADD 1;
BA_ "GenSigSendType" SG_ 1400 UDB34VCCD 1;
BA_ "GenSigSendType" SG_ 1327 UDB35ADD 1;
BA_ "GenSigSendType" SG_ 1400 UDB35VCCD 1;
BA_ "GenSigSendType" SG_ 1327 UDB36ADD 1;
BA_ "GenSigSendType" SG_ 1400 UDB36VCCD 1;
BA_ "GenSigSendType" SG_ 1327 UDB37ADD 1;
BA_ "GenSigSendType" SG_ 1400 UDB37VCCD 1;
BA_ "GenSigSendType" SG_ 1327 UDB38ADD 1;
BA_ "GenSigSendType" SG_ 1400 UDB38VCCD 1;
BA_ "GenSigSendType" SG_ 1327 UDB39ADD 1;
BA_ "GenSigSendType" SG_ 1400 UDB39VCCD 1;
BA_ "GenSigSendType" SG_ 1327 UDB40ADD 1;
BA_ "GenSigSendType" SG_ 1400 UDB40VCCD 1;
BA_ "GenSigSendType" SG_ 1327 UDB41ADD 1;
BA_ "GenSigSendType" SG_ 1400 UDB41VCCD 1;
BA_ "GenSigSendType" SG_ 1327 UDB42ADD 1;
BA_ "GenSigSendType" SG_ 1400 UDB42VCCD 1;
BA_ "GenSigSendType" SG_ 1327 UDB43ADD 1;
BA_ "GenSigSendType" SG_ 1400 UDB43VCCD 1;
BA_ "GenSigSendType" SG_ 1327 UDB44ADD 1;
BA_ "GenSigSendType" SG_ 1400 UDB44VCCD 1;
BA_ "GenSigSendType" SG_ 1327 UDB45ADD 1;
BA_ "GenSigSendType" SG_ 1400 UDB45VCCD 1;
BA_ "GenSigSendType" SG_ 1327 UDB46ADD 1;
BA_ "GenSigSendType" SG_ 1400 UDB46VCCD 1;
BA_ "GenSigSendType" SG_ 1327 UDB47ADD 1;
BA_ "GenSigSendType" SG_ 1400 UDB47VCCD 1;
BA_ "GenSigSendType" SG_ 1400 UDB49VCCD 1;
BA_ "GenSigSendType" SG_ 1400 UDB50VCCD 1;
BA_ "GenSigSendType" SG_ 1400 UDB51VCCD 1;
BA_ "GenSigSendType" SG_ 1400 UDB52VCCD 1;
BA_ "GenSigSendType" SG_ 1400 UDB53VCCD 1;
BA_ "GenSigSendType" SG_ 1400 VCCDADDCANActiveWakeup 1;
BA_ "GenSigSendType" SG_ 1400 VCCDADDCANNodeAddress 1;
BA_ "GenSigSendType" SG_ 1400 VCCDADDCANRepeatMsgReq 1;
BA_ "GenSigSendType" SG_ 1400 VCCDADDCANRepeatMsgSt 1;
BA_ "GenSigStartValue" SG_ 689 VCUEgyCnsInCurDrvCyc 20000;
BA_ "GenSigStartValue" SG_ 212 VCUFrntDesTqWoIntv 16383;
BA_ "GenSigStartValue" SG_ 212 VCUFrntEmTqRdy 1;
BA_ "GenSigStartValue" SG_ 212 VCUFrntMotActSpd 32767;
BA_ "GenSigStartValue" SG_ 212 VCUFrntMotActTq 16383;
BA_ "GenSigStartValue" SG_ 212 VCUFrntMotWhlTqReq 16383;
BA_ "GenSigStartValue" SG_ 212 VCUFrntWhlTqMinAvl 16383;
BA_ "GenSigStartValue" SG_ 388 VCULatSlopForDisp 450;
BA_ "GenSigStartValue" SG_ 388 VCULgtSlopForDisp 450;
BA_ "GenSigStartValue" SG_ 212 VCURLMotActTq 16383;
BA_ "GenSigStartValue" SG_ 212 VCURLMotWhlTqReq 16383;
BA_ "GenSigStartValue" SG_ 212 VCURRMotActTq 16383;
BA_ "GenSigStartValue" SG_ 212 VCURRMotWhlTqReq 16383;
BA_ "GenSigStartValue" SG_ 212 VCUReDesTqWoIntv 16383;
BA_ "GenSigStartValue" SG_ 212 VCUReEmTqRdy 1;
BA_ "GenSigStartValue" SG_ 212 VCUReMotActSpd 32767;
BA_ "GenSigStartValue" SG_ 212 VCUReMotActTq 16383;
BA_ "GenSigStartValue" SG_ 212 VCUReMotWhlTqReq 16383;
BA_ "GenSigStartValue" SG_ 212 VCUReWhlTqMinAvl 16383;
BA_ "GenSigSendType" SG_ 135 VehCfgPrmBlkIDBytePosn1 1;
BA_ "GenSigStartValue" SG_ 135 VehCfgPrmBlkIDBytePosn1 1;
BA_ "GenSigSendType" SG_ 135 VehCfgPrmCCPBytePosn2 1;
BA_ "GenSigSendType" SG_ 135 VehCfgPrmCCPBytePosn3 1;
BA_ "GenSigSendType" SG_ 135 VehCfgPrmCCPBytePosn4 1;
BA_ "GenSigSendType" SG_ 135 VehCfgPrmCCPBytePosn5 1;
BA_ "GenSigSendType" SG_ 135 VehCfgPrmCCPBytePosn6 1;
BA_ "GenSigSendType" SG_ 135 VehCfgPrmCCPBytePosn7 1;
BA_ "GenSigSendType" SG_ 135 VehCfgPrmCCPBytePosn8 1;
BA_ "GenSigSendType" SG_ 932 VehSpdDvtionModSwtSet 1;
BA_ "GenSigStartValue" SG_ 1023 VidBlkId 1;
BA_ "GenSigStartValue" SG_ 1023 VinVINBlkID 1;
BA_ "GenSigStartValue" SG_ 426 YawRate 30000;
BA_ "GenSigStartValue" SG_ 426 YawRateSnsrSt 1;
VAL_ 1327 ADDCANActiveWakeup1 0 "passive_wakeup" 1 "active_Wakeup";
VAL_ 1327 ADDCANRepeatMsgReq1 0 "Repeat_Message_State_not_requested" 1 "Repeat_Message_State_requested";
VAL_ 1327 ADDCANRepeatMsgSt1 0 "Not_in_Repeat_Message_State" 1 "In_Repeat_Message_State";
VAL_ 425 IMUCalSt 0 "IMU_not_Calibrated" 1 "IMU_Calibrated";
VAL_ 425 LonSnsrSt 0 "SIG_IN_SPEC" 1 "SIGNOTAVAIL" 2 "SIGFAIL" 3 "Reserved";
VAL_ 426 LatAccrSt 0 "SIG_IN_SPEC" 1 "SIGNOTAVAIL" 2 "SIGFAIL" 3 "Reserved";
VAL_ 426 YawRateSnsrSt 0 "SIG_IN_SPEC" 1 "SIGNOTAVAIL" 2 "SIGFAIL" 3 "Reserved";
VAL_ 848 ACUWarnLampSts 0 "LampOFF" 1 "LampON" 2 "Blinking" 3 "Reserved";
VAL_ 848 DrvrBucSts 0 "Buckled" 1 "Unbuckle" 2 "Reserved" 3 "Reserved";
VAL_ 848 PassBucSts 0 "Buckled" 1 "Unbuckle" 2 "Reserved" 3 "Reserved";
VAL_ 849 ImpctEvntSts 0 "Normal" 1 "Crash";
VAL_ 444 RCAvailable 0 "Not_Available" 1 "Available";
VAL_ 444 RPARemReq 0 "No_Request" 1 "RPA_Request" 2 "Reserved1" 3 "Reserved1";
VAL_ 663 SndBLEKeyPosnToRPA 0 "Initial_value" 1 "R0_distance" 2 "R1_distance" 3 "R2_distance" 4 "R3_distance" 5 "R4_distance";
VAL_ 579 BattSocRaw 800 "Invalid";
VAL_ 549 ADSELKSwtSet 0 "No_Command" 1 "Off" 2 "Middle" 3 "High";
VAL_ 549 ADSFltQuitReqFrmDCD 0 "default" 1 "Quit_Request" 2 "reserved_1" 3 "reserved_2";
VAL_ 549 DCDDisplayFailSts 0 "No_Failure" 1 "No_Comm_with_CIDM" 2 "CIDM_internal_display_error" 3 "DCD_actively_shutdown_display" 4 "CIDM_freeze_frame_detected" 5 "reserved_1" 6 "reserved_2" 7 "reserved_3";
VAL_ 549 DCDSteerWhlExtrMirrHUDAdjFlg 0 "Idle" 1 "SteeringWheelAdjustPupUp" 2 "ExtrMirrAdjustPupUp" 3 "HUDAdjustPupUp(Reserved)";
VAL_ 720 DCDDMSCameraFltSts 0 "No_fault" 1 "Fault";
VAL_ 720 DCDDMSdstrctnDetnSts 0 "OFF" 1 "On";
VAL_ 720 DCDDMSdstrctnSts 0 "No_distraction" 1 "Mild_distraction" 2 "Moderate_distraction" 3 "Sever_distraction";
VAL_ 720 DCDDMSFatgDetnSts 0 "OFF" 1 "On";
VAL_ 720 DCDDMSfatgSts 0 "No_fatigue" 1 "Mild_fatigue" 2 "Moderate_fatigue" 3 "sever_fatigue";
VAL_ 720 DCDDMSSysFltSts 0 "No_fault" 1 "Fault";
VAL_ 720 DCDDVRSrvReq 0 "No_request" 1 "Request";
VAL_ 720 DCDGameModSts 0 "OFF" 1 "On";
VAL_ 720 DCDPrivacyModeStatus 0 "default" 1 "PrivacyModeOFF" 2 "PrivacyModeON" 3 "reserved";
VAL_ 720 DCDsentryModReq 0 "No_request" 1 "Request";
VAL_ 720 DCDsentryModSts 0 "Switch_off" 1 "Switch_on" 2 "Standby1" 3 "Standby2" 4 "Alert" 5 "Alarm" 6 "SentryVideoSaving1" 7 "SentryVideoSaving2";
VAL_ 720 DCDTSASLIFSwtSts 0 "Default" 1 "OFF" 2 "vision_warning" 3 "vision_and_audio_warning";
VAL_ 720 SRMode 0 "default" 1 "normal" 2 "error";
VAL_ 833 ALCLrnSts 0 "not_learn" 1 "pass";
VAL_ 833 AVPLrnSts 0 "not_learn" 1 "pass";
VAL_ 833 DCDAdCode 0 "Unknown";
VAL_ 833 DCDCameraSpdLim 0 "NoLimit";
VAL_ 833 DCDNavSts 0 "NoNavigation" 1 "Navigating" 2 "Crusing" 3 "RoutePlanning";
VAL_ 833 DCDRoadClass 0 "Unknown" 1 "Freeway" 2 "NationalRoad" 3 "ProvinceRoad" 4 "CountyRoad" 5 "RuralRoad" 6 "InCountyRoad" 7 "CitySpeedWay" 8 "MainRoad" 9 "SecondaryRoad" 10 "CommonRoad" 11 "NonNaviRoad";
VAL_ 833 DCDRoadFacSpdLim 0 "NoLimit" 255 "Map_Not_Started";
VAL_ 833 DCDRoadType 0 "Unknown" 1 "DivisedLink" 2 "CrossLink" 3 "JCT" 4 "RoundCircle" 5 "ServiceRoad" 6 "SlipRoad" 7 "SideRoad" 8 "SlipJCT" 9 "ExitLink" 10 "EntranceLink" 11 "TurnRightLineA" 12 "TurnRightLineB" 13 "TurnLeftLineA" 14 "TurnLeftLineB" 15 "CommonLink" 16 "TurnLeftRightLine" 53 "ServiceJCTRoad" 56 "ServiceSlipRoad" 58 "ServiceSlipJCTRoad";
VAL_ 833 DCDTrfcSts 0 "Unknown" 1 "Open" 2 "Slow" 3 "Jam" 4 "Congested";
VAL_ 833 DCDTSASlifSpdDisp 0 "No_display" 511 "Canceled";
VAL_ 833 DstUnitDisp 0 "km" 1 "mi";
VAL_ 833 HPPLrnSts 0 "not_learn" 1 "pass";
VAL_ 833 NOACtyLrnSts 0 "not_learn" 1 "pass";
VAL_ 833 NOAHWLrnSts 0 "not_learn" 1 "pass";
VAL_ 833 PltLrnSts 0 "not_learn" 1 "pass";
VAL_ 833 VehInsSpdDispVld 0 "Valid" 1 "Invalid";
VAL_ 837 DCDAccountLogTyp 0 "Initial_Value" 1 "Login_account_manually" 2 "Login_account_via_FaceID" 3 "Login_account_via_KeyID_Android" 4 "Login_account_via_KeyID_MCU";
VAL_ 837 DCDAcctMod 0 "log_out" 1 "log_in";
VAL_ 837 DCDCloudSysnc 0 "CloudSysnc_Off" 1 "CloudSysnc_On";
VAL_ 837 DCDCurProID 0 "Default_Profile" 4294967295 "Common_Profile";
VAL_ 837 DCDGstMod 0 "Default" 1 "No_Guest_Mode" 2 "Guest_Mode";
VAL_ 837 DCDICVehCustExperImprvProgSts 0 "Default" 1 "OFF" 2 "ON" 3 "Reserved";
VAL_ 837 DCDICVehSrvAuthntSts 0 "Default" 1 "Unauthorized" 2 "Authorized" 3 "Reserved";
VAL_ 914 TotOdoAcrt 16777215 "Invaild";
VAL_ 914 TotOdoAcrtLvlM 4294967295 "Invaild";
VAL_ 914 TotOdoAcrtLvlMVld 0 "Valid" 1 "Invalid";
VAL_ 914 TotOdoAcrtVld 0 "Valid" 1 "Invalid";
VAL_ 932 ADSAEBFCWSwtSet 0 "No_Command" 1 "Off" 2 "early" 3 "middle" 4 "late";
VAL_ 932 ADSAESESSSwtSet 0 "No_Command" 1 "Off" 2 "On";
VAL_ 932 ADSAPPOpenReq 0 "No_Command" 1 "Request" 2 "Reserved" 3 "Reserved";
VAL_ 932 ADSBSDLCASwtSet 0 "No_command" 1 "Off" 2 "AudWarning" 3 "HptcWarning" 4 "LightWarning";
VAL_ 932 ADSDOWSwtSet 0 "No_Command" 1 "Off" 2 "Warning" 3 "Delay_open";
VAL_ 932 ADSPMAEBSwtSet 0 "No_Command" 1 "Off" 2 "On";
VAL_ 932 ADSRCWSwtSet 0 "No_Command" 1 "Off" 2 "On";
VAL_ 932 ADSTLASwtSet 0 "No_Command" 1 "Off" 2 "On";
VAL_ 932 ADSVcCtrlSwtSet 0 "No_command" 1 "Off" 2 "ON";
VAL_ 932 APASwtSet 0 "No_Command" 1 "Off" 2 "On";
VAL_ 932 AVPSwtSet 0 "No_Command" 1 "Off" 2 "On";
VAL_ 932 DCD2RDParkinChoseButton 0 "None" 1 "Chose_2rd_Park_in" 2 "Chose_No";
VAL_ 932 DCDACCInitSpdSwtSet 0 "No_command" 1 "Current_Veh_Spd" 2 "Current_Spd_Limit";
VAL_ 932 DCDAdsAutoTurnLiSwtSet 0 "NoCommand" 1 "Off" 2 "On";
VAL_ 932 DCDAdsIntelgntSpdSwtSet 0 "No_Command" 1 "Off" 2 "On";
VAL_ 932 DCDADSMAISwtSet 0 "No_Command" 1 "Off" 2 "On";
VAL_ 932 DCDAdsModSwtSet 0 "No_Command" 1 "ACC_Mode" 2 "LCC_Mode" 3 "NOA_Mode";
VAL_ 932 DCDAdsNOAOddSwtSet 0 "No_Command" 1 "Highway" 2 "Urban_road" 3 "Highway_and_Urban_road";
VAL_ 932 DCDADSRCTABSwtSet 0 "No_Command" 1 "OFF" 2 "Warning" 3 "warning_and_brake";
VAL_ 932 DCDAdsTrfcLiCtrlSwtSet 0 "No_Command" 1 "Off" 2 "On";
VAL_ 932 DCDADSVcCtrlDstSet 0 "No_Command" 1 "Up" 2 "Down" 3 "Reserved";
VAL_ 932 DCDADSVcCtrlSpdSet 0 "No_Command" 1 "Up" 2 "Down" 3 "Reserved";
VAL_ 932 DCDAdsVehDeturSwtSet 0 "Default" 1 "Off" 2 "On";
VAL_ 932 DCDAPAButton 0 "No_Request" 1 "Start_APA" 2 "Stop_APA(Reserved)";
VAL_ 932 DCDAPAParkOutButton 0 "No_Request" 1 "Start_ParkOut" 2 "Stop_ParkOut" 3 "Reserved";
VAL_ 932 DCDAPAParkOutDireSelect 0 "No_Park_Slot" 1 "Cross_FrontLeft_Out" 2 "Cross_FrontVertical_Out" 3 "Cross_FrontRight_Out" 4 "Parallel_FrontLeft_Out" 5 "Parallel_FrontRight_Out" 6 "Tilted_FrontLeft_Out" 7 "Tilted_FrontVertical_Out" 8 "Tilted_FrontRight_Out" 9 "Cross_RearLeft_Out" 10 "Cross_RearVertical_Out" 11 "Cross_RearRight_Out" 12 "Tilted_RearLeft_Out" 13 "Tilted_RearVertical_Out" 14 "Tilted_RearRight_Out" 15 "Reserved";
VAL_ 932 DCDAPAParkSlotSelect 0 "None" 1 "Left_ID1" 2 "Left_ID2" 3 "Left_ID3" 4 "Left_ID4" 5 "Left_ID5" 6 "Left_ID6" 7 "Left_ID7" 8 "Left_ID8" 9 "Right_ID1" 10 "Right_ID2" 11 "Right_ID3" 12 "Right_ID4" 13 "Right_ID5" 14 "Right_ID6" 15 "Right_ID7" 16 "Right_ID8";
VAL_ 932 DCDAPAPIPOReq 0 "None" 1 "APA_Req" 2 "APA_POC_Req(Reserved)";
VAL_ 932 DCDAPAQuitReq 0 "No_Req" 1 "Quit_Req";
VAL_ 932 DCDAPAVcCtl 0 "No_Command" 1 "Request_APA" 2 "Quit_APA" 3 "Request_APAParkOut" 4 "Quit_APAParkOut" 5 "Request_APAParkIn" 6 "Quit_APAParkIn" 7 "Reserved";
VAL_ 932 DCDAudModSwtSet 0 "No_Command" 1 "Off" 2 "Escort" 3 "Normal" 4 "Simple";
VAL_ 932 DCDAutoVehCustExperImprvProgSwt 0 "No_command" 1 "Off" 2 "On";
VAL_ 932 DCDAutoVehSrvAuthntSwt 0 "No_Command" 1 "revoke_authorization" 2 "authorize";
VAL_ 932 DCDBackMapDfltParkSlotReq 0 "NoCommand" 1 "UseBackMapDfltParkSlotRequest";
VAL_ 932 DCDFxdSpdModValSwtSet 0 "No_Command" 1 "level_-15" 2 "level_-14" 3 "level_-13" 4 "level_-12" 5 "level_-11" 6 "level_-10" 7 "level_-9" 8 "level_-8" 9 "level_-7" 10 "level_-6" 11 "level_-5" 12 "level_-4" 13 "level_-3" 14 "level_-2" 15 "level_-1" 16 "level_0" 17 "level_1" 18 "level_2" 19 "level_3" 20 "level_4" 21 "level_5" 22 "level_6" 23 "level_7" 24 "level_8" 25 "level_9" 26 "level_10" 27 "level_11" 28 "level_12" 29 "level_13" 30 "level_14" 31 "level_15";
VAL_ 932 DCDHPPBckGrLearSwtSet 0 "No_command" 1 "Off" 2 "ON";
VAL_ 932 DCDHPPBckGrPathAutDoLoSet 0 "No_command" 1 "Off" 2 "ON";
VAL_ 932 DCDHPPChoseSaveRoute 0 "No_Command" 1 "Save" 2 "NotSave";
VAL_ 932 DCDHPPLnVcReq 0 "No_Command" 1 "Request_Learn_HPP";
VAL_ 932 DCDHPPLrnReq 0 "NoDemand" 1 "HPP_Learn_Request" 2 "HPP_Learn_Continue_Request" 3 "HPP_Learn_Finish_Request" 4 "HPP_Learn_Cancel_Request";
VAL_ 932 DCDHPPParkAlTheWay 0 "NoCommand" 1 "HPPParkAlTheWayRequest" 2 "QuitHPPParkAlTheWayRequest";
VAL_ 932 DCDHPPParkingButton 0 "No_Command" 1 "HPP_StartParking_Request";
VAL_ 932 DCDHPPPrkReq 0 "NoDemand" 1 "HPP_Start_Request" 2 "HPP_Recover_Request" 3 "HPP_Quit_Request";
VAL_ 932 DCDLdwLdpWarnTypSwtSet 0 "No_Command" 1 "Audio" 2 "Haptic";
VAL_ 932 DCDLVPwrSwtSet 0 "No_command" 1 "Off" 2 "ON";
VAL_ 932 DCDParkAudModSwtSet 0 "No_Command" 1 "Off" 2 "Normal" 3 "Simple";
VAL_ 932 DCDParkSpdSwtSet 0 "No_Command" 1 "Standard" 2 "Fast" 3 "Reserved_1" 4 "Reserved_2" 5 "Reserved_3" 6 "Reserved_4";
VAL_ 932 DCDPcntgeSpdModValSwtSet 0 "No_Command" 1 "level_-10" 2 "level_-9" 3 "level_-8" 4 "level_-7" 5 "level_-6" 6 "level_-5" 7 "level_-4" 8 "level_-3" 9 "level_-2" 10 "level_-1" 11 "level_0" 12 "level_1" 13 "level_2" 14 "level_3" 15 "level_4" 16 "level_5" 17 "level_6" 18 "level_7" 19 "level_8" 20 "level_9" 21 "level_10";
VAL_ 932 DCDPntCldSwtSet 0 "No_Command" 1 "Off" 2 "On";
VAL_ 932 DCDTouchdSpdTyp 0 "No_command" 1 "Current_Veh_Spd_touched" 2 "Current_Spd_Limit_touched";
VAL_ 932 HPPSwtSet 0 "No_Command" 1 "Off" 2 "On";
VAL_ 932 HwNOASwtSet 0 "No_Command" 1 "Off" 2 "On";
VAL_ 932 LdwLdpSwtSet 0 "No_Command" 1 "OFF" 2 "Warning" 3 "Warning_Prevention";
VAL_ 932 LidarCloudMode 0 "default" 1 "open_succeed" 2 "open_failure" 3 "close_succeed" 4 "close_failure";
VAL_ 932 NoaLcSwtSet 0 "No_Command" 1 "Lane_change_recommended" 2 "Autonomous_lane_change";
VAL_ 932 PltSwtALCSet 0 "No_Command" 1 "Off" 2 "ALC";
VAL_ 932 PltSwtSet 0 "No_Command" 1 "Off" 2 "Pilot";
VAL_ 932 ScrnTouchdFuncChange 0 "default" 1 "NOA_to_Pilot" 2 "Pilot_to_NOA";
VAL_ 932 ScrnTouchdLaneChange 0 "default" 1 "LaneChangeCancel";
VAL_ 932 ScrnTouchdSpd 255 "invalid";
VAL_ 932 ScrnTouchdSpdTyp 0 "default" 1 "Current_Spd_Limit_touched" 2 "Current_Spd_Disp_touched";
VAL_ 932 VehSpdDvtionModSwtSet 0 "No_Command" 1 "fixed_speed_mode" 2 "percentage_speed_mode";
VAL_ 784 FLRLLoPwrSplySts 0 "Off" 1 "On";
VAL_ 784 IMULoPwrSplySts 0 "Off" 1 "On";
VAL_ 784 LRRLoPwrSplySts 0 "Off" 1 "On";
VAL_ 784 LSLLoPwrSplySts 0 "Off" 1 "On";
VAL_ 784 RSLLoPwrSplySts 0 "Off" 1 "On";
VAL_ 434 DoorDrvrPwrRelsMotDrvSts 0 "NoDrv" 1 "PwrRelsDrv" 2 "PwrRelsRstDrv" 3 "CrashUnlckDrv" 4 "Reserved";
VAL_ 607 AswmLinComFltSts 0 "No_Fault" 1 "Node_Miss";
VAL_ 607 HandOnDetnStsSigGrpLinErr 0 "NoErr" 1 "CounterErr" 2 "CRCErr" 3 "CounterErr_CRCErr";
VAL_ 607 HandsOnDetectionErrorStatus 0 "NoError" 1 "Error";
VAL_ 607 HandsOnDetectionStatus 0 "No_Detect" 1 "Detect";
VAL_ 607 StsOfBSDLampLe 0 "Off" 1 "On" 2 "Err" 3 "Resd";
VAL_ 892 DrvrOcupcySts 0 "Empty" 1 "Occupied" 2 "Invaild_STG" 3 "Invaild_STB_OL";
VAL_ 368 RLSRRCTBBrkReqFrmSFC 0 "no_request" 1 "request";
VAL_ 391 RLSRBSDLCAStsFrmSFC 0 "Off" 1 "Standby" 2 "Active" 3 "Failure";
VAL_ 391 RLSRBSDLCASwtFbFrmSFC 0 "default" 1 "unavailable" 2 "Off" 3 "AudWarning" 4 "HptcWarning";
VAL_ 391 RLSRBSDLCASwtUnavlRsnFrmSFC 0 "default" 1 "No_reason_req" 2 "not_P_gear" 3 "account_not_log_in" 4 "not_authorized" 5 "not_learned" 6 "privacy_mode" 7 "extreme_eco_mode" 8 "lowpower_mode" 9 "function_active" 10 "other_reasons" 11 "Error_Detected";
VAL_ 391 RLSRBSDLCAWarnReqFrmSFC 0 "nowarning" 1 "warninglevel1" 2 "warninglevel2" 3 "reserved";
VAL_ 391 RLSRDOWStsFrmSFC 0 "Off" 1 "Standby" 2 "Active" 3 "Failure";
VAL_ 391 RLSRDOWSwtFbFrmSFC 0 "default" 1 "Off" 2 "Warning" 3 "Delay_open" 4 "unavailable";
VAL_ 391 RLSRDOWSwtUnavlRsnFrmSFC 0 "default" 1 "No_reason_req" 2 "not_P_gear" 3 "account_not_log_in" 4 "not_authorized" 5 "not_learned" 6 "privacy_mode" 7 "extreme_eco_mode" 8 "lowpower_mode" 9 "function_active" 10 "other_reasons" 11 "Error_Detected";
VAL_ 391 RLSRDOWWarnReqFrFrmSFC 0 "nowarning" 1 "warninglevel1" 2 "warninglevel2" 3 "reserved";
VAL_ 391 RLSRDOWWarnReqReFrmSFC 0 "nowarning" 1 "warninglevel1" 2 "warninglevel2" 3 "reserved";
VAL_ 391 RLSRRCTABSwtFbFrmSFC 0 "default" 1 "unavailable" 2 "Off" 3 "Warning" 4 "Warning_Brake";
VAL_ 391 RLSRRCTABSwtUnavlRsnFrmSFC 0 "default" 1 "No_reason_req" 2 "not_P_gear" 3 "account_not_log_in" 4 "not_authorized" 5 "not_learned" 6 "privacy_mode" 7 "extreme_eco_mode" 8 "lowpower_mode" 9 "function_active" 10 "other_reasons" 11 "Error_Detected";
VAL_ 391 RLSRRCTAStsFrmSFC 0 "Off" 1 "Standby" 2 "Active" 3 "Failure";
VAL_ 391 RLSRRCTAWarnReqFrmSFC 0 "no_warning" 1 "warning_level_1" 2 "warning_level_2";
VAL_ 391 RLSRRCTBStsFrmSFC 0 "Off" 1 "Standby" 2 "Active" 3 "Failure";
VAL_ 391 RLSRRCTBWarnReqFrmSFC 0 "nowarning" 1 "warninglevel1" 2 "warninglevel2" 3 "reserved";
VAL_ 391 RLSRRCWStsFrmSFC 0 "Off" 1 "Standby" 2 "Active" 3 "Failure";
VAL_ 391 RLSRRCWSwtFbFrmSFC 0 "default" 1 "Off" 2 "ON" 3 "unavailable";
VAL_ 391 RLSRRCWSwtUnavlRsnFrmSFC 0 "default" 1 "No_reason_req" 2 "not_P_gear" 3 "account_not_log_in" 4 "not_authorized" 5 "not_learned" 6 "privacy_mode" 7 "extreme_eco_mode" 8 "lowpower_mode" 9 "function_active" 10 "other_reasons" 11 "Error_Detected";
VAL_ 391 RLSRRCWWarnReqFrmSFC 0 "nowarning" 1 "warninglevel1" 2 "warninglevel2";
VAL_ 383 RRSRRCTBBrkReqFrmSFC 0 "no_request" 1 "request";
VAL_ 392 RRSRBSDLCAStsFrmSFC 0 "Off" 1 "Standby" 2 "Active" 3 "Failure";
VAL_ 392 RRSRBSDLCASwtFbFrmSFC 0 "default" 1 "unavailable" 2 "Off" 3 "AudWarning" 4 "HptcWarning";
VAL_ 392 RRSRBSDLCASwtUnavlRsnFrmSFC 0 "default" 1 "No_reason_req" 2 "not_P_gear" 3 "account_not_log_in" 4 "not_authorized" 5 "not_learned" 6 "privacy_mode" 7 "extreme_eco_mode" 8 "lowpower_mode" 9 "function_active" 10 "other_reasons" 11 "Error_Detected";
VAL_ 392 RRSRBSDLCAWarnReqFrmSFC 0 "nowarning" 1 "warninglevel1" 2 "warninglevel2" 3 "reserved";
VAL_ 392 RRSRDOWStsFrmSFC 0 "Off" 1 "Standby" 2 "Active" 3 "Failure";
VAL_ 392 RRSRDOWSwtFbFrmSFC 0 "default" 1 "Off" 2 "Warning" 3 "Delay_open" 4 "unavailable";
VAL_ 392 RRSRDOWSwtUnavlRsnFrmSFC 0 "default" 1 "No_reason_req" 2 "not_P_gear" 3 "account_not_log_in" 4 "not_authorized" 5 "not_learned" 6 "privacy_mode" 7 "extreme_eco_mode" 8 "lowpower_mode" 9 "function_active" 10 "other_reasons" 11 "Error_Detected";
VAL_ 392 RRSRDOWWarnReqFrFrmSFC 0 "nowarning" 1 "warninglevel1" 2 "warninglevel2" 3 "reserved";
VAL_ 392 RRSRDOWWarnReqReFrmSFC 0 "nowarning" 1 "warninglevel1" 2 "warninglevel2" 3 "reserved";
VAL_ 392 RRSRRCTABSwtFbFrmSFC 0 "default" 1 "unavailable" 2 "Off" 3 "Warning" 4 "Warning_Brake";
VAL_ 392 RRSRRCTABSwtUnavlRsnFrmSFC 0 "default" 1 "No_reason_req" 2 "not_P_gear" 3 "account_not_log_in" 4 "not_authorized" 5 "not_learned" 6 "privacy_mode" 7 "extreme_eco_mode" 8 "lowpower_mode" 9 "function_active" 10 "other_reasons" 11 "Error_Detected";
VAL_ 392 RRSRRCTAStsFrmSFC 0 "Off" 1 "Standby" 2 "Active" 3 "Failure";
VAL_ 392 RRSRRCTAWarnReqFrmSFC 0 "no_warning" 1 "warning_level_1" 2 "warning_level_2";
VAL_ 392 RRSRRCTBStsFrmSFC 0 "Off" 1 "Standby" 2 "Active" 3 "Failure";
VAL_ 392 RRSRRCTBWarnReqFrmSFC 0 "nowarning" 1 "warninglevel1" 2 "warninglevel2" 3 "reserved";
VAL_ 392 RRSRRCWStsFrmSFC 0 "Off" 1 "Standby" 2 "Active" 3 "Failure";
VAL_ 392 RRSRRCWSwtFbFrmSFC 0 "default" 1 "Off" 2 "ON" 3 "unavailable";
VAL_ 392 RRSRRCWSwtUnavlRsnFrmSFC 0 "default" 1 "No_reason_req" 2 "not_P_gear" 3 "account_not_log_in" 4 "not_authorized" 5 "not_learned" 6 "privacy_mode" 7 "extreme_eco_mode" 8 "lowpower_mode" 9 "function_active" 10 "other_reasons" 11 "Error_Detected";
VAL_ 392 RRSRRCWWarnReqFrmSFC 0 "nowarning" 1 "warninglevel1" 2 "warninglevel2";
VAL_ 602 RlsRainFallAmnt 0 "0mm_24h" 1 "0_10mm_24h" 2 "10_15mm_24h" 3 "15_25mm_24h" 4 "25_35mm_24h" 5 "35_50mm_24h" 6 "50_70mm_24h" 7 "70_100mm_24h" 8 "100_mm_24h";
VAL_ 602 RlsRainFallSts 0 "No_rain" 1 "ligt_rain" 2 "moderate_rain" 3 "heavy_rain" 15 "Invalid";
VAL_ 602 RlsRainSnsrFlt 0 "No_fault" 1 "Fault";
VAL_ 616 RlsAutWinWipgSpdCmd 0 "Switch_wiper_off" 1 "40_times_per_minute" 2 "45_times_per_minute" 3 "48_times_per_minute" 4 "51_times_per_minute" 5 "54_times_per_minute" 6 "57_times_per_minute" 7 "60_times_per_minute";
VAL_ 616 RlsFwdLiSnsrVal 32767 "Invalid";
VAL_ 616 RlsFwdLiSnsrValUnit 0 "1lux" 1 "10lux" 2 "100lux" 3 "1000lux";
VAL_ 616 RlsHudSnsrVal 32767 "Invalid";
VAL_ 616 RlsHudSnsrValUnit 0 "1lux" 1 "10lux" 2 "100lux" 3 "1000lux";
VAL_ 616 RlsLiSigGrpLinErr 0 "NoErr" 1 "CounterErr" 2 "CRCErr" 3 "CounterErr_CRCErr";
VAL_ 616 RlsLiSnsrFwdFlt 0 "No_Fault" 1 "Fault";
VAL_ 616 RlsLiSnsrIRFlt 0 "No_Fault" 1 "Fault";
VAL_ 616 RlsLiSnsrTopFlt 0 "No_Fault" 1 "Fault";
VAL_ 616 RlsLiSwtReq 0 "Switch_ligt_off" 1 "Switch_ligt_on" 2 "Reserved" 3 "Invalid";
VAL_ 616 RlsOutdBriSts 0 "Day" 1 "Night" 2 "Tunnel" 3 "Darkstart" 4 "Invalid";
VAL_ 616 RlsSts 0 "Rls_normal" 1 "Rls_Low_voltage" 2 "Rls_Over_voltage" 3 "Rls_Over_Temperature" 4 "Rls_communication_error" 5 "Rls_Hardware_fault" 6 "Not_determined" 7 "Invld";
VAL_ 616 RlsTopLiSnsrVal 32767 "Invalid";
VAL_ 616 RlsTopLiSnsrValUnit 0 "1lux" 1 "10lux" 2 "100lux" 3 "1000lux";
VAL_ 616 StsOfBSDLampRi 0 "Off" 1 "On" 2 "Err" 3 "Resd";
VAL_ 768 RSRLoPwrSplySts 0 "Off" 1 "On";
VAL_ 893 PassOcupcySts 0 "Empty" 1 "Occupied" 2 "Invaild_STG" 3 "Invaild_STB_OL";
VAL_ 342 ASCFltSts 0 "No_Fault" 1 "Level_control_restriction" 2 "Level_control_not_available" 3 "Level_control_not_available_caused_by_system_over_heated";
VAL_ 342 CDCFltSts 0 "No_Fault" 1 "Damper_control_restriction" 2 "Damper_control_not_available" 3 "Damper_control_not_available_caused_by_system_over_heated";
VAL_ 342 CurDampgCtrlMod 0 "Comfort" 1 "Normal" 2 "Sport" 3 "Battle";
VAL_ 342 ESPEnaReq 0 "No_Request" 1 "Request";
VAL_ 342 JackModSts 0 "Jack_Mode_OFF" 1 "Jack_Mode_ON";
VAL_ 342 LvlAdjmtSts 0 "No_action" 1 "Lowering" 2 "Lifting" 3 "Pending" 4 "Rear_lowering" 5 "Rear_lifting" 6 "Rear_pending";
VAL_ 342 LvlModAct 0 "EasyLoad" 1 "HL2" 2 "HL1" 3 "NL" 4 "LL1" 5 "LL2";
VAL_ 342 SCUExtmHeiSts 0 "Normal" 1 "Extreme_High" 2 "Extreme_Low";
VAL_ 342 SCULimSpdTqReq 0 "No_request" 1 "Request";
VAL_ 342 SCUWarnLampReq 0 "No_Request" 1 "Yellow_warning_light" 2 "Red_warning_light";
VAL_ 342 SCUWarnMsgASC 0 "NoRequest" 1 "SCU_ASC_SysFlt_OverHigh_空气悬架系统故障，车辆过高，请低速慢行" 2 "SCU_ASC_SysFlt_OverLow_空气悬架系统故障，车辆过低，离地间隙受限" 3 "SCU_ASC_SysFlt_空气悬架系统故障，请检修" 4 "Reserved0" 5 "SCU_ASC_Overheatd_空气悬架系统过热，请等待系统冷却" 6 "SCU_ASC_SystemFilling_空气悬架系统正在充气" 7 "Reserved";
VAL_ 342 SCUWarnMsgCDC 0 "NoRequest" 1 "SCU_CDC_SysFlt_电控减振系统故障，请检修" 2 "SCU_CDC_FcnLim_电控减振系统性能下降" 3 "Reserved";
VAL_ 182 FrntLeCurHeiSts 0 "InValid" 1 "Valid";
VAL_ 182 FrntRiCurHeiSts 0 "InValid" 1 "Valid";
VAL_ 182 ReLeCurHeiSts 0 "InValid" 1 "Valid";
VAL_ 182 ReRiCurHeiSts 0 "InValid" 1 "Valid";
VAL_ 419 SwtIndcrRaw 0 "Center" 1 "Up" 2 "UpUp" 3 "Dwn" 4 "DwnDwn" 5 "Invalid";
VAL_ 263 DateTiDay 0 "init";
VAL_ 263 DateTiHr 24 "Invalid";
VAL_ 263 DateTiMilsec 0 "0" 999 "999" 1000 "invalid";
VAL_ 263 DateTiMins 60 "Invalid";
VAL_ 263 DateTiMth 0 "Invalid";
VAL_ 263 DateTiSec 60 "Invalid";
VAL_ 263 DateTiYr 255 "Invalid";
VAL_ 263 TiDomn 0 "UTC_plus_0" 1 "UTC_plus_1" 2 "UTC_plus_2" 3 "UTC_plus_3" 4 "UTC_plus_4" 5 "UTC_plus_5" 6 "UTC_plus_6" 7 "UTC_plus_7" 8 "UTC_plus_8" 9 "UTC_plus_9" 10 "UTC_plus_10" 11 "UTC_plus_11" 12 "UTC_plus_12" 13 "UTC_plus_13" 14 "UTC_plus_14" 15 "UTC_plus_15" 16 "UTC_plus_16" 17 "UTC_plus_17" 18 "UTC_plus_18" 19 "UTC_plus_19" 20 "UTC_plus_20" 21 "UTC_plus_21" 22 "UTC_plus_22" 23 "UTC_plus_23" 24 "Invalid";
VAL_ 742 FrntLeTyrePVal 255 "Invalid";
VAL_ 742 FrntLeTyrePWarn 0 "Not_Active" 1 "Low_Pressure" 2 "High_Pressure" 3 "Invalid";
VAL_ 742 FrntRiTyrePVal 255 "Invalid";
VAL_ 742 FrntRiTyrePWarn 0 "Not_Active" 1 "Low_Pressure" 2 "High_Pressure" 3 "Invalid";
VAL_ 742 ReLeTyrePVal 255 "Invalid";
VAL_ 742 ReLeTyrePWarn 0 "Not_Active" 1 "Low_Pressure" 2 "High_Pressure" 3 "Invalid";
VAL_ 742 ReRiTyrePVal 255 "Invalid";
VAL_ 742 ReRiTyrePWarn 0 "Not_Active" 1 "Low_Pressure" 2 "High_Pressure" 3 "Invalid";
VAL_ 388 DiagcExtActv 0 "No" 1 "Yes";
VAL_ 388 DoorDrvrPwrRelsDlyActv 0 "Idle" 1 "Inactive" 2 "Active" 3 "Reserved";
VAL_ 388 DoorDrvrSts 0 "Ukwn" 1 "Opend" 2 "Clsd";
VAL_ 388 DoorLeRePwrRelsDlyActv 0 "Idle" 1 "Inactive" 2 "Active" 3 "Reserved";
VAL_ 388 DoorLeReSts 0 "Ukwn" 1 "Opend" 2 "Clsd";
VAL_ 388 DoorPassPwrRelsDlyActv 0 "Idle" 1 "Inactive" 2 "Active" 3 "Reserved";
VAL_ 388 DoorPassSts 0 "Ukwn" 1 "Opend" 2 "Clsd";
VAL_ 388 DoorRiRePwrRelsDlyActv 0 "Idle" 1 "Inactive" 2 "Active" 3 "Reserved";
VAL_ 388 DoorRiReSts 0 "Ukwn" 1 "Opend" 2 "Clsd";
VAL_ 388 ExtrMirrFoldEnaFailr 0 "NoFailr" 1 "VolNotOk" 2 "MotNotOk" 3 "VehSpdHigh" 4 "MotOverHeated" 5 "CmuErr" 6 "Reserved1";
VAL_ 388 ExtrMirrFoldSts 0 "MirrFoldStsTyp_MirrFoldPosnUndefd" 1 "MirrFoldStsTyp_MirrNotFoldPosn" 2 "MirrFoldStsTyp_MirrFoldPosn" 3 "MirrFoldStsTyp_MirrMovgToNotFold" 4 "MirrFoldStsTyp_MirrMovgToFold";
VAL_ 388 HoodOpenClsSts 0 "Ukwn" 1 "Open" 2 "Clsd";
VAL_ 388 LeMirrFoldCmd 0 "MirrFoldCmdTyp_Idle" 1 "MirrFoldCmdTyp_FoldIn" 2 "MirrFoldCmdTyp_FoldOut";
VAL_ 388 RiMirrFoldCmd 0 "MirrFoldCmdTyp_Idle" 1 "MirrFoldCmdTyp_FoldIn" 2 "MirrFoldCmdTyp_FoldOut";
VAL_ 388 TrOpenClsSts 0 "Ukwn" 1 "Open" 2 "Clsd";
VAL_ 388 VCUGearChgFailrSts 0 "No_Error" 1 "Unexpected_GearPosition";
VAL_ 388 VCUSpclRoadSurfTypForDisp 0 "default_normal_road" 1 "water_or_slippery" 2 "Ice" 3 "Compact_the_snow" 4 "Soft_Snow" 5 "rough_road_level_1" 6 "Rough_Road_Level_2" 7 "Rough_Road_Level_3";
VAL_ 514 ExtrLtgStsHiBeam 0 "Off" 1 "On" 2 "Err" 3 "Resd";
VAL_ 514 ExtrLtgStsLoBeam 0 "Off" 1 "On" 2 "Err" 3 "Resd";
VAL_ 514 ExtrLtgStsStop 0 "Off" 1 "On" 2 "Err" 3 "Resd";
VAL_ 514 ExtrLtgStsTurnIndrLe 0 "Off" 1 "On" 2 "Err" 3 "Resd";
VAL_ 514 ExtrLtgStsTurnIndrRi 0 "Off" 1 "On" 2 "Err" 3 "Resd";
VAL_ 514 LVPwrSplyBattErrSts 0 "no_fault" 1 "fault";
VAL_ 514 LVPwrSplyDCDCErrSts 0 "no_fault" 1 "fault";
VAL_ 514 LVPwrSplyHiErrSts 0 "no_fault" 1 "fault";
VAL_ 514 LVPwrSplyLoErrSts 0 "no_fault" 1 "fault";
VAL_ 514 OTALowEgy 0 "Release_Low_Energy_Request" 1 "Request_Enter_Low_Energy";
VAL_ 514 OTAMode 0 "OTA_Install_Mode_disable" 1 "OTA_Install_Mode_enable";
VAL_ 514 StsOfIndcr 0 "Noflash" 1 "flashLeft" 2 "flashRight" 3 "Doubleflash";
VAL_ 514 SwtIndcr 0 "Noflash" 1 "ShotFlashLeft" 2 "NormalFlashLeft" 3 "ShortFlashRight" 4 "NormalFlashRight";
VAL_ 514 SwtIndcrSts 0 "Noflash" 1 "FlashLeft" 2 "FlashRight";
VAL_ 514 VCUAccrPrmSetAllwd 0 "allowed" 1 "not_allowed";
VAL_ 514 VCUActDrvMod 0 "Comfort_Mode" 1 "Sport_Mode" 2 "Individual_Mode1" 3 "Individual_Mode2" 4 "Individual_Mode3" 5 "Snow_Mode" 6 "Mountain_Mode" 7 "Battle_Mode" 8 "Extreme_Eco_mode" 9 "Sport_plus_mode" 10 "Off_road_Mode" 11 "Wet_Mode" 12 "Standard_Mode" 13 "AntMtnsick_Mode";
VAL_ 514 VCUBatModAllwd 0 "allowed" 1 "not_allowed";
VAL_ 514 VCUBrkPedlFeelStAllwd 0 "allowed" 1 "not_allowed";
VAL_ 514 VCUDriftModSetSts 0 "not_active" 1 "active";
VAL_ 514 VCUDrvModStSts 0 "finished" 1 "in_process";
VAL_ 514 VCUExtmECOModStReq 0 "not_active" 1 "active";
VAL_ 514 VCUExtmPfmncMod 0 "Not_active" 1 "Active";
VAL_ 514 VCULnchPlusSts 0 "Not_active" 1 "Launch_Ready" 2 "Launch_Active";
VAL_ 514 VCUOnePedlModAllwd 0 "allowed" 1 "not_allowed";
VAL_ 514 VCURgnPrmSetAllwd 0 "allowed" 1 "not_allowed";
VAL_ 514 VCUSpdLimrSts 0 "Off" 1 "On";
VAL_ 514 VCUSteerAsstPrmSetAllwd 0 "allowed" 1 "not_allowed";
VAL_ 514 VCUSuspDampgPrmSetAllwd 0 "allowed" 1 "not_allowed";
VAL_ 514 VCUSuspLvlgPrm1Allwd 0 "allowed" 1 "not_allowed";
VAL_ 514 VCUSuspLvlgPrm2Allwd 0 "allowed" 1 "not_allowed";
VAL_ 514 VCUSuspLvlgPrm3Allwd 0 "allowed" 1 "not_allowed";
VAL_ 514 VCUSuspLvlgPrm4Allwd 0 "allowed" 1 "not_allowed";
VAL_ 514 VCUSuspLvlgPrm5Allwd 0 "allowed" 1 "not_allowed";
VAL_ 514 VCUTrlrModStSts 0 "not_active" 1 "active";
VAL_ 514 VCUWashModEntryAllwd 0 "allowed" 1 "not_allowed";
VAL_ 514 VCUWashModExtAllwd 0 "allowed" 1 "not_allowed";
VAL_ 514 VCUWashModStSts 0 "not_active" 1 "active";
VAL_ 689 AmbTEstimdVld 0 "Not_Valid" 1 "Valid";
VAL_ 689 EdsCircCooltTVld 0 "Not_Valid" 1 "Valid";
VAL_ 689 LockgCenLockSts 0 "Not_defined" 1 "Unlocked" 2 "Locked" 3 "Partially_unlocked";
VAL_ 689 OTALinkMgr 0 "服务可睡眠" 1 "服务唤醒且保持";
VAL_ 689 SetMgrDrvrSeldDstLvl 0 "NoGapSet" 1 "DistanceLevel1" 2 "DistanceLevel2" 3 "DistanceLevel3" 4 "DistanceLevel4" 5 "DistanceLevel5" 7 "Restore";
VAL_ 689 VCUEstimdCrsRng 2047 "Invalid";
VAL_ 689 VCUEstimdCrsRngVld 0 "invalid" 1 "valid";
VAL_ 689 VCUInsEgyCnsFlg 0 "Park_status" 1 "driving_status";
VAL_ 689 VCUPwrFlowForDisp 0 "no_display" 1 "Propulsion" 2 "Regenerartion";
VAL_ 868 SetMgrAdsACCInitSpdSwt 0 "invalid" 2 "CurrentVehSpd" 3 "CurrentSpdLmt" 7 "Restore";
VAL_ 868 SetMgrAdsAEBFCWSwt 0 "invalid" 2 "early" 3 "middle" 4 "late" 7 "Restore";
VAL_ 868 SetMgrAdsALCSwtSts 0 "invalid" 1 "Off" 2 "On" 7 "Restore";
VAL_ 868 SetMgrAdsAPA2SwtSts 0 "invalid" 1 "Off" 2 "ON" 7 "Restore";
VAL_ 868 SetMgrAdsAudModSwt 0 "invalid" 1 "Off" 2 "Escort" 3 "Nomal" 4 "Simple" 7 "Restore";
VAL_ 868 SetMgrAdsAutoTurnLiSwt 0 "invalid" 1 "Off" 2 "On" 7 "Restore";
VAL_ 868 SetMgrAdsAVPSwtSts 0 "invalid" 1 "Off" 2 "ON" 7 "Restore";
VAL_ 868 SetMgrAdsBSDLCASwt 0 "invalid" 2 "Off" 3 "AudWarning" 4 "HptcWarning" 5 "LightWarning" 7 "Restore";
VAL_ 868 SetMgrAdsCfgLoadReq 0 "No_Req" 1 "Request";
VAL_ 868 SetMgrAdsDOWSwt 0 "invalid" 1 "Off" 2 "Warning" 3 "Delayopen" 7 "Restore";
VAL_ 868 SetMgrAdsELKSwSts 0 "Invalid" 1 "Off" 2 "Middle" 3 "High" 7 "Restore";
VAL_ 868 SetMgrAdsFxdSpdModValSwt 0 "invalid" 1 "level_-15" 2 "level_-14" 3 "level_-13" 4 "level_-12" 5 "level_-11" 6 "level_-10" 7 "level_-9" 8 "level_-8" 9 "level_-7" 10 "level_-6" 11 "level_-5" 12 "level_-4" 13 "level_-3" 14 "level_-2" 15 "level_-1" 16 "level_0" 17 "level_1" 18 "level_2" 19 "level_3" 20 "level_4" 21 "level_5" 22 "level_6" 23 "level_7" 24 "level_8" 25 "level_9" 26 "level_10" 27 "level_11" 28 "level_12" 29 "level_13" 30 "level_14" 31 "level_15" 64 "Restore";
VAL_ 868 SetMgrAdsHPPBckGrLear 0 "invalid" 1 "Off" 2 "ON" 7 "Restore";
VAL_ 868 SetMgrAdsHPPSwtSts 0 "invalid" 1 "Off" 2 "ON" 7 "Restore";
VAL_ 868 SetMgrAdsIntelgntSpdSwt 0 "invalid" 1 "Off" 2 "On" 7 "Restore";
VAL_ 868 SetMgrAdsLaneChgCnfmSwt 0 "invalid" 1 "LaneChangeRecommended" 2 "autonomousLaneChange" 7 "Restore";
VAL_ 868 SetMgrAdsLDWPSwt 0 "invalid" 1 "Off" 2 "Warning" 3 "Warning_Prevention" 7 "Restore";
VAL_ 868 SetMgrAdsLDWPWarnTypSwt 0 "invalid" 1 "Audio" 2 "Haptic" 7 "Restore";
VAL_ 868 SetMgrAdsMAISwtSts 0 "default" 1 "unavailable" 2 "Off" 3 "On" 7 "restore";
VAL_ 868 SetMgrAdsModSwt 0 "invalid" 1 "ACC_Mode" 2 "LCC_Mode" 3 "NOA_Mode" 7 "Restore";
VAL_ 868 SetMgrAdsNOAHWSwtSts 0 "invalid" 1 "Off" 2 "ON" 7 "Restore";
VAL_ 868 SetMgrAdsNOAOddSwt 0 "invalid" 1 "Highway" 2 "Urban_road" 3 "Highway_and_Urban_road" 7 "Restore";
VAL_ 868 SetMgrAdsParkAudModSwt 0 "invalid" 1 "Off" 2 "Normal" 3 "Simple" 7 "Restore";
VAL_ 868 SetMgrAdsParkSpdSwtSts 0 "invalid" 1 "Standard" 2 "Fast" 7 "Restore";
VAL_ 868 SetMgrAdsPcntgeSpdlvlSwt 0 "invalid" 1 "level_-10" 2 "level_-9" 3 "level_-8" 4 "level_-7" 5 "level_-6" 6 "level_-5" 7 "level_-4" 8 "level_-3" 9 "level_-2" 10 "level_-1" 11 "level_0" 12 "level_1" 13 "level_2" 14 "level_3" 15 "level_4" 16 "level_5" 17 "level_6" 18 "level_7" 19 "level_8" 20 "level_9" 21 "level_10" 34 "Restore";
VAL_ 868 SetMgrAdsPltSwtSts 0 "invalid" 1 "Off" 2 "ON" 7 "Restore";
VAL_ 868 SetMgrAdsPntCldSwt 0 "invalid" 1 "Off" 2 "ON" 7 "Restore";
VAL_ 868 SetMgrAdsRCWSwt 0 "invalid" 1 "Off" 2 "ON" 7 "Restore";
VAL_ 868 SetMgrAdsTLASwt 0 "default" 2 "Off" 3 "On" 7 "Restore";
VAL_ 868 SetMgrAdsTrfcLiCtrlSwt 0 "invalid" 1 "Off" 2 "On" 7 "Restore";
VAL_ 868 SetMgrAdsVehDetourSwt 0 "invalid" 1 "Off" 2 "On" 7 "Restore";
VAL_ 868 SetMgrAdsVehSpdDvtnModSwt 0 "invalid" 1 "fixed_speed_mode" 2 "percentage_speed_mode" 7 "Restore";
VAL_ 868 VCUBattOverHeatWarn 0 "not_active" 1 "active";
VAL_ 868 VCUChrgnModSts 0 "Not_in_charging" 1 "In_preparation" 2 "Charging_in_progress" 3 "Charging_done" 4 "Charging_fault" 5 "Driving_charging" 6 "Charging_stop" 7 "Booking_charging_waiting" 8 "Preheating_in_process" 9 "Warming_in_progress";
VAL_ 868 VCUDrvMotFltWarn 0 "not_active" 1 "active";
VAL_ 868 VCUDrvMotOverHeatWarn 0 "Not_active" 1 "Active";
VAL_ 868 VCUDrvSysLimdWarn 0 "not_active" 1 "active";
VAL_ 868 VCUGearChgFailInde 0 "No_request" 1 "Please_brake" 2 "Vehicle_speed_high" 3 "Charging_plug_insertion" 4 "EPB_failure" 5 "E_motor_failure" 6 "Connect_the_key_and_press_SSB" 7 "Press_SSB" 8 "Show_Room_Keep_Park" 9 "LV_System_Failure" 10 "HV_System_Failure" 11 "Immobilizer_Not_Pass" 12 "Trailer_Mode_Not_Shift" 13 "Shifter_Failure";
VAL_ 868 VCUHvBattSysFltIndcr 0 "not_active" 1 "active";
VAL_ 868 VCUHvBattSysFltWarn 0 "not_active" 1 "active";
VAL_ 868 VCUHVExtPortConnectnTypInfo 0 "Non_connected" 1 "AC_Half_connected" 2 "AC_charger_conneccted" 3 "DC_charger_connected" 4 "Wireless_charger_connected" 5 "V2L_connected" 6 "V2V_connected" 7 "Multi_connection" 8 "Charger_connected_with_fault" 9 "DC_Half_connected";
VAL_ 868 VCUHvPwrSysCutOff 0 "not_active" 1 "active";
VAL_ 868 VCUHVSysFltWarnSts 0 "no_warning" 1 "reserved" 2 "HV_System_Fault_warning_Level2" 3 "reserved" 4 "HV_System_Fault_warning_Level4" 5 "HV_System_Fault_warning_Level5" 6 "HV_System_Fault_warning_Level6" 7 "reserved" 8 "HV_System_Fault_warning_Level8" 9 "HV_System_Fault_warning_Level9" 10 "reserved" 11 "reserved" 12 "reserved" 13 "reserved" 14 "reserved" 15 "reserved";
VAL_ 868 VCULoSocWarngMsg 0 "Not_active" 1 "Level1_warning" 2 "Level2_warning";
VAL_ 868 VCUPrpsnPwrDrt 0 "not_active" 1 "active";
VAL_ 868 VCUThermRunawayErrAlrm 0 "not_active" 1 "active";
VAL_ 868 VCUVehSysFltWarn 0 "not_active" 1 "active";
VAL_ 1023 VidBlkId 0 "Invalid" 1 "Block_1" 2 "Block_2" 3 "Block_3";
VAL_ 1023 VinVINBlkID 0 "Invalid" 1 "Block_1" 2 "Block_2" 3 "Block_3";
VAL_ 212 CarModSts 0 "Normal" 1 "Reserved1" 2 "Trsnp" 3 "Showroom" 4 "Dyno" 5 "TestDrv" 6 "Service" 7 "Reserved3";
VAL_ 212 DrvActvSts 0 "OFF" 1 "ON";
VAL_ 212 LockgCenLockTrigSrc 0 "NoTrigSrc" 1 "RKE_lock_or_unlock" 2 "Keyless_lock_or_unlock" 3 "Interior_buttons_lock_or_unlock" 4 "Speed_lock" 5 "Relocking_lock" 6 "NFC_lock_or_unlock" 7 "Telematics_lock_or_unlock" 8 "Crash_unlock" 9 "Approach_unlock" 10 "Walk_away_lock" 11 "Inside_Others_Unlock_or_lock" 12 "Outside_others_Unlock_or_lock" 13 "RPA_Unlock_or_lock" 14 "Thermal_Run_Away_Unlock";
VAL_ 212 LockgDrvrDoorLockCmd 0 "Idle" 1 "Unlock" 2 "Lock" 3 "Crash_unlock";
VAL_ 212 PwrModSts 0 "OFF" 1 "Awake" 2 "ACC" 3 "RUN";
VAL_ 212 PwrModVld 0 "Valid" 1 "NotValid";
VAL_ 212 VCUAccrPedlFlg 0 "not_active" 1 "active";
VAL_ 212 VCUAccrPedlRatVld 0 "invalid" 1 "valid";
VAL_ 212 VCUActGearLvr 0 "P_Park_gear" 1 "R_Reverse_gear" 2 "N_Neutral_gear" 3 "D_Drive_gear";
VAL_ 212 VCUActGearLvrVld 0 "Invalid" 1 "Valid";
VAL_ 212 VCUDrvOffFcnLim 0 "Normal;" 1 "PowerLimited_Fault.";
VAL_ 212 VCUFrntDesTqWoIntvVld 0 "Invalid" 1 "Valid";
VAL_ 212 VCUFrntEmTqRdy 0 "Not_ready" 1 "Ready";
VAL_ 212 VCUFrntMotActSpdVld 0 "Invalid" 1 "Valid";
VAL_ 212 VCUFrntMotActTqVld 0 "Invalid" 1 "Valid";
VAL_ 212 VCUFrntMotWhlTqReqVld 0 "Invalid" 1 "Valid";
VAL_ 212 VCUFrntWhlTqMaxAvlVld 0 "Invalid" 1 "Valid";
VAL_ 212 VCUFrntWhlTqMinAvlVld 0 "Invalid" 1 "Valid";
VAL_ 212 VCUGearLvrAvail 0 "Not_Available" 1 "Available";
VAL_ 212 VCUHVSt 0 "OFF" 1 "Precharge" 2 "HV_On" 3 "Fault";
VAL_ 212 VCULoSocLampReq 0 "Not_active" 1 "Active";
VAL_ 212 VCUPedlTqOvrdAdsFlg 0 "No" 1 "Yes";
VAL_ 212 VCUPrkgBtnPsd 0 "Not_Active" 1 "active";
VAL_ 212 VCUPrkgBtnPsdVld 0 "Invalid" 1 "Valid";
VAL_ 212 VCUPtRdyFlg 0 "not_active" 1 "active";
VAL_ 212 VCUReDesTqWoIntvVld 0 "Invalid" 1 "Valid";
VAL_ 212 VCUReEmTqRdy 0 "Not_ready" 1 "Ready";
VAL_ 212 VCUReMotActSpdVld 0 "Invalid" 1 "Valid";
VAL_ 212 VCUReMotActTqVld 0 "Invalid" 1 "Valid";
VAL_ 212 VCUReMotWhlTqReqVld 0 "Invalid" 1 "Valid";
VAL_ 212 VCUReWhlTqMaxAvlVld 0 "Invalid" 1 "Valid";
VAL_ 212 VCUReWhlTqMinAvlVld 0 "Invalid" 1 "Valid";
VAL_ 212 VCURLMotActTqVld 0 "Invalid" 1 "Valid";
VAL_ 212 VCURLMotWhlTqReqVld 0 "Invalid" 1 "Valid";
VAL_ 212 VCURRMotActTqVld 0 "Invalid" 1 "Valid";
VAL_ 212 VCURRMotWhlTqReqVld 0 "Invalid" 1 "Valid";
VAL_ 212 VCUStsModCst 0 "OPedl_No_RgL1" 1 "OPedl_No_RgL2" 2 "OPedl_No_RgL3" 3 "OPedl_No_RgL4" 4 "OPedl_No_RgL5" 5 "OPedl_No_ADASactive" 6 "OPedl_No_RoadGradientInhbit" 7 "OPedl_No_PowerDown" 16 "OPedl_Stop_RgL1" 17 "OPedl_Stop_RgL2" 18 "OPedl_Stop_RgL3" 19 "OPedl_Stop_RgL4" 20 "OPedl_Stop_RgL5" 21 "OPedl_Crp_RgL1" 22 "OPedl_Crp_RgL2" 23 "OPedl_Crp_RgL3" 24 "OPedl_Crp_RgL4" 25 "OPedl_Crp_RgL5" 26 "OPedl_FW_RgL1" 27 "OPedl_FW_RgL2" 28 "OPedl_FW_RgL3" 29 "OPedl_FW_RgL4" 30 "OPedl_FW_RgL5";
VAL_ 212 VCUTarGearLvr 0 "P_Park_gear" 1 "R_Reverse_gear" 2 "N_Neutral_gear" 3 "D_Drive_gear";
VAL_ 212 VCUTarGearLvrVld 0 "Invalid" 1 "Valid";
VAL_ 212 VCUVehMaxFltLvl 0 "No_Fault" 1 "FaultLevel1" 2 "FaultLevel2" 3 "FaultLevel3" 4 "FaultLevel4";
VAL_ 212 VCUVirtAccrPedlVld 0 "Invalid" 1 "Valid";
VAL_ 212 VCUWhlTqMaxAvlVld 0 "Not_validate" 1 "Valiate";
VAL_ 212 WiprSpdModSts 0 "OFF" 1 "Intermittent_wiping_request_LowSpeed" 2 "Intermittent_wiping_request_HighSpeed" 3 "Low_speed_wiping_request" 4 "High_speed_wiping_request" 5 "Auto_wiping_Speed" 6 "Reserved";
VAL_ 212 WipSpdReqHi 0 "OFF" 1 "ON";
VAL_ 212 WipSpdReqLo 0 "OFF" 1 "ON";
VAL_ 228 VehLatSpdEstdVld 0 "NotValid" 1 "Valid";
VAL_ 228 VehLgtSpdEstdVld 0 "NotValid" 1 "Valid";
VAL_ 389 AdasSwt 0 "Not_Pressed" 1 "Pressed" 2 "Error" 3 "Reserved";
VAL_ 389 AdasSwtSigGrpLinErr 0 "NoErr" 1 "CounterErr" 2 "CRCErr" 3 "CounterErr_CRCErr";
VAL_ 389 LeKnobCounter 255 "Invalid";
VAL_ 389 LeMFctActSgCe 0 "Not_Pressed" 1 "Pressed" 2 "Error" 3 "Reserved";
VAL_ 389 LeMFctActSgLe 0 "Not_Pressed" 1 "Pressed" 2 "Error" 3 "Reserved";
VAL_ 389 LeMFctActSgRi 0 "Not_Pressed" 1 "Pressed" 2 "Error" 3 "Reserved";
VAL_ 389 SwsLinComFltSts 0 "No_Fault" 1 "Node_Miss";
VAL_ 520 BMDMAcvDcnMosSt 0 "default" 1 "power_off" 2 "unable_to_perform_power_off" 3 "reserved";
VAL_ 520 RlsLinComFltSts 0 "No_Fault" 1 "Node_Miss";
VAL_ 1400 VCCDADDCANActiveWakeup 0 "passive_wakeup" 1 "active_Wakeup";
VAL_ 1400 VCCDADDCANRepeatMsgReq 0 "not_requested" 1 "requested";
VAL_ 1400 VCCDADDCANRepeatMsgSt 0 "Not_in_Repeat_Message_State" 1 "In_Repeat_Message_State";
SIG_GROUP_ 848 ACUWarnLampStsSigGrp 1 : ACUWarnLampSts ACUWarnLampStsSigGrpChks ACUWarnLampStsSigGrpCntr;
SIG_GROUP_ 389 AdasSwtSigGrp 1 : AdasSwt AdasSwtSigGrpChks AdasSwtSigGrpCntr AdasSwtSigGrpLinErr;
SIG_GROUP_ 932 APARPADrvrReqSigGrp 1 : DCD2RDParkinChoseButton DCDAPAButton DCDAPAParkOutDireSelect DCDAPAParkSlotSelect DCDAPAPIPOReq DCDAPAQuitReq;
SIG_GROUP_ 932 AVPHPPDrvrReqSigGrp 1 : ADSAPPOpenReq DCDBackMapDfltParkSlotReq DCDHPPChoseSaveRoute DCDHPPLrnReq DCDHPPParkAlTheWay DCDHPPParkingButton DCDHPPPrkReq;
SIG_GROUP_ 579 BattSocRawSigGrp 1 : BattSocRaw BattSocRawSigGrpChks BattSocRawSigGrpCntr;
SIG_GROUP_ 520 BattSohSigGrp 1 : BattSoh BattSohSigGrpChks BattSohSigGrpCntr;
SIG_GROUP_ 579 BattURawSigGrp 1 : BattURaw BattURawSigGrpChks BattURawSigGrpCntr;
SIG_GROUP_ 657 BLEM2VCCDForLocn1 1 : BLEM2VCCDForLocn10 BLEM2VCCDForLocn11 BLEM2VCCDForLocn12 BLEM2VCCDForLocn13 BLEM2VCCDForLocn14 BLEM2VCCDForLocn15 BLEM2VCCDForLocn16 BLEM2VCCDForLocn17 BLEM2VCCDForLocn18 BLEM2VCCDForLocn19 BLEM2VCCDForLocn1A BLEM2VCCDForLocn1B BLEM2VCCDForLocn1C BLEM2VCCDForLocn1D BLEM2VCCDForLocn1F;
SIG_GROUP_ 665 BLEM2VCCDForLocn2 1 : BLEM2VCCDForLocn20 BLEM2VCCDForLocn21 BLEM2VCCDForLocn22 BLEM2VCCDForLocn23 BLEM2VCCDForLocn24 BLEM2VCCDForLocn25 BLEM2VCCDForLocn26 BLEM2VCCDForLocn27 BLEM2VCCDForLocn28 BLEM2VCCDForLocn29 BLEM2VCCDForLocn2A BLEM2VCCDForLocn2B BLEM2VCCDForLocn2C BLEM2VCCDForLocn2D BLEM2VCCDForLocn2F;
SIG_GROUP_ 826 BLEM2VCCDForLocn3 1 : BLEM2VCCDForLocn30 BLEM2VCCDForLocn31 BLEM2VCCDForLocn32 BLEM2VCCDForLocn33 BLEM2VCCDForLocn34 BLEM2VCCDForLocn35 BLEM2VCCDForLocn36 BLEM2VCCDForLocn37 BLEM2VCCDForLocn38 BLEM2VCCDForLocn39 BLEM2VCCDForLocn3A BLEM2VCCDForLocn3B BLEM2VCCDForLocn3C BLEM2VCCDForLocn3D BLEM2VCCDForLocn3F;
SIG_GROUP_ 817 BLEM2VCCDForLocn4 1 : BLEM2VCCDForLocn40 BLEM2VCCDForLocn41 BLEM2VCCDForLocn42 BLEM2VCCDForLocn43 BLEM2VCCDForLocn44 BLEM2VCCDForLocn45 BLEM2VCCDForLocn46 BLEM2VCCDForLocn47 BLEM2VCCDForLocn48 BLEM2VCCDForLocn49 BLEM2VCCDForLocn4A BLEM2VCCDForLocn4B BLEM2VCCDForLocn4C BLEM2VCCDForLocn4D BLEM2VCCDForLocn4F;
SIG_GROUP_ 182 CurHeiSigGrp 1 : CurHeiSigGrpChks CurHeiSigGrpCntr FrntLeCurHei FrntLeCurHeiSts FrntRiCurHei FrntRiCurHeiSts ReLeCurHei ReLeCurHeiSts ReRiCurHei ReRiCurHeiSts;
SIG_GROUP_ 720 DCDDMSSigGrp 1 : DCDDMSCameraFltSts DCDDMSdstrctnSts DCDDMSfatgSts DCDDMSSigGrpChks DCDDMSSigGrpCntr DCDDMSSysFltSts;
SIG_GROUP_ 833 DCDNavSigGrp 1 : DCDAdCode DCDCameraSpdLim DCDNavSts DCDRoadClass DCDRoadFacSpdLim DCDRoadType DCDTrfcSts;
SIG_GROUP_ 837 DCDUserIDSigGrp 1 : DCDAccountLogTyp DCDAcctMod DCDCloudSysnc DCDCurProID DCDUserIDBytePos0 DCDUserIDBytePos1 DCDUserIDBytePos10 DCDUserIDBytePos11 DCDUserIDBytePos12 DCDUserIDBytePos13 DCDUserIDBytePos14 DCDUserIDBytePos15 DCDUserIDBytePos2 DCDUserIDBytePos3 DCDUserIDBytePos4 DCDUserIDBytePos5 DCDUserIDBytePos6 DCDUserIDBytePos7 DCDUserIDBytePos8 DCDUserIDBytePos9;
SIG_GROUP_ 892 DrvrOcupcyStsGroup 1 : DrvrOcupcySts DrvrOcupcyStsGroupChks DrvrOcupcyStsGroupCntr;
SIG_GROUP_ 212 FrntMotCtrlSigGrp 1 : FrntMotCtrlSigGrpChks FrntMotCtrlSigGrpCntr VCUFrntDesTqWoIntv VCUFrntDesTqWoIntvVld VCUFrntMotActSpd VCUFrntMotActSpdVld VCUFrntMotActTq VCUFrntMotActTqVld VCUFrntMotWhlTqReq VCUFrntMotWhlTqReqVld VCUFrntWhlTqMaxAvl VCUFrntWhlTqMaxAvlVld VCUFrntWhlTqMinAvl VCUFrntWhlTqMinAvlVld;
SIG_GROUP_ 607 HandOnDetnStsSigGrp 1 : HandOnDetnStsSigGrpChks HandOnDetnStsSigGrpCntr HandOnDetnStsSigGrpLinErr HandsOnDetectionErrorStatus HandsOnDetectionStatus;
SIG_GROUP_ 849 ImpctEvntStsSigGrp 1 : ImpctEvntSts ImpctEvntStsSigGrpChks ImpctEvntStsSigGrpCntr;
SIG_GROUP_ 689 InsEgyCnsSigGrp 1 : InsEgyCnsSigGrpChks InsEgyCnsSigGrpCntr VCUEgyCnsInCurDrvCyc VCUEstimdCrsRng VCUEstimdCrsRngForCltc VCUEstimdCrsRngVld VCUInsEgyCnsDurgDrvg VCUInsEgyCnsDurgStsl VCUInsEgyCnsFlg VCUPwrFlowForDisp;
SIG_GROUP_ 426 LatAccrYawRateSigGrp 1 : LatAccr LatAccrSt LatAccrYawRateSigGrpChks LatAccrYawRateSigGrpCntr YawRate YawRateSnsrSt;
SIG_GROUP_ 425 LonAccrSigGrp 1 : LonAccr LonAccrSigGrpChks LonAccrSigGrpCntr LonSnsrSt;
SIG_GROUP_ 833 LrnStsSigGrp 1 : ALCLrnSts AVPLrnSts HPPLrnSts LrnStsSigGrpChks LrnStsSigGrpCntr NOACtyLrnSts NOAHWLrnSts PltLrnSts;
SIG_GROUP_ 396 LRRSnsrWarnSigGrp 1 : LRRSnsrStsFrmSFC LRRSnsrWarnSigGrpChks LRRSnsrWarnSigGrpCntr;
SIG_GROUP_ 514 LVPwrSplyBattErrStsSigGrp 1 : LVPwrSplyBattErrSts LVPwrSplyBattErrStsSigGrpChks LVPwrSplyBattErrStsSigGrpCntr;
SIG_GROUP_ 514 LVPwrSplyHiErrStsSigGrp 1 : LVPwrSplyDCDCErrSts LVPwrSplyHiErrSts LVPwrSplyHiErrStsSigGrpChks LVPwrSplyHiErrStsSigGrpCntr;
SIG_GROUP_ 514 LVPwrSplyLoErrStsSigGrp 1 : LVPwrSplyLoErrSts LVPwrSplyLoErrStsSigGrpChks LVPwrSplyLoErrStsSigGrpCntr;
SIG_GROUP_ 514 ModAllwdSigGrp 1 : VCUAccrPrmSetAllwd VCUBatModAllwd VCUBrkPedlFeelStAllwd VCUDrvModRgnPrmSts VCUExtmECOModStReq VCUOnePedlModAllwd VCURgnPrmSetAllwd VCUSteerAsstPrmSetAllwd VCUSuspDampgPrmSetAllwd VCUSuspLvlgPrm1Allwd VCUSuspLvlgPrm2Allwd VCUSuspLvlgPrm3Allwd VCUSuspLvlgPrm4Allwd VCUSuspLvlgPrm5Allwd VCUWashModEntryAllwd VCUWashModExtAllwd;
SIG_GROUP_ 212 PwrModSigGrp 1 : PwrModSigGrpChks PwrModSigGrpCntr PwrModSts PwrModVld;
SIG_GROUP_ 434 PwrRelsMotDrvStsGrp 1 : DoorDrvrPwrRelsMotDrvSts PwrRelsMotDrvStsGrpChks PwrRelsMotDrvStsGrpCntr;
SIG_GROUP_ 212 ReMotCtrlSigGrp 1 : ReMotCtrlSigGrpChks ReMotCtrlSigGrpCntr VCUReDesTqWoIntv VCUReDesTqWoIntvVld VCUReMotActSpd VCUReMotActSpdVld VCUReMotActTq VCUReMotActTqVld VCUReMotWhlTqReq VCUReMotWhlTqReqVld VCUReWhlTqMaxAvl VCUReWhlTqMaxAvlVld VCUReWhlTqMinAvl VCUReWhlTqMinAvlVld VCURLMotActTq VCURLMotActTqVld VCURLMotWhlTqReq VCURLMotWhlTqReqVld VCURRMotActTq VCURRMotActTqVld VCURRMotWhlTqReq VCURRMotWhlTqReqVld VCUWhlTqMaxAvl VCUWhlTqMaxAvlVld;
SIG_GROUP_ 616 RlsLiSig1Grp 1 : RlsFwdLiSnsrVal RlsFwdLiSnsrValUnit RlsHudSnsrVal RlsHudSnsrValUnit RlsIRVal RlsLiSig1GrpChks RlsLiSig1GrpCntr RlsLiSnsrFwdFlt RlsLiSnsrIRFlt RlsLiSnsrTopFlt;
SIG_GROUP_ 616 RlsLiSig2Grp 1 : RlsLiSig2GrpChks RlsLiSig2GrpCntr RlsLiSigGrpLinErr RlsLiSwtReq RlsOutdBriSts RlsSts RlsTopLiSnsrVal RlsTopLiSnsrValUnit;
SIG_GROUP_ 368 RLSRBrkSigGrp 1 : RLSRBrkSigGrpChks RLSRBrkSigGrpCntr RLSRRCTBBrkReqFrmSFC RLSRRCTBTarDecelFrmSFC;
SIG_GROUP_ 701 RLSRSnsrWarnSigGrp 1 : RLSRSnsrStsFrmSFC RLSRSnsrWarnSigGrpChks RLSRSnsrWarnSigGrpCntr;
SIG_GROUP_ 391 RLSRWarnSigGrp 1 : RLSRBSDLCAStsFrmSFC RLSRBSDLCASwtFbFrmSFC RLSRBSDLCASwtUnavlRsnFrmSFC RLSRBSDLCAWarnReqFrmSFC RLSRDOWStsFrmSFC RLSRDOWSwtFbFrmSFC RLSRDOWSwtUnavlRsnFrmSFC RLSRDOWWarnReqFrFrmSFC RLSRDOWWarnReqReFrmSFC RLSRRCTABSwtFbFrmSFC RLSRRCTABSwtUnavlRsnFrmSFC RLSRRCTAStsFrmSFC RLSRRCTAWarnReqFrmSFC RLSRRCTBStsFrmSFC RLSRRCTBWarnReqFrmSFC RLSRRCWStsFrmSFC RLSRRCWSwtFbFrmSFC RLSRRCWSwtUnavlRsnFrmSFC RLSRRCWWarnReqFrmSFC RLSRWarnSigGrpChks RLSRWarnSigGrpCntr;
SIG_GROUP_ 383 RRSRBrkSigGrp 1 : RRSRBrkSigGrpChks RRSRBrkSigGrpCntr RRSRRCTBBrkReqFrmSFC RRSRRCTBTarDecelFrmSFC;
SIG_GROUP_ 523 RRSRSnsrWarnSigGrp 1 : RRSRSnsrStsFrmSFC RRSRSnsrWarnSigGrpChks RRSRSnsrWarnSigGrpCntr;
SIG_GROUP_ 392 RRSRWarnSigGrp 1 : RRSRBSDLCAStsFrmSFC RRSRBSDLCASwtFbFrmSFC RRSRBSDLCASwtUnavlRsnFrmSFC RRSRBSDLCAWarnReqFrmSFC RRSRDOWStsFrmSFC RRSRDOWSwtFbFrmSFC RRSRDOWSwtUnavlRsnFrmSFC RRSRDOWWarnReqFrFrmSFC RRSRDOWWarnReqReFrmSFC RRSRRCTABSwtFbFrmSFC RRSRRCTABSwtUnavlRsnFrmSFC RRSRRCTAStsFrmSFC RRSRRCTAWarnReqFrmSFC RRSRRCTBStsFrmSFC RRSRRCTBWarnReqFrmSFC RRSRRCWStsFrmSFC RRSRRCWSwtFbFrmSFC RRSRRCWSwtUnavlRsnFrmSFC RRSRRCWWarnReqFrmSFC RRSRWarnSigGrpChks RRSRWarnSigGrpCntr;
SIG_GROUP_ 342 SCUWarnSigGrp 1 : ASCFltSts CDCFltSts ESPEnaReq SCUExtmHeiSts SCULimSpdTqReq SCUWarnLampReq SCUWarnMsgASC SCUWarnMsgCDC SCUWarnSigGrpChks SCUWarnSigGrpCntr;
SIG_GROUP_ 388 SpclRoadSurfTypSigGrp 1 : SpclRoadSurfTypSigGrpChks SpclRoadSurfTypSigGrpCntr VCULatSlopForDisp VCULgtSlopForDisp VCUSpclRoadSurfTypForDisp;
SIG_GROUP_ 419 SwtIndcrRawSigGrp 1 : SwtIndcrRaw SwtIndcrRawSigGrpChks SwtIndcrRawSigGrpCntr;
SIG_GROUP_ 212 VCUActGearSigGrp 1 : VCUActGearLvr VCUActGearLvrVld VCUActGearSigGrpChks VCUActGearSigGrpCntr;
SIG_GROUP_ 212 VcuInpSigGrp 1 : VCUAccrPedlRat VCUAccrPedlRatVld VCUDrvOffFcnLim VCUFrntEmTqRdy VcuInpSigGrpChks VcuInpSigGrpCntr VCUPrkgBtnPsd VCUReEmTqRdy VCURgnTqCorrnFac VCUShifterMoveFlg VCUStsModCst VCUTarGearLvr VCUTarGearLvrVld VCUVirtAccrPedl VCUVirtAccrPedlVld;
SIG_GROUP_ 228 VDMVehSpdEstmGrp 1 : VDMLgtWhlSpdFL VDMLgtWhlSpdFR VDMLgtWhlSpdRL VDMLgtWhlSpdRR VDMVehSpdEstmGrpChks VDMVehSpdEstmGrpCntr VehBodySideSlipAng VehLatSpdEstd VehLatSpdEstdVld VehLgtSpdEstd VehLgtSpdEstdVld;
SIG_GROUP_ 135 VehCfgPrm 1 : VehCfgPrmBlkIDBytePosn1 VehCfgPrmCCPBytePosn2 VehCfgPrmCCPBytePosn3 VehCfgPrmCCPBytePosn4 VehCfgPrmCCPBytePosn5 VehCfgPrmCCPBytePosn6 VehCfgPrmCCPBytePosn7 VehCfgPrmCCPBytePosn8;
SIG_GROUP_ 868 VehSysFltWarnSigGrp 1 : VCUBattOverHeatWarn VCUDrvMotFltWarn VCUDrvMotOverHeatWarn VCUDrvSysLimdWarn VCUGearChgFailInde VCUHvBattSysFltIndcr VCUHvBattSysFltWarn VCUHvPwrSysCutOff VCUHVSysFltWarnSts VCULoSocWarngMsg VCUPrpsnPwrDrt VCUThermRunawayErrAlrm VCUVehSysFltWarn VehSysFltWarnSigGrpChks VehSysFltWarnSigGrpCntr;
SIG_GROUP_ 1023 Vid 1 : VidBlkId VidSignalPos1 VidSignalPos2 VidSignalPos3 VidSignalPos4 VidSignalPos5 VidSignalPos6 VidSignalPos7;
SIG_GROUP_ 212 WipSpdReqSigGrp 1 : WipSpdReqHi WipSpdReqLo WipSpdReqSigGrpChks WipSpdReqSigGrpCntr;
